[part 5 of 22: package /Cluster]
AUTOSAR XML (schema 4-3-0)
package /Cluster  (continued)
  can cluster E3V_K2CANFD: baudrate=500000, protocol-name=CAN, protocol-version=2.0, bus-off-recovery={bor-counter-l-1-to-l-2=1, bor-time-l-1=0.05, bor-time-l-2=0.2}, can-fd-baudrate=500000  (continued)
    can physical channel CHNL: comm-connectors=CN_E3V_K2CANFD  (continued)
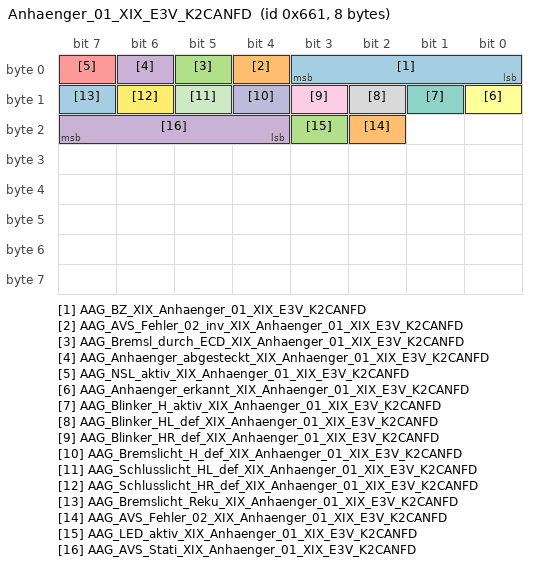
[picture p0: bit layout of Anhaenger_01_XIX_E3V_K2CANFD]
      frame Anhaenger_01_XIX_E3V_K2CANFD: id 0x661, to SAM, frame-length=8, can-addressing-mode=STANDARD, can-frame-rx-behavior=CAN-FD, can-frame-tx-behavior=CAN-FD
        pdu Anhaenger_01_XIX_E3V_K2CANFD: length=8, transmission-mode-true-timing=cyclic-timing={time-offset=0.0, time-period=0.1}, unused-bit-pattern=0  # ab MQB 7.2
          signal AAG_BZ_XIX_Anhaenger_01_XIX_E3V_K2CANFD: start 0, 4 bit, little-endian, data-type-policy=OVERRIDE, i-signal-type=PRIMITIVE, base-type=BT_AAG_BZ, compu {phys=raw for raw 0..15}, range phys 0..15, raw 0..15, transfer-property=PENDING  # 4bit-Botschaftszaehler, wird in jeder Sendebotschaft inkrementiert
          signal AAG_AVS_Fehler_02_inv_XIX_Anhaenger_01_XIX_E3V_K2CANFD: start 4, 1 bit, little-endian, data-type-policy=OVERRIDE, i-signal-type=PRIMITIVE, init-value=1, base-type=BT_AAG_AVS_Fehler_02_inv, invalid-value=Invalid_AAG_AVS_Fehler_02_inv_XIX_Anhaenger_01_XIX_E3V_K2CANFD:0, compu {0=Cx0_Fehler (CM_AAG_AVS_Fehler_02_inv_Cx0_Fehler), 1=Cx1_kein_Fehler (CM_AAG_AVS_Fehler_02_inv_Cx1_kein_Fehler)}, range raw 0..1, transfer-property=PENDING  # Fehler AVS (inverses Signal)
          signal AAG_Bremsl_durch_ECD_XIX_Anhaenger_01_XIX_E3V_K2CANFD: start 5, 1 bit, little-endian, data-type-policy=OVERRIDE, i-signal-type=PRIMITIVE, init-value=0, base-type=BT_AAG_Bremsl_durch_ECD, compu {0=Cx0_Bremslicht_ist_aus (CM_AAG_Bremsl_durch_ECD_Cx0_Bremslicht_ist_aus), 1=Cx1_Bremslicht_durch_ECD_aktiv (CM_AAG_Bremsl_durch_ECD_Cx1_Bremslicht_durch_ECD_aktiv)}, range raw 0..1, transfer-property=PENDING  # Bremslicht durch ECD aktiv
          signal AAG_Anhaenger_abgesteckt_XIX_Anhaenger_01_XIX_E3V_K2CANFD: start 6, 1 bit, little-endian, data-type-policy=OVERRIDE, i-signal-type=PRIMITIVE, init-value=0, base-type=BT_AAG_Anhaenger_abgesteckt, compu {0=Cx0_Init (CM_AAG_Anhaenger_abgesteckt_Cx0_Init), 1=Cx1_Anhaenger_wurde_bei_KL15_aus_abgesteckt (CM_AAG_Anhaenger_abgesteckt_Cx1_Anhaenger_wurde_bei_KL15_aus_abgesteckt)}, range raw 0..1, transfer-property=PENDING  # Anhaenger wurde bei Kl. 15 aus abgesteckt
          signal AAG_NSL_aktiv_XIX_Anhaenger_01_XIX_E3V_K2CANFD: start 7, 1 bit, little-endian, data-type-policy=OVERRIDE, i-signal-type=PRIMITIVE, init-value=0, base-type=BT_AAG_NSL_aktiv, compu {0=Cx0_Init (CM_AAG_NSL_aktiv_Cx0_Init), 1=Cx1_Anhaenger_Nebelschusslicht_aktiv (CM_AAG_NSL_aktiv_Cx1_Anhaenger_Nebelschusslicht_aktiv)}, range raw 0..1, transfer-property=PENDING  # Anhaenger Nebelschlusslicht aktiv
          signal AAG_Anhaenger_erkannt_XIX_Anhaenger_01_XIX_E3V_K2CANFD: start 8, 1 bit, little-endian, data-type-policy=OVERRIDE, i-signal-type=PRIMITIVE, init-value=0, base-type=BT_AAG_Anhaenger_erkannt, compu {0=Cx0_kein_Anhaenger_erkannt (CM_AAG_Anhaenger_erkannt_Cx0_kein_Anhaenger_erkannt), 1=Cx1_AAG_Anhaenger_erkannt (CM_AAG_Anhaenger_erkannt_Cx1_AAG_Anhaenger_erkannt)}, range raw 0..1, transfer-property=PENDING, to SAM(timeout 1 s)  # Erkennung Anhaenger
          signal AAG_Blinker_H_aktiv_XIX_Anhaenger_01_XIX_E3V_K2CANFD: start 9, 1 bit, little-endian, data-type-policy=OVERRIDE, i-signal-type=PRIMITIVE, init-value=0, base-type=BT_AAG_Blinker_H_aktiv, compu {0=Cx0_Init (CM_AAG_Blinker_H_aktiv_Cx0_Init), 1=Cx1_Anhaenger_Blinker_aktiv (CM_AAG_Blinker_H_aktiv_Cx1_Anhaenger_Blinker_aktiv)}, range raw 0..1, transfer-property=PENDING  # Status: Anhaenger Blinker aktiv
          signal AAG_Blinker_HL_def_XIX_Anhaenger_01_XIX_E3V_K2CANFD: start 10, 1 bit, little-endian, data-type-policy=OVERRIDE, i-signal-type=PRIMITIVE, init-value=0, base-type=BT_AAG_Blinker_HL_def, compu {0=Cx0_Init (CM_AAG_Blinker_HL_def_Cx0_Init), 1=Cx1_Anhaenger_Blinker_links_defekt (CM_AAG_Blinker_HL_def_Cx1_Anhaenger_Blinker_links_defekt)}, range raw 0..1, transfer-property=PENDING  # Anhaenger Blinker links defekt
          signal AAG_Blinker_HR_def_XIX_Anhaenger_01_XIX_E3V_K2CANFD: start 11, 1 bit, little-endian, data-type-policy=OVERRIDE, i-signal-type=PRIMITIVE, init-value=0, base-type=BT_AAG_Blinker_HR_def, compu {0=Cx0_Init (CM_AAG_Blinker_HR_def_Cx0_Init), 1=Cx1_Anhaenger_Blinker_rechts_defekt (CM_AAG_Blinker_HR_def_Cx1_Anhaenger_Blinker_rechts_defekt)}, range raw 0..1, transfer-property=PENDING  # Anhaenger Blinker rechts defekt
          signal AAG_Bremslicht_H_def_XIX_Anhaenger_01_XIX_E3V_K2CANFD: start 12, 1 bit, little-endian, data-type-policy=OVERRIDE, i-signal-type=PRIMITIVE, init-value=0, base-type=BT_AAG_Bremslicht_H_def, compu {0=Cx0_Init (CM_AAG_Bremslicht_H_def_Cx0_Init), 1=Cx1_Anhaenger_Bremslicht_defekt (CM_AAG_Bremslicht_H_def_Cx1_Anhaenger_Bremslicht_defekt)}, range raw 0..1, transfer-property=PENDING  # Anhaenger Bremslicht defekt
          signal AAG_Schlusslicht_HL_def_XIX_Anhaenger_01_XIX_E3V_K2CANFD: start 13, 1 bit, little-endian, data-type-policy=OVERRIDE, i-signal-type=PRIMITIVE, init-value=0, base-type=BT_AAG_Schlusslicht_HL_def, compu {0=Cx0_Init (CM_AAG_Schlusslicht_HL_def_Cx0_Init), 1=Cx1_Anhaenger_Schlusslicht_links_defekt (CM_AAG_Schlusslicht_HL_def_Cx1_Anhaenger_Schlusslicht_links_defekt)}, range raw 0..1, transfer-property=PENDING  # Anhaenger Schlußlicht links defekt
          signal AAG_Schlusslicht_HR_def_XIX_Anhaenger_01_XIX_E3V_K2CANFD: start 14, 1 bit, little-endian, data-type-policy=OVERRIDE, i-signal-type=PRIMITIVE, init-value=0, base-type=BT_AAG_Schlusslicht_HR_def, compu {0=Cx0_Init (CM_AAG_Schlusslicht_HR_def_Cx0_Init), 1=Cx1_Anhaenger_Schlusslicht_rechts_defekt (CM_AAG_Schlusslicht_HR_def_Cx1_Anhaenger_Schlusslicht_rechts_defekt)}, range raw 0..1, transfer-property=PENDING  # Anhaenger Schlußlicht rechts defekt
          signal AAG_Bremslicht_Reku_XIX_Anhaenger_01_XIX_E3V_K2CANFD: start 15, 1 bit, little-endian, data-type-policy=OVERRIDE, i-signal-type=PRIMITIVE, init-value=0, base-type=BT_AAG_Bremslicht_Reku, compu {0=Cx0_inaktiv (CM_AAG_Bremslicht_Reku_Cx0_inaktiv), 1=Cx1_aktiv (CM_AAG_Bremslicht_Reku_Cx1_aktiv)}, range raw 0..1, transfer-property=PENDING  # AAG_Bremslicht_Reku meldet zyklisch den empfangenen Zustand des CAN-Signals MO_Bremslicht_Reku zurück.
          signal AAG_AVS_Fehler_02_XIX_Anhaenger_01_XIX_E3V_K2CANFD: start 18, 1 bit, little-endian, data-type-policy=OVERRIDE, i-signal-type=PRIMITIVE, init-value=0, base-type=BT_AAG_AVS_Fehler_02, invalid-value=Invalid_AAG_AVS_Fehler_02_XIX_Anhaenger_01_XIX_E3V_K2CANFD:1, compu {0=Cx0_kein_Fehler (CM_AAG_AVS_Fehler_02_Cx0_kein_Fehler), 1=Cx1_Fehler (CM_AAG_AVS_Fehler_02_Cx1_Fehler)}, range raw 0..1, transfer-property=PENDING  # Fehler AVS
          signal AAG_LED_aktiv_XIX_Anhaenger_01_XIX_E3V_K2CANFD: start 19, 1 bit, little-endian, data-type-policy=OVERRIDE, i-signal-type=PRIMITIVE, init-value=0, base-type=BT_AAG_LED_aktiv, compu {0=Cx0_Lampen (CM_AAG_LED_aktiv_Cx0_Lampen), 1=Cx1_LED (CM_AAG_LED_aktiv_Cx1_LED)}, range raw 0..1, transfer-property=PENDING  # Dieses Signal sendet der Beleuchtungsart des Anhängers (LED oder Lampe) Bei LED aktiv erfolgt kein Kaltüberwachung
          signal AAG_AVS_Stati_XIX_Anhaenger_01_XIX_E3V_K2CANFD: start 20, 4 bit, little-endian, data-type-policy=OVERRIDE, i-signal-type=PRIMITIVE, init-value=0, base-type=BT_AAG_AVS_Stati, compu {0=Cx0_endlage_eingefahren_erreicht (CM_AAG_AVS_Stati_Cx0_endlage_eingefahren_erreicht), 1=Cx1_endlage_ausgefahren_erreicht (CM_AAG_AVS_Stati_Cx1_endlage_ausgefahren_erreicht), 2=Cx2_ausfahren_automatik (CM_AAG_AVS_Stati_Cx2_ausfahren_automatik), 3=Cx3_einfahren_automatik (CM_AAG_AVS_Stati_Cx3_einfahren_automatik), 4=Cx4_ausfahren_manuell (CM_AAG_AVS_Stati_Cx4_ausfahren_manuell), 5=Cx5_einfahren_manuell (CM_AAG_AVS_Stati_Cx5_einfahren_manuell), 6=Cx6_zwischenposition (CM_AAG_AVS_Stati_Cx6_zwischenposition), 7=Cx7_nicht_initialisiert (CM_AAG_AVS_Stati_Cx7_nicht_initialisiert)}, range raw 0..7, transfer-property=PENDING  # Status AVS (bei abnehmbarer oder mech.schwenkbarer Anhängerkupplung ist der Status immer 0)
      frame BAP_Aussenlicht2_ASG_01_XIX_E3V_K2CANFD: id 0x17336B00, to SAM, frame-length=8, can-addressing-mode=EXTENDED, can-frame-rx-behavior=CAN-FD, can-frame-tx-behavior=CAN-FD
        user defined pdu CDD_BAP_Aussenlicht2_ASG_01_XIX_E3V_K2CANFD: length=8, cdd-type=BAP
      frame BAP_Aussenlicht2_ASG_02_XIX_E3V_K2CANFD: id 0x17336B01, to SAM, frame-length=8, can-addressing-mode=EXTENDED, can-frame-rx-behavior=CAN-FD, can-frame-tx-behavior=CAN-FD
        user defined pdu CDD_BAP_Aussenlicht2_ASG_02_XIX_E3V_K2CANFD: length=8, cdd-type=BAP
      frame BAP_Aussenlicht2_FSG_01_XIX_E3V_K2CANFD: id 0x17336B10, from SAM, frame-length=8, can-addressing-mode=EXTENDED, can-frame-rx-behavior=CAN-FD, can-frame-tx-behavior=CAN-FD
        user defined pdu CDD_BAP_Aussenlicht2_FSG_01_XIX_E3V_K2CANFD: length=8, cdd-type=BAP
      frame BAP_Debug_Cmd_XIX_E3V_K2CANFD: id 0x1733FF20, to SAM, frame-length=8, can-addressing-mode=EXTENDED, can-frame-rx-behavior=CAN-FD, can-frame-tx-behavior=CAN-FD
        user defined pdu CDD_BAP_Debug_Cmd_XIX_E3V_K2CANFD: length=8, cdd-type=BAP
      frame BAP_Debug_Data_XIX_E3V_K2CANFD: id 0x1733FF30, from SAM, frame-length=8, can-addressing-mode=EXTENDED, can-frame-rx-behavior=CAN-FD, can-frame-tx-behavior=CAN-FD
        user defined pdu CDD_BAP_Debug_Data_XIX_E3V_K2CANFD: length=8, cdd-type=BAP
      frame BAP_Homelink_ASG_01_XIX_E3V_K2CANFD: id 0x17331400, to SAM, frame-length=8, can-addressing-mode=EXTENDED, can-frame-rx-behavior=CAN-FD, can-frame-tx-behavior=CAN-FD
        user defined pdu CDD_BAP_Homelink_ASG_01_XIX_E3V_K2CANFD: length=8, cdd-type=BAP
      frame BAP_Homelink_FSG_01_XIX_E3V_K2CANFD: id 0x17331410, from SAM, frame-length=8, can-addressing-mode=EXTENDED, can-frame-rx-behavior=CAN-FD, can-frame-tx-behavior=CAN-FD
        user defined pdu CDD_BAP_Homelink_FSG_01_XIX_E3V_K2CANFD: length=8, cdd-type=BAP
      frame BAP_Innenlicht_ASG_01_XIX_E3V_K2CANFD: id 0x17330800, to SAM, frame-length=8, can-addressing-mode=EXTENDED, can-frame-rx-behavior=CAN-FD, can-frame-tx-behavior=CAN-FD
        user defined pdu CDD_BAP_Innenlicht_ASG_01_XIX_E3V_K2CANFD: length=8, cdd-type=BAP
      frame BAP_Innenlicht_ASG_03_XIX_E3V_K2CANFD: id 0x17330802, to SAM, frame-length=8, can-addressing-mode=EXTENDED, can-frame-rx-behavior=CAN-FD, can-frame-tx-behavior=CAN-FD
        user defined pdu CDD_BAP_Innenlicht_ASG_03_XIX_E3V_K2CANFD: length=8, cdd-type=BAP
      frame BAP_Innenlicht_FSG_01_XIX_E3V_K2CANFD: id 0x17330810, from SAM, frame-length=8, can-addressing-mode=EXTENDED, can-frame-rx-behavior=CAN-FD, can-frame-tx-behavior=CAN-FD
        user defined pdu CDD_BAP_Innenlicht_FSG_01_XIX_E3V_K2CANFD: length=8, cdd-type=BAP
      frame BAP_SeatPneumatic_ASG_01_XIX_E3V_K2CANFD: id 0x17333B00, to SAM, frame-length=8, can-addressing-mode=EXTENDED, can-frame-rx-behavior=CAN-FD, can-frame-tx-behavior=CAN-FD
        user defined pdu CDD_BAP_SeatPneumatic_ASG_01_XIX_E3V_K2CANFD: length=8, cdd-type=BAP
      frame BAP_SeatPneumatic_ASG_02_XIX_E3V_K2CANFD: id 0x17333B01, to SAM, frame-length=8, can-addressing-mode=EXTENDED, can-frame-rx-behavior=CAN-FD, can-frame-tx-behavior=CAN-FD
        user defined pdu CDD_BAP_SeatPneumatic_ASG_02_XIX_E3V_K2CANFD: length=8, cdd-type=BAP
      frame BAP_SeatPneumatic_FSG_01_XIX_E3V_K2CANFD: id 0x17333B10, from SAM, frame-length=8, can-addressing-mode=EXTENDED, can-frame-rx-behavior=CAN-FD, can-frame-tx-behavior=CAN-FD
        user defined pdu CDD_BAP_SeatPneumatic_FSG_01_XIX_E3V_K2CANFD: length=8, cdd-type=BAP
      frame BAP_Wiper_ASG_01_XIX_E3V_K2CANFD: id 0x17330C00, to SAM, frame-length=8, can-addressing-mode=EXTENDED, can-frame-rx-behavior=CAN-FD, can-frame-tx-behavior=CAN-FD
        user defined pdu CDD_BAP_Wiper_ASG_01_XIX_E3V_K2CANFD: length=8, cdd-type=BAP
      frame BAP_Wiper_ASG_02_XIX_E3V_K2CANFD: id 0x17330C01, to SAM, frame-length=8, can-addressing-mode=EXTENDED, can-frame-rx-behavior=CAN-FD, can-frame-tx-behavior=CAN-FD
        user defined pdu CDD_BAP_Wiper_ASG_02_XIX_E3V_K2CANFD: length=8, cdd-type=BAP
      frame BAP_Wiper_FSG_01_XIX_E3V_K2CANFD: id 0x17330C10, from SAM, frame-length=8, can-addressing-mode=EXTENDED, can-frame-rx-behavior=CAN-FD, can-frame-tx-behavior=CAN-FD
        user defined pdu CDD_BAP_Wiper_FSG_01_XIX_E3V_K2CANFD: length=8, cdd-type=BAP
      frame BCM_01_XIX_E3V_K2CANFD: id 0x65A, from SAM, frame-length=8, can-addressing-mode=STANDARD, can-frame-rx-behavior=CAN-FD, can-frame-tx-behavior=CAN-FD
        pdu BCM_01_XIX_E3V_K2CANFD_E2E: length=8, minimum-delay=0.03, transmission-mode-true-timing=event-controlled-timing={number-of-repetitions=0, repetition-period=0.0}, unused-bit-pattern=0  # Fuer die Botschaft ist das Cyclic-Timing 1.0 zu verwenden.
          signal BCM_01_CRC_XIX_BCM_01_XIX_E3V_K2CANFD: start 0, 8 bit, little-endian, data-type-policy=OVERRIDE, i-signal-type=PRIMITIVE, base-type=BT_BCM_01_CRC, compu {phys=raw for raw 0..255}, range phys 0..255, raw 0..255  # Für MLB: "Berechnung siehe Lastenheft "Kommunikationsabsicherung für FlexRay und CAN"" Ab MQB und MLBevo: "Berechnung siehe Lastenheft "End-to-End Kommunikationsabsicherung"" Endwerte siehe Begleitdokument "S-PDU Kennungsfolgen"
          signal BCM_01_BZ_XIX_BCM_01_XIX_E3V_K2CANFD: start 8, 4 bit, little-endian, data-type-policy=OVERRIDE, i-signal-type=PRIMITIVE, base-type=BT_BCM_01_BZ, compu {phys=raw for raw 0..15}, range phys 0..15, raw 0..15  # 4bit Botschaftszaehler; wird in jeder Sendebotschaft inkrementiert
          signal BCM_Bremsbelag_Sensor_XIX_BCM_01_XIX_E3V_K2CANFD: start 12, 1 bit, little-endian, data-type-policy=OVERRIDE, i-signal-type=PRIMITIVE, init-value=0, base-type=BT_BCM_Bremsbelag_Sensor, compu {0=Cx0_OK (CM_BCM_Bremsbelag_Sensor_Cx0_OK), 1=Cx1_Bremsbelag_unter_min (CM_BCM_Bremsbelag_Sensor_Cx1_Bremsbelag_unter_min)}, range raw 0..1  # Sensorsignal der Stromschleife für Bremsbelagverschleiß aktuell, entstört, unbewertet
          signal BCM_Bremsfluessigkeit_Sensor_XIX_BCM_01_XIX_E3V_K2CANFD: start 13, 1 bit, little-endian, data-type-policy=OVERRIDE, i-signal-type=PRIMITIVE, init-value=0, base-type=BT_BCM_Bremsfluessigkeit_Sensor, compu {0=Cx0_OK (CM_BCM_Bremsfluessigkeit_Sensor_Cx0_OK), 1=Cx1_Bremsfluessigkeit_unter_min (CM_BCM_Bremsfluessigkeit_Sensor_Cx1_Bremsfluessigkeit_unter_min)}, range raw 0..1  # Kontaktsignal des Sensorschalters für die Bremsflüssigkeitsreserve aktuell, entstört, unbewertet
          signal ISignalVoid_BCM_01_XIX_E3V_K2CANFD_0: start 14, 1 bit, little-endian, system signal SignalVoid_BCM_01_0, data-type-policy=OVERRIDE, i-signal-type=PRIMITIVE, base-type=BT_SignalVoid
          signal BCM_Waschwasser_Sensor_XIX_BCM_01_XIX_E3V_K2CANFD: start 15, 1 bit, little-endian, data-type-policy=OVERRIDE, i-signal-type=PRIMITIVE, init-value=0, base-type=BT_BCM_Waschwasser_Sensor, compu {0=Cx0_OK (CM_BCM_Waschwasser_Sensor_Cx0_OK), 1=Cx1_Waschwasser_unter_min (CM_BCM_Waschwasser_Sensor_Cx1_Waschwasser_unter_min)}, range raw 0..1  # Signal der Sensorelektroden für die Waschwasserreserve aktuell, entstört, bewertet (OK/Mangel)
          signal BCM_Kuehlmittel_Sensor_XIX_BCM_01_XIX_E3V_K2CANFD: start 16, 1 bit, little-endian, data-type-policy=OVERRIDE, i-signal-type=PRIMITIVE, init-value=0, base-type=BT_BCM_Kuehlmittel_Sensor, compu {0=Cx0_OK (CM_BCM_Kuehlmittel_Sensor_Cx0_OK), 1=Cx1_Kuehlmittel_unter_min (CM_BCM_Kuehlmittel_Sensor_Cx1_Kuehlmittel_unter_min)}, range raw 0..1  # Signal der Sensorelektroden für die Kühlmittelreserve aktuell, entstört, bewertet (OK/Mangel)
          signal BCM1_Kl_15_HW_erkannt_XIX_BCM_01_XIX_E3V_K2CANFD: start 17, 1 bit, little-endian, data-type-policy=OVERRIDE, i-signal-type=PRIMITIVE, init-value=0, base-type=BT_BCM1_Kl_15_HW_erkannt, compu {1=Cx1_Klemme_15_erkannt (CM_BCM1_Kl_15_HW_erkannt_Cx1_Klemme_15_erkannt) (Klemme 15 erkannt)}, range raw 1  # Erkennung Klemme 15 (Hardware) vom BCM1
          signal BCM1_Kl_15_Sig_HW_erkannt_XIX_BCM_01_XIX_E3V_K2CANFD: start 18, 1 bit, little-endian, data-type-policy=OVERRIDE, i-signal-type=PRIMITIVE, init-value=0, base-type=BT_BCM1_Kl_15_Sig_HW_erkannt, compu {0=Cx0_KL15_HW_Signal_von_BCM1_nicht_erkannt (CM_BCM1_Kl_15_Sig_HW_erkannt_Cx0_KL15_HW_Signal_von_BCM1_nicht_erkannt), 1=Cx1_KL15_HW_Signal_von_BCM1_erkannt (CM_BCM1_Kl_15_Sig_HW_erkannt_Cx1_KL15_HW_Signal_von_BCM1_erkannt)}, range raw 0..1  # Erkennung Klemme 15 Signal (Hardware) vom BCM1
          signal BCM_Kuehlmittel_Sensor_02_XIX_BCM_01_XIX_E3V_K2CANFD: start 19, 1 bit, little-endian, data-type-policy=OVERRIDE, i-signal-type=PRIMITIVE, init-value=0, base-type=BT_BCM_Kuehlmittel_Sensor_02, compu {0=Cx0_OK (CM_BCM_Kuehlmittel_Sensor_02_Cx0_OK), 1=Cx1_Kuehlmittel_unter_min (CM_BCM_Kuehlmittel_Sensor_02_Cx1_Kuehlmittel_unter_min)}, range raw 0..1  # Signal der zweiten Sensorelektroden für die Kühlmittelreserve aktuell, entstört, bewertet (OK/Mangel)
          signal ISignalVoid_BCM_01_XIX_E3V_K2CANFD_1: start 20, 1 bit, little-endian, system signal SignalVoid_BCM_01_1, data-type-policy=OVERRIDE, i-signal-type=PRIMITIVE, base-type=BT_SignalVoid
          signal BCM_Offroad_Taste_XIX_BCM_01_XIX_E3V_K2CANFD: start 21, 1 bit, little-endian, data-type-policy=OVERRIDE, i-signal-type=PRIMITIVE, init-value=0, base-type=BT_BCM_Offroad_Taste, compu {0=Cx0_Taster_nicht_betaetigt (CM_BCM_Offroad_Taste_Cx0_Taster_nicht_betaetigt), 1=Cx1_Taster_betaetigt (CM_BCM_Offroad_Taste_Cx1_Taster_betaetigt)}, range raw 0..1  # Betätigung der Offroad-Taste
          signal BCM_Charisma_Taste2_XIX_BCM_01_XIX_E3V_K2CANFD: start 22, 1 bit, little-endian, data-type-policy=OVERRIDE, i-signal-type=PRIMITIVE, init-value=0, base-type=BT_BCM_Charisma_Taste2, compu {0=Cx0_nicht_betaetigt (CM_BCM_Charisma_Taste2_Cx0_nicht_betaetigt), 1=Cx1_betaetigt (CM_BCM_Charisma_Taste2_Cx1_betaetigt)}, range raw 0..1  # Betätigung der Charisma-Taste 2
          signal BCM_Hybrid_StSt_Taste_Fehler_XIX_BCM_01_XIX_E3V_K2CANFD: start 23, 1 bit, little-endian, data-type-policy=OVERRIDE, i-signal-type=PRIMITIVE, init-value=0, base-type=BT_BCM_Hybrid_StSt_Taste_Fehler, compu {0=Cx0_kein_Fehler_StSt_Taster (CM_BCM_Hybrid_StSt_Taste_Fehler_Cx0_kein_Fehler_StSt_Taster), 1=Cx1_Fehler_StSt_Taster (CM_BCM_Hybrid_StSt_Taste_Fehler_Cx1_Fehler_StSt_Taster)}, range raw 0..1  # Fehlerflag, wenn Tasterdiagnose im BCM für den StSt-Taster anschlägt.
          signal BCM_Hybrid_StartStopp_Taste_XIX_BCM_01_XIX_E3V_K2CANFD: start 24, 1 bit, little-endian, data-type-policy=OVERRIDE, i-signal-type=PRIMITIVE, init-value=0, base-type=BT_BCM_Hybrid_StartStopp_Taste, compu {0=Cx0_nicht_betaetigt (CM_BCM_Hybrid_StartStopp_Taste_Cx0_nicht_betaetigt), 1=Cx1_betaetigt (CM_BCM_Hybrid_StartStopp_Taste_Cx1_betaetigt)}, range raw 0..1  # Betaetigung Taster "Hybrid" oder alternativ Taster "Start/Stopp Deaktivierung", je nach Verbau
          signal BCM1_Warnblink_Taster_XIX_BCM_01_XIX_E3V_K2CANFD: start 25, 1 bit, little-endian, data-type-policy=OVERRIDE, i-signal-type=PRIMITIVE, init-value=0, base-type=BT_BCM1_Warnblink_Taster, compu {0=Cx0_nicht_betaetigt (CM_BCM1_Warnblink_Taster_Cx0_nicht_betaetigt), 1=Cx1_betaetigt (CM_BCM1_Warnblink_Taster_Cx1_betaetigt)}, range raw 0..1  # Warnblinktaster
          signal BCM1_Valet_Parking_Taster_XIX_BCM_01_XIX_E3V_K2CANFD: start 26, 1 bit, little-endian, data-type-policy=OVERRIDE, i-signal-type=PRIMITIVE, init-value=0, base-type=BT_BCM1_Valet_Parking_Taster, compu {0=Cx0_nicht_betaetigt (CM_BCM1_Valet_Parking_Taster_Cx0_nicht_betaetigt), 1=Cx1_betaetigt (CM_BCM1_Valet_Parking_Taster_Cx1_betaetigt)}, range raw 0..1  # Valet Parking Taster
          signal ISignalVoid_BCM_01_XIX_E3V_K2CANFD_2: start 27, 3 bit, little-endian, system signal SignalVoid_BCM_01_2, data-type-policy=OVERRIDE, i-signal-type=PRIMITIVE, base-type=BT_SignalVoid
          signal BCM1_Rueckfahrlicht_Schalter_XIX_BCM_01_XIX_E3V_K2CANFD: start 30, 1 bit, little-endian, data-type-policy=OVERRIDE, i-signal-type=PRIMITIVE, init-value=0, base-type=BT_BCM1_Rueckfahrlicht_Schalter, compu {0=Cx0_nicht_betaetigt (CM_BCM1_Rueckfahrlicht_Schalter_Cx0_nicht_betaetigt), 1=Cx1_betaetigt (CM_BCM1_Rueckfahrlicht_Schalter_Cx1_betaetigt)}, range raw 0..1  # Rückfahrlichtschalter ab MQB/ MLBevo: Die Ganginformation wird unentprellt übertragen, im AT-Getriebe wird evtl. kurzzeitig der R-Gang angezeigt. Eine Entprellung muß im Empfänger erfolgen (typisch 400ms).
          signal BCM1_MH_Schalter_XIX_BCM_01_XIX_E3V_K2CANFD: start 31, 1 bit, little-endian, data-type-policy=OVERRIDE, i-signal-type=PRIMITIVE, init-value=0, base-type=BT_BCM1_MH_Schalter, compu {0=Cx0_MH_geschlossen (CM_BCM1_MH_Schalter_Cx0_MH_geschlossen), 1=Cx1_MH_offen (CM_BCM1_MH_Schalter_Cx1_MH_offen)}, range raw 0..1  # Motorhaubenkontakt
          signal BCM1_MH_WIV_Schalter_XIX_BCM_01_XIX_E3V_K2CANFD: start 32, 1 bit, little-endian, data-type-policy=OVERRIDE, i-signal-type=PRIMITIVE, init-value=0, base-type=BT_BCM1_MH_WIV_Schalter, compu {0=Cx0_MH_geschlossen (CM_BCM1_MH_WIV_Schalter_Cx0_MH_geschlossen), 1=Cx1_MH_offen (CM_BCM1_MH_WIV_Schalter_Cx1_MH_offen)}, range raw 0..1  # Bewerteter Motorhaubenkontakt fuer WIV
          signal BCM_Eco_Charisma_Taste_XIX_BCM_01_XIX_E3V_K2CANFD: start 33, 1 bit, little-endian, data-type-policy=OVERRIDE, i-signal-type=PRIMITIVE, init-value=0, base-type=BT_BCM_Eco_Charisma_Taste, compu {0=Cx0_nicht_betaetigt (CM_BCM_Eco_Charisma_Taste_Cx0_nicht_betaetigt), 1=Cx1_betaetigt (CM_BCM_Eco_Charisma_Taste_Cx1_betaetigt)}, range raw 0..1  # Betätigung Taster ECO alias BlueKey oder Charisma
          signal BCM1_NV_Taster_XIX_BCM_01_XIX_E3V_K2CANFD: start 34, 1 bit, little-endian, data-type-policy=OVERRIDE, i-signal-type=PRIMITIVE, init-value=0, base-type=BT_BCM1_NV_Taster, compu {0=Cx0_Taster_nicht_betaetigt (CM_BCM1_NV_Taster_Cx0_Taster_nicht_betaetigt), 1=Cx1_Taster_betaetigt (CM_BCM1_NV_Taster_Cx1_Taster_betaetigt)}, range raw 0..1  # BCM1_NV_Taster gibt an, ob der NightVision-Taster im Lichtdrehschalter-Modul aktuell betaetigt wird.
          signal BCM1_AFS_Lampe_XIX_BCM_01_XIX_E3V_K2CANFD: start 35, 1 bit, little-endian, data-type-policy=OVERRIDE, i-signal-type=PRIMITIVE, init-value=0, base-type=BT_BCM1_AFS_Lampe, compu {0=Cx0_Aus (CM_BCM1_AFS_Lampe_Cx0_Aus), 1=Cx1_Ein (CM_BCM1_AFS_Lampe_Cx1_Ein)}, range raw 0..1  # Ansteuerung der AFS-Fehlermeldung im Kombi
          signal BCM1_Reisemodus_Texte_XIX_BCM_01_XIX_E3V_K2CANFD: start 36, 2 bit, little-endian, data-type-policy=OVERRIDE, i-signal-type=PRIMITIVE, init-value=0, base-type=BT_BCM1_Reisemodus_Texte, compu {0=Cx0_keine_Anzeige (CM_BCM1_Reisemodus_Texte_Cx0_keine_Anzeige), 1=Cx1_Umschaltung_auf_Linksverkehr_aktiv (CM_BCM1_Reisemodus_Texte_Cx1_Umschaltung_auf_Linksverkehr_aktiv), 2=Cx2_Umschaltung_auf_Rechtsverkehr_aktiv (CM_BCM1_Reisemodus_Texte_Cx2_Umschaltung_auf_Rechtsverkehr_aktiv)}, range raw 0..2  # Ansteuerung der Reisemodus-Texte im Kombi
          signal ISignalVoid_BCM_01_XIX_E3V_K2CANFD_3: start 38, 2 bit, little-endian, system signal SignalVoid_BCM_01_3, data-type-policy=OVERRIDE, i-signal-type=PRIMITIVE, base-type=BT_SignalVoid
          signal Gong_TFL_Umschaltung_XIX_BCM_01_XIX_E3V_K2CANFD: start 40, 1 bit, little-endian, data-type-policy=OVERRIDE, i-signal-type=PRIMITIVE, init-value=0, base-type=BT_Gong_TFL_Umschaltung, compu {0=Cx0_kein_Gong (CM_Gong_TFL_Umschaltung_Cx0_kein_Gong), 1=Cx1_Gong_einmalig (CM_Gong_TFL_Umschaltung_Cx1_Gong_einmalig)}, range raw 0..1  # Aktivierung / Deaktivierung des TFL per Affengriff wird mit einem Gong im Kombi quittiert.
          signal ISignalVoid_BCM_01_XIX_E3V_K2CANFD_4: start 41, 1 bit, little-endian, system signal SignalVoid_BCM_01_4, data-type-policy=OVERRIDE, i-signal-type=PRIMITIVE, base-type=BT_SignalVoid
          signal BCM_ValetTaster_Fkts_LED_XIX_BCM_01_XIX_E3V_K2CANFD: start 42, 1 bit, little-endian, data-type-policy=OVERRIDE, i-signal-type=PRIMITIVE, init-value=0, base-type=BT_BCM_ValetTaster_Fkts_LED, compu {0=Cx0_LED_aus (CM_BCM_ValetTaster_Fkts_LED_Cx0_LED_aus), 1=Cx1_LED_ein (CM_BCM_ValetTaster_Fkts_LED_Cx1_LED_ein)}, range raw 0..1  # Im MQB beschreibt das Signal nur den Zustand der Funktion Valet Parking (aktiv/ inaktiv) Im MLBevo wird über das Signal zusätzlich die ValetTaster_Fkts_LED (an/ aus) gesteuert
          signal LRH_Taster_XIX_BCM_01_XIX_E3V_K2CANFD: start 43, 1 bit, little-endian, data-type-policy=OVERRIDE, i-signal-type=PRIMITIVE, init-value=0, base-type=BT_LRH_Taster, compu {0=Cx0_nicht_betaetigt (CM_LRH_Taster_Cx0_nicht_betaetigt), 1=Cx1_betaetigt (CM_LRH_Taster_Cx1_betaetigt)}, range raw 0..1  # Tasterbetätigung Lenkradheizung
          signal APS_Tongeber_defekt_XIX_BCM_01_XIX_E3V_K2CANFD: start 44, 1 bit, little-endian, data-type-policy=OVERRIDE, i-signal-type=PRIMITIVE, init-value=0, base-type=BT_APS_Tongeber_defekt, compu {0=Cx0_iO (CM_APS_Tongeber_defekt_Cx0_iO), 1=Cx1_defekt (CM_APS_Tongeber_defekt_Cx1_defekt)}, range raw 0..1  # Status APS-Tongeber zur HMI-Ansteuerng der RCTA-Funktion
          signal BCM1_EasyEntry_Status_XIX_BCM_01_XIX_E3V_K2CANFD: start 45, 1 bit, little-endian, data-type-policy=OVERRIDE, i-signal-type=PRIMITIVE, init-value=0, base-type=BT_BCM1_EasyEntry_Status, compu {0=Cx0_Aus (CM_BCM1_EasyEntry_Status_Cx0_Aus), 1=Cx1_Ein (CM_BCM1_EasyEntry_Status_Cx1_Ein)}, range raw 0..1  # Status EasyEntry für Lenksäule (wird auch von IVB verwendet)
          signal BCM1_Lenksaeule_aktiv_XIX_BCM_01_XIX_E3V_K2CANFD: start 46, 1 bit, little-endian, data-type-policy=OVERRIDE, i-signal-type=PRIMITIVE, init-value=0, base-type=BT_BCM1_Lenksaeule_aktiv, compu {0=Cx0_Lenksaeulenverstellung_nicht_aktiv (CM_BCM1_Lenksaeule_aktiv_Cx0_Lenksaeulenverstellung_nicht_aktiv) (Lenksaeulenverstellung nicht aktiv), 1=Cx1_Lenksaeulenverstellung_aktiv (CM_BCM1_Lenksaeule_aktiv_Cx1_Lenksaeulenverstellung_aktiv) (Lenksaeulenverstellung aktiv)}, range raw 0..1  # Lenksaeulenverstellung aktiv
          signal BCM1_Spannungs_Anf_XIX_BCM_01_XIX_E3V_K2CANFD: start 47, 2 bit, little-endian, data-type-policy=OVERRIDE, i-signal-type=PRIMITIVE, init-value=0, base-type=BT_BCM1_Spannungs_Anf, compu {0=Cx0_keine_Anforderung (CM_BCM1_Spannungs_Anf_Cx0_keine_Anforderung), 1=Cx1_Anforderung_Stufe_1 (CM_BCM1_Spannungs_Anf_Cx1_Anforderung_Stufe_1), 2=Cx2_Anforderung_Stufe_2 (CM_BCM1_Spannungs_Anf_Cx2_Anforderung_Stufe_2), 3=Cx3_Anforderung_Stufe_3 (CM_BCM1_Spannungs_Anf_Cx3_Anforderung_Stufe_3)}, range raw 0..3  # Forderung des BCM1-SG's zur Spannungsanhebung.
          signal ISignalVoid_BCM_01_XIX_E3V_K2CANFD_5: start 49, 7 bit, little-endian, system signal SignalVoid_BCM_01_5, data-type-policy=OVERRIDE, i-signal-type=PRIMITIVE, base-type=BT_SignalVoid
          signal ISignalVoid_BCM_01_XIX_E3V_K2CANFD_6: start 56, 2 bit, little-endian, system signal SignalVoid_BCM_01_6, data-type-policy=OVERRIDE, i-signal-type=PRIMITIVE, base-type=BT_SignalVoid
          signal BCM_Anf_AAW_MoLaWa_XIX_BCM_01_XIX_E3V_K2CANFD: start 58, 2 bit, little-endian, data-type-policy=OVERRIDE, i-signal-type=PRIMITIVE, init-value=0, base-type=BT_BCM_Anf_AAW_MoLaWa, compu {0=Cx0_Init (CM_BCM_Anf_AAW_MoLaWa_Cx0_Init), 1=Cx1_AAW_angefordert (CM_BCM_Anf_AAW_MoLaWa_Cx1_AAW_angefordert), 2=Cx2_MoLaWa_angefordert (CM_BCM_Anf_AAW_MoLaWa_Cx2_MoLaWa_angefordert)}, range raw 0..2  # Signal zur Anforderung der Antrieb-Aktiv-Warnung und Motorlaufwarnung. Die Berechnung erfolgt im BCM. Die Ausgabe der Warnungen wird vom Kombiinstrument realisiert
          signal BCM_Handbremse_Hinweis_XIX_BCM_01_XIX_E3V_K2CANFD: start 60, 1 bit, little-endian, data-type-policy=OVERRIDE, i-signal-type=PRIMITIVE, init-value=0, base-type=BT_BCM_Handbremse_Hinweis, compu {0=Cx0_inaktiv (CM_BCM_Handbremse_Hinweis_Cx0_inaktiv), 1=Cx1_aktiv (CM_BCM_Handbremse_Hinweis_Cx1_aktiv)}, range raw 0..1  # Infotext fuer das Kombiinstrument zur Oeffnung der elektr. Heckklappe.
          signal ISignalVoid_BCM_01_XIX_E3V_K2CANFD_7: start 61, 2 bit, little-endian, system signal SignalVoid_BCM_01_7, data-type-policy=OVERRIDE, i-signal-type=PRIMITIVE, base-type=BT_SignalVoid
          signal BCM_HDF_betaetigt_XIX_BCM_01_XIX_E3V_K2CANFD: start 63, 1 bit, little-endian, data-type-policy=OVERRIDE, i-signal-type=PRIMITIVE, init-value=0, base-type=BT_BCM_HDF_betaetigt, compu {0=Cx0_nicht_betaetigt (CM_BCM_HDF_betaetigt_Cx0_nicht_betaetigt), 1=Cx1_betaetigt (CM_BCM_HDF_betaetigt_Cx1_betaetigt)}, range raw 0..1  # Betätigung Taster für Heckdeckelfernentriegelung in Mittelkonsole
          mapping SG_BCM_01_XIX_E3V_K2CANFD: i-signal-group=SG_BCM_01_XIX_E3V_K2CANFD, transfer-property=TRIGGERED-WITHOUT-REPETITION
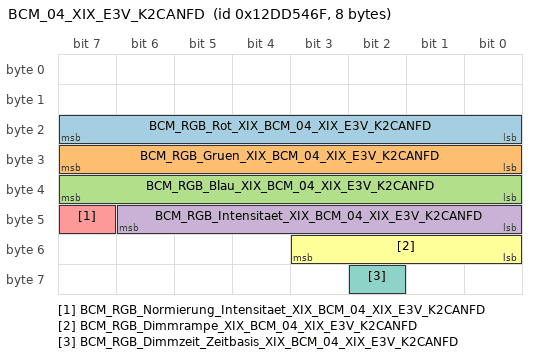
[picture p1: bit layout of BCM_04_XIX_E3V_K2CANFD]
      frame BCM_04_XIX_E3V_K2CANFD: id 0x12DD546F, from SAM, frame-length=8, can-addressing-mode=EXTENDED, can-frame-rx-behavior=CAN-FD, can-frame-tx-behavior=CAN-FD
        pdu BCM_04_XIX_E3V_K2CANFD: length=8, minimum-delay=0.02, transmission-mode-true-timing={cyclic-timing={time-offset=0.0, time-period=0.2}, event-controlled-timing={number-of-repetitions=0, repetition-period=0.0}}, unused-bit-pattern=0
          signal BCM_RGB_Rot_XIX_BCM_04_XIX_E3V_K2CANFD: start 16, 8 bit, little-endian, data-type-policy=OVERRIDE, i-signal-type=PRIMITIVE, base-type=BT_BCM_RGB_Rot, compu {phys=raw for raw 0..255}, range phys 0..255, raw 0..255, transfer-property=TRIGGERED-ON-CHANGE-WITHOUT-REPETITION  # Farbanteil "Rot"
          signal BCM_RGB_Gruen_XIX_BCM_04_XIX_E3V_K2CANFD: start 24, 8 bit, little-endian, data-type-policy=OVERRIDE, i-signal-type=PRIMITIVE, base-type=BT_BCM_RGB_Gruen, compu {phys=raw for raw 0..255}, range phys 0..255, raw 0..255, transfer-property=TRIGGERED-ON-CHANGE-WITHOUT-REPETITION  # Farbanteil "Grün"
          signal BCM_RGB_Blau_XIX_BCM_04_XIX_E3V_K2CANFD: start 32, 8 bit, little-endian, data-type-policy=OVERRIDE, i-signal-type=PRIMITIVE, base-type=BT_BCM_RGB_Blau, compu {phys=raw for raw 0..255}, range phys 0..255, raw 0..255, transfer-property=TRIGGERED-ON-CHANGE-WITHOUT-REPETITION  # Farbanteil "Blau"
          signal BCM_RGB_Intensitaet_XIX_BCM_04_XIX_E3V_K2CANFD: start 40, 7 bit, little-endian, data-type-policy=OVERRIDE, i-signal-type=PRIMITIVE, init-value=126, base-type=BT_BCM_RGB_Intensitaet, invalid-value=Invalid_BCM_RGB_Intensitaet_XIX_BCM_04_XIX_E3V_K2CANFD:127, compu {phys=raw for raw 0..100, 126=Cx7e_Init (CM_BCM_RGB_Intensitaet_Cx7e_Init), 127=Cx7f_Fehler (CM_BCM_RGB_Intensitaet_Cx7f_Fehler); unit Unit_PerCent}, range phys 0..100 Unit_PerCent, raw 0..127, unit=Unit_PerCent, transfer-property=PENDING  # Intensität für RGB-Slave
          signal BCM_RGB_Normierung_Intensitaet_XIX_BCM_04_XIX_E3V_K2CANFD: start 47, 1 bit, little-endian, data-type-policy=OVERRIDE, i-signal-type=PRIMITIVE, base-type=BT_BCM_RGB_Normierung_Intensitaet, compu {0=Cx0_ohne_Normierung (CM_BCM_RGB_Normierung_Intensitaet_Cx0_ohne_Normierung) (ohne Normierung), 1=Cx1_Normierung_der_Intensitaet (CM_BCM_RGB_Normierung_Intensitaet_Cx1_Normierung_der_Intensitaet) (Normierung der Intensität)}, range raw 0..1, transfer-property=PENDING  # Normierung der Intensität für die RGB-Slaves: 0 = keine Normierung 1 = Normierung
          signal BCM_RGB_Dimmrampe_XIX_BCM_04_XIX_E3V_K2CANFD: start 48, 4 bit, little-endian, data-type-policy=OVERRIDE, i-signal-type=PRIMITIVE, base-type=BT_BCM_RGB_Dimmrampe, compu {phys=raw*0.25 for raw 0..15; unit Unit_Secon}, range phys 0..3.75 Unit_Secon, raw 0..15, unit=Unit_Secon, transfer-property=PENDING  # Vorgabe "Dimmzeit" für RGB-Slave
          signal BCM_RGB_Dimmzeit_Zeitbasis_XIX_BCM_04_XIX_E3V_K2CANFD: start 58, 1 bit, little-endian, data-type-policy=OVERRIDE, i-signal-type=PRIMITIVE, init-value=0, base-type=BT_BCM_RGB_Dimmzeit_Zeitbasis, compu {0=Cx0_Zeitbasis_50ms (CM_BCM_RGB_Dimmzeit_Zeitbasis_Cx0_Zeitbasis_50ms), 1=Cx1_Zeitbasis_250ms (CM_BCM_RGB_Dimmzeit_Zeitbasis_Cx1_Zeitbasis_250ms)}, range raw 0..1, transfer-property=PENDING  # Umschaltung der Zeitbasis für die Berechnung der Dimmzeit zwischen 250ms (Altwert, log. Signalwert: 1) und 50ms (log. Signalwert: 0)
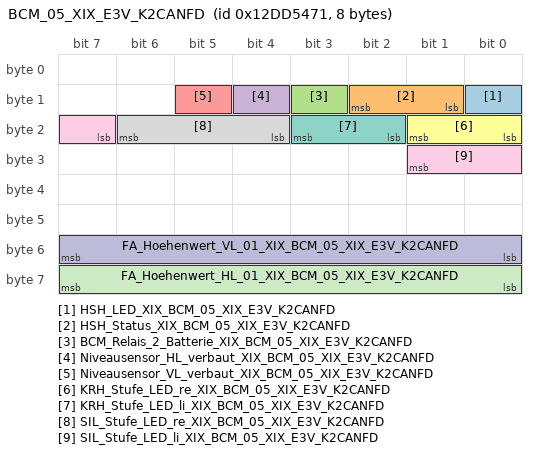
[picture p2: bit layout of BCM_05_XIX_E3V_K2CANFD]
      frame BCM_05_XIX_E3V_K2CANFD: id 0x12DD5471, from SAM, frame-length=8, can-addressing-mode=EXTENDED, can-frame-rx-behavior=CAN-FD, can-frame-tx-behavior=CAN-FD
        pdu BCM_05_XIX_E3V_K2CANFD: length=8, minimum-delay=0.02, transmission-mode-true-timing={cyclic-timing={time-offset=0.0, time-period=0.2}, event-controlled-timing={number-of-repetitions=0, repetition-period=0.0}}, unused-bit-pattern=0
          signal HSH_LED_XIX_BCM_05_XIX_E3V_K2CANFD: start 8, 1 bit, little-endian, data-type-policy=OVERRIDE, i-signal-type=PRIMITIVE, init-value=0, base-type=BT_HSH_LED, compu {0=Cx0_Aus (CM_HSH_LED_Cx0_Aus), 1=Cx1_Ein (CM_HSH_LED_Cx1_Ein)}, range raw 0..1, transfer-property=TRIGGERED-ON-CHANGE-WITHOUT-REPETITION  # LED Ansteuerung Heckscheibenheizung
          signal HSH_Status_XIX_BCM_05_XIX_E3V_K2CANFD: start 9, 2 bit, little-endian, data-type-policy=OVERRIDE, i-signal-type=PRIMITIVE, init-value=0, base-type=BT_HSH_Status, compu {0=Cx0_aus (CM_HSH_Status_Cx0_aus), 1=Cx1_ein (CM_HSH_Status_Cx1_ein), 2=Cx2_tbd (CM_HSH_Status_Cx2_tbd), 3=Cx3_Fehler (CM_HSH_Status_Cx3_Fehler)}, range raw 0..3, transfer-property=PENDING  # Status Heckscheibenheizung
          signal BCM_Relais_2_Batterie_XIX_BCM_05_XIX_E3V_K2CANFD: start 11, 1 bit, little-endian, data-type-policy=OVERRIDE, i-signal-type=PRIMITIVE, init-value=0, base-type=BT_BCM_Relais_2_Batterie, compu {0=Cx0_nicht_betaetigt (CM_BCM_Relais_2_Batterie_Cx0_nicht_betaetigt), 1=Cx1_betaetigt (CM_BCM_Relais_2_Batterie_Cx1_betaetigt)}, range raw 0..1, transfer-property=TRIGGERED-ON-CHANGE-WITHOUT-REPETITION  # Zeigt den Zustand des vom BCM bzw KFG angesteuerten Laderelais einer verbauten 2. Batterie an
          signal Niveausensor_HL_verbaut_XIX_BCM_05_XIX_E3V_K2CANFD: start 12, 1 bit, little-endian, data-type-policy=OVERRIDE, i-signal-type=PRIMITIVE, init-value=0, base-type=BT_Niveausensor_HL_verbaut, compu {0=Cx0_nicht_verbaut (CM_Niveausensor_HL_verbaut_Cx0_nicht_verbaut), 1=Cx1_verbaut (CM_Niveausensor_HL_verbaut_Cx1_verbaut)}, range raw 0..1, transfer-property=TRIGGERED-ON-CHANGE-WITHOUT-REPETITION  # Signal wird gesetzt, wenn Niveausensor_hinten codiert wird.
          signal Niveausensor_VL_verbaut_XIX_BCM_05_XIX_E3V_K2CANFD: start 13, 1 bit, little-endian, data-type-policy=OVERRIDE, i-signal-type=PRIMITIVE, init-value=0, base-type=BT_Niveausensor_VL_verbaut, compu {0=Cx0_nicht_verbaut (CM_Niveausensor_VL_verbaut_Cx0_nicht_verbaut), 1=Cx1_verbaut (CM_Niveausensor_VL_verbaut_Cx1_verbaut)}, range raw 0..1, transfer-property=TRIGGERED-ON-CHANGE-WITHOUT-REPETITION  # Signal wird gesetzt, wenn Niveausensor_vorne codiert wird.
          signal KRH_Stufe_LED_re_XIX_BCM_05_XIX_E3V_K2CANFD: start 16, 2 bit, little-endian, data-type-policy=OVERRIDE, i-signal-type=PRIMITIVE, init-value=0, base-type=BT_KRH_Stufe_LED_re, compu {0=Cx0_Aus (CM_KRH_Stufe_LED_re_Cx0_Aus), 1=Cx1_Stufe_1 (CM_KRH_Stufe_LED_re_Cx1_Stufe_1), 2=Cx2_Stufe_2 (CM_KRH_Stufe_LED_re_Cx2_Stufe_2), 3=Cx3_Stufe_3 (CM_KRH_Stufe_LED_re_Cx3_Stufe_3)}, range raw 0..3, transfer-property=TRIGGERED-ON-CHANGE-WITHOUT-REPETITION  # Statusmeldung Kopfraumheizung rechts
          signal KRH_Stufe_LED_li_XIX_BCM_05_XIX_E3V_K2CANFD: start 18, 2 bit, little-endian, data-type-policy=OVERRIDE, i-signal-type=PRIMITIVE, init-value=0, base-type=BT_KRH_Stufe_LED_li, compu {0=Cx0_Aus (CM_KRH_Stufe_LED_li_Cx0_Aus), 1=Cx1_Stufe_1 (CM_KRH_Stufe_LED_li_Cx1_Stufe_1), 2=Cx2_Stufe_2 (CM_KRH_Stufe_LED_li_Cx2_Stufe_2), 3=Cx3_Stufe_3 (CM_KRH_Stufe_LED_li_Cx3_Stufe_3)}, range raw 0..3, transfer-property=TRIGGERED-ON-CHANGE-WITHOUT-REPETITION  # Statusmeldung Kopfraumheizung links
          signal SIL_Stufe_LED_re_XIX_BCM_05_XIX_E3V_K2CANFD: start 20, 3 bit, little-endian, data-type-policy=OVERRIDE, i-signal-type=PRIMITIVE, init-value=0, base-type=BT_SIL_Stufe_LED_re, compu {0=Cx0_Aus (CM_SIL_Stufe_LED_re_Cx0_Aus), 1=Cx1_Stufe_1 (CM_SIL_Stufe_LED_re_Cx1_Stufe_1), 2=Cx2_Stufe_2 (CM_SIL_Stufe_LED_re_Cx2_Stufe_2), 3=Cx3_Stufe_3 (CM_SIL_Stufe_LED_re_Cx3_Stufe_3), 4=Cx4_Stufe_4 (CM_SIL_Stufe_LED_re_Cx4_Stufe_4), 5=Cx5_Stufe_5 (CM_SIL_Stufe_LED_re_Cx5_Stufe_5), 6=Cx6_Stufe_6 (CM_SIL_Stufe_LED_re_Cx6_Stufe_6)}, range raw 0..6, transfer-property=TRIGGERED-ON-CHANGE-WITHOUT-REPETITION  # Statusmeldung Sitzlüftung rechts
          signal SIL_Stufe_LED_li_XIX_BCM_05_XIX_E3V_K2CANFD: start 23, 3 bit, little-endian, data-type-policy=OVERRIDE, i-signal-type=PRIMITIVE, init-value=0, base-type=BT_SIL_Stufe_LED_li, compu {0=Cx0_Aus (CM_SIL_Stufe_LED_li_Cx0_Aus), 1=Cx1_Stufe_1 (CM_SIL_Stufe_LED_li_Cx1_Stufe_1), 2=Cx2_Stufe_2 (CM_SIL_Stufe_LED_li_Cx2_Stufe_2), 3=Cx3_Stufe_3 (CM_SIL_Stufe_LED_li_Cx3_Stufe_3), 4=Cx4_Stufe_4 (CM_SIL_Stufe_LED_li_Cx4_Stufe_4), 5=Cx5_Stufe_5 (CM_SIL_Stufe_LED_li_Cx5_Stufe_5), 6=Cx6_Stufe_6 (CM_SIL_Stufe_LED_li_Cx6_Stufe_6)}, range raw 0..6, transfer-property=TRIGGERED-ON-CHANGE-WITHOUT-REPETITION  # Statusmeldung Sitzlüftung links
          signal FA_Hoehenwert_VL_01_XIX_BCM_05_XIX_E3V_K2CANFD: start 48, 8 bit, little-endian, data-type-policy=OVERRIDE, i-signal-type=PRIMITIVE, init-value=254, base-type=BT_FA_Hoehenwert_VL_01, invalid-value=Invalid_FA_Hoehenwert_VL_01_XIX_BCM_05_XIX_E3V_K2CANFD:255, compu {phys=raw*0.4 for raw 0..250, 254=Cxfe_nicht_initialisiert (CM_FA_Hoehenwert_VL_01_Cxfe_nicht_initialisiert) (nicht initialisiert), 255=Cxff_Fehler (CM_FA_Hoehenwert_VL_01_Cxff_Fehler); unit Unit_PerCent}, range phys 0..100 Unit_PerCent, raw 0..255, unit=Unit_PerCent, transfer-property=TRIGGERED-ON-CHANGE-WITHOUT-REPETITION  # Aktueller Höhenwert (Rohwerte) Vorne Links; ungefiltertes Signal Einheit, Offset und Faktor sind abhänig von "FA_Hoehenwert_kalibriert"
          signal FA_Hoehenwert_HL_01_XIX_BCM_05_XIX_E3V_K2CANFD: start 56, 8 bit, little-endian, data-type-policy=OVERRIDE, i-signal-type=PRIMITIVE, init-value=254, base-type=BT_FA_Hoehenwert_HL_01, invalid-value=Invalid_FA_Hoehenwert_HL_01_XIX_BCM_05_XIX_E3V_K2CANFD:255, compu {phys=raw*0.4 for raw 0..250, 254=Cxfe_nicht_initialisiert (CM_FA_Hoehenwert_HL_01_Cxfe_nicht_initialisiert) (nicht initialisiert), 255=Cxff_Fehler (CM_FA_Hoehenwert_HL_01_Cxff_Fehler); unit Unit_PerCent}, range phys 0..100 Unit_PerCent, raw 0..255, unit=Unit_PerCent, transfer-property=TRIGGERED-ON-CHANGE-WITHOUT-REPETITION  # Aktueller Höhenwert (Rohwerte) Hinten Links; ungefiltertes Signal Einheit, Offset und Faktor sind abhänig von "FA_Hoehenwert_kalibriert"
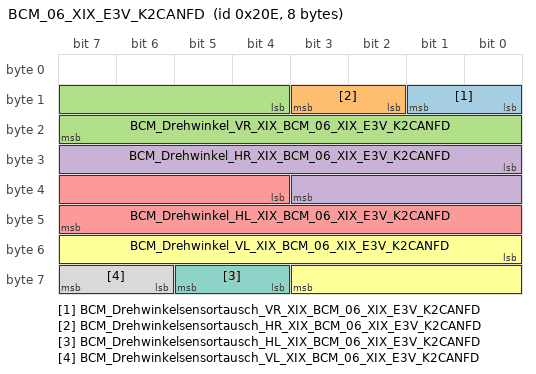
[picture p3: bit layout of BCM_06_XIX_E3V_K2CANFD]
      frame BCM_06_XIX_E3V_K2CANFD: id 0x20E, from SAM, frame-length=8, can-addressing-mode=STANDARD, can-frame-rx-behavior=CAN-FD, can-frame-tx-behavior=CAN-FD
        pdu BCM_06_XIX_E3V_K2CANFD: length=8, minimum-delay=0.02, transmission-mode-true-timing={cyclic-timing={time-offset=0.0, time-period=0.2}, event-controlled-timing={number-of-repetitions=0, repetition-period=0.0}}, unused-bit-pattern=0
          signal BCM_Drehwinkelsensortausch_VR_XIX_BCM_06_XIX_E3V_K2CANFD: start 8, 2 bit, little-endian, data-type-policy=OVERRIDE, i-signal-type=PRIMITIVE, init-value=0, base-type=BT_BCM_Drehwinkelsensortausch_VR, compu {0=Cx0_Init (CM_BCM_Drehwinkelsensortausch_VR_Cx0_Init), phys=raw for raw 1..3}, range phys 1..3, raw 0..3, transfer-property=PENDING  # Zähler der bei jedem erkannten Drehwinkelsensortausch inkrementiert wird. Systeme die den Drehwinkelwert empfangen können notwendigen Inbetriebnahmefunktionen starten
          signal BCM_Drehwinkelsensortausch_HR_XIX_BCM_06_XIX_E3V_K2CANFD: start 10, 2 bit, little-endian, data-type-policy=OVERRIDE, i-signal-type=PRIMITIVE, init-value=0, base-type=BT_BCM_Drehwinkelsensortausch_HR, compu {0=Cx0_Init (CM_BCM_Drehwinkelsensortausch_HR_Cx0_Init), phys=raw for raw 1..3}, range phys 1..3, raw 0..3, transfer-property=PENDING  # Zähler der bei jedem erkannten Drehwinkelsensortausch inkrementiert wird. Systeme die den Drehwinkelwert empfangen können notwendigen Inbetriebnahmefunktionen starten
          signal BCM_Drehwinkel_VR_XIX_BCM_06_XIX_E3V_K2CANFD: start 12, 12 bit, little-endian, data-type-policy=OVERRIDE, i-signal-type=PRIMITIVE, init-value=0, base-type=BT_BCM_Drehwinkel_VR, invalid-value=Invalid_BCM_Drehwinkel_VR_XIX_BCM_06_XIX_E3V_K2CANFD:4095, compu {phys=raw*0.088 for raw 0..4090, 4091=Cxffb_nicht_verwendet (CM_BCM_Drehwinkel_VR_Cxffb_nicht_verwendet), 4092=Cxffc_nicht_verwendet (CM_BCM_Drehwinkel_VR_Cxffc_nicht_verwendet), 4093=Cxffd_Sensor_nicht_verbaut (CM_BCM_Drehwinkel_VR_Cxffd_Sensor_nicht_verbaut), 4094=Cxffe_Init (CM_BCM_Drehwinkel_VR_Cxffe_Init), 4095=Cxfff_Fehler (CM_BCM_Drehwinkel_VR_Cxfff_Fehler)}, range phys 0..359.92, raw 0..4095, transfer-property=TRIGGERED-ON-CHANGE-WITHOUT-REPETITION  # Drehwinkelsensor zur Berechnung von Dämpferweg und für LWR
          signal BCM_Drehwinkel_HR_XIX_BCM_06_XIX_E3V_K2CANFD: start 24, 12 bit, little-endian, data-type-policy=OVERRIDE, i-signal-type=PRIMITIVE, init-value=0, base-type=BT_BCM_Drehwinkel_HR, invalid-value=Invalid_BCM_Drehwinkel_HR_XIX_BCM_06_XIX_E3V_K2CANFD:4095, compu {phys=raw*0.088 for raw 0..4090, 4091=Cxffb_nicht_verwendet (CM_BCM_Drehwinkel_HR_Cxffb_nicht_verwendet), 4092=Cxffc_nicht_verwendet (CM_BCM_Drehwinkel_HR_Cxffc_nicht_verwendet), 4093=Cxffd_Sensor_nicht_verbaut (CM_BCM_Drehwinkel_HR_Cxffd_Sensor_nicht_verbaut), 4094=Cxffe_Init (CM_BCM_Drehwinkel_HR_Cxffe_Init), 4095=Cxfff_Fehler (CM_BCM_Drehwinkel_HR_Cxfff_Fehler)}, range phys 0..359.92, raw 0..4095, transfer-property=TRIGGERED-ON-CHANGE-WITHOUT-REPETITION  # Drehwinkelsensor zur Berechnung von Dämpferweg und für LWR
          signal BCM_Drehwinkel_HL_XIX_BCM_06_XIX_E3V_K2CANFD: start 36, 12 bit, little-endian, data-type-policy=OVERRIDE, i-signal-type=PRIMITIVE, init-value=4094, base-type=BT_BCM_Drehwinkel_HL, invalid-value=Invalid_BCM_Drehwinkel_HL_XIX_BCM_06_XIX_E3V_K2CANFD:4095, compu {phys=raw*0.088 for raw 0..4090, 4091=Cxffb_nicht_verwendet (CM_BCM_Drehwinkel_HL_Cxffb_nicht_verwendet), 4092=Cxffc_nicht_verwendet (CM_BCM_Drehwinkel_HL_Cxffc_nicht_verwendet), 4093=Cxffd_Sensor_nicht_verbaut (CM_BCM_Drehwinkel_HL_Cxffd_Sensor_nicht_verbaut), 4094=Cxffe_Init (CM_BCM_Drehwinkel_HL_Cxffe_Init), 4095=Cxfff_Fehler (CM_BCM_Drehwinkel_HL_Cxfff_Fehler); unit Unit_DegreOfArc}, range phys 0..359.92 Unit_DegreOfArc, raw 0..4095, unit=Unit_DegreOfArc, transfer-property=TRIGGERED-ON-CHANGE-WITHOUT-REPETITION  # Drehwinkelsensor zur Berechnung von Dämpferweg und für LWR
          signal BCM_Drehwinkel_VL_XIX_BCM_06_XIX_E3V_K2CANFD: start 48, 12 bit, little-endian, data-type-policy=OVERRIDE, i-signal-type=PRIMITIVE, init-value=4094, base-type=BT_BCM_Drehwinkel_VL, invalid-value=Invalid_BCM_Drehwinkel_VL_XIX_BCM_06_XIX_E3V_K2CANFD:4095, compu {phys=raw*0.088 for raw 0..4090, 4091=Cxffb_nicht_verwendet (CM_BCM_Drehwinkel_VL_Cxffb_nicht_verwendet), 4092=Cxffc_nicht_verwendet (CM_BCM_Drehwinkel_VL_Cxffc_nicht_verwendet), 4093=Cxffd_Sensor_nicht_verbaut (CM_BCM_Drehwinkel_VL_Cxffd_Sensor_nicht_verbaut), 4094=Cxffe_Init (CM_BCM_Drehwinkel_VL_Cxffe_Init), 4095=Cxfff_Fehler (CM_BCM_Drehwinkel_VL_Cxfff_Fehler); unit Unit_DegreOfArc}, range phys 0..359.92 Unit_DegreOfArc, raw 0..4095, unit=Unit_DegreOfArc, transfer-property=TRIGGERED-ON-CHANGE-WITHOUT-REPETITION  # Drehwinkelsensor zur Berechnung von Dämpferweg und für LWR
          signal BCM_Drehwinkelsensortausch_HL_XIX_BCM_06_XIX_E3V_K2CANFD: start 60, 2 bit, little-endian, data-type-policy=OVERRIDE, i-signal-type=PRIMITIVE, init-value=0, base-type=BT_BCM_Drehwinkelsensortausch_HL, compu {0=Cx0_Init (CM_BCM_Drehwinkelsensortausch_HL_Cx0_Init), phys=raw for raw 1..3}, range phys 1..3, raw 0..3, transfer-property=PENDING  # Zähler der bei jedem erkannten Drehwinkelsensortausch inkrementiert wird. Systeme die den Drehwinkelwert empfangen können notwendigen Inbetriebnahmefunktionen starten
          signal BCM_Drehwinkelsensortausch_VL_XIX_BCM_06_XIX_E3V_K2CANFD: start 62, 2 bit, little-endian, data-type-policy=OVERRIDE, i-signal-type=PRIMITIVE, init-value=0, base-type=BT_BCM_Drehwinkelsensortausch_VL, compu {0=Cx0_Init (CM_BCM_Drehwinkelsensortausch_VL_Cx0_Init), phys=raw for raw 1..3}, range phys 1..3, raw 0..3, transfer-property=PENDING  # Zähler der bei jedem erkannten Drehwinkelsensortausch inkrementiert wird. Systeme die den Drehwinkelwert empfangen können notwendigen Inbetriebnahmefunktionen starten
      frame BCM_Taster_01_XIX_E3V_K2CANFD: id 0x3C1, from SAM, frame-length=8, can-addressing-mode=STANDARD, can-frame-rx-behavior=CAN-FD, can-frame-tx-behavior=CAN-FD
        pdu BCM_Taster_01_XIX_E3V_K2CANFD: length=8, minimum-delay=0.02, transmission-mode-true-timing={cyclic-timing={time-offset=0.0, time-period=0.2}, event-controlled-timing={number-of-repetitions=5, repetition-period=0.02}}, unused-bit-pattern=0
          signal APS_Taster_XIX_BCM_Taster_01_XIX_E3V_K2CANFD: start 12, 2 bit, little-endian, data-type-policy=OVERRIDE, i-signal-type=PRIMITIVE, init-value=2, base-type=BT_APS_Taster, invalid-value=Invalid_APS_Taster_XIX_BCM_Taster_01_XIX_E3V_K2CANFD:3, compu {0=Cx0_Taste_nicht_betaetigt (CM_APS_Taster_Cx0_Taste_nicht_betaetigt), 1=Cx1_Taste_entprellt_betaetigt (CM_APS_Taster_Cx1_Taste_entprellt_betaetigt), 2=Cx2_Init_oder_nicht_verbaut (CM_APS_Taster_Cx2_Init_oder_nicht_verbaut), 3=Cx3_Fehler (CM_APS_Taster_Cx3_Fehler)}, range raw 0..3, transfer-property=TRIGGERED-ON-CHANGE  # Das Signal beschreibt den Zustand der Taste, die im MLBevo vom BCM1 eingelesen wird.
      frame BCM_Taster_02_XIX_E3V_K2CANFD: id 0x598, from SAM, frame-length=8, can-addressing-mode=STANDARD, can-frame-rx-behavior=CAN-FD, can-frame-tx-behavior=CAN-FD
        pdu BCM_Taster_02_XIX_E3V_K2CANFD: length=8, minimum-delay=0.02, transmission-mode-true-timing={cyclic-timing={time-offset=0.0, time-period=1.0}, event-controlled-timing={number-of-repetitions=5, repetition-period=0.1}}, unused-bit-pattern=0
          signal LIM_bCall_Taster_XIX_BCM_Taster_02_XIX_E3V_K2CANFD: start 12, 1 bit, little-endian, data-type-policy=OVERRIDE, i-signal-type=PRIMITIVE, init-value=0, base-type=BT_LIM_bCall_Taster, compu {0=Cx0_nicht_betaetigt (CM_LIM_bCall_Taster_Cx0_nicht_betaetigt), 1=Cx1_betaetigt (CM_LIM_bCall_Taster_Cx1_betaetigt)}, range raw 0..1, transfer-property=TRIGGERED-ON-CHANGE  # Statusinformation des Service Call Tasters im Dachmodul
          signal LIM_iCall_Taster_XIX_BCM_Taster_02_XIX_E3V_K2CANFD: start 13, 1 bit, little-endian, data-type-policy=OVERRIDE, i-signal-type=PRIMITIVE, init-value=0, base-type=BT_LIM_iCall_Taster, compu {0=Cx0_nicht_betaetigt (CM_LIM_iCall_Taster_Cx0_nicht_betaetigt), 1=Cx1_betaetigt (CM_LIM_iCall_Taster_Cx1_betaetigt)}, range raw 0..1, transfer-property=TRIGGERED-ON-CHANGE  # Betätigungsstatus des Info Call Tasters im Dachmodul
          signal Tuerkontakt_Innenlicht_Taste_XIX_BCM_Taster_02_XIX_E3V_K2CANFD: start 14, 1 bit, little-endian, data-type-policy=OVERRIDE, i-signal-type=PRIMITIVE, init-value=0, base-type=BT_Tuerkontakt_Innenlicht_Taste, compu {0=Cx0_Taste_unbetaetigt (CM_Tuerkontakt_Innenlicht_Taste_Cx0_Taste_unbetaetigt), 1=Cx1_Taste_betaetigt (CM_Tuerkontakt_Innenlicht_Taste_Cx1_Taste_betaetigt)}, range raw 0..1, transfer-property=TRIGGERED-ON-CHANGE  # Taste zum Ändern des Türkontakt-Lichtfunktionszustandes.
          signal LINDa_Touch_Event_XIX_BCM_Taster_02_XIX_E3V_K2CANFD: start 16, 4 bit, little-endian, data-type-policy=OVERRIDE, i-signal-type=PRIMITIVE, init-value=0, base-type=BT_LINDa_Touch_Event, invalid-value=Invalid_LINDa_Touch_Event_XIX_BCM_Taster_02_XIX_E3V_K2CANFD:15, compu {0=Cx0_nicht_betaetigt (CM_LINDa_Touch_Event_Cx0_nicht_betaetigt), 1=Cx1_Tippen (CM_LINDa_Touch_Event_Cx1_Tippen), 2=Cx2_Wischen_Slide (CM_LINDa_Touch_Event_Cx2_Wischen_Slide), 3=Cx3_Geste (CM_LINDa_Touch_Event_Cx3_Geste), 4=Cx4_Doppeltippen (CM_LINDa_Touch_Event_Cx4_Doppeltippen), 5=Cx5_Longpress_1 (CM_LINDa_Touch_Event_Cx5_Longpress_1), 6=Cx6_Longpress_2 (CM_LINDa_Touch_Event_Cx6_Longpress_2), 7=Cx7_Longpress_3 (CM_LINDa_Touch_Event_Cx7_Longpress_3), 8=Cx8_Press (CM_LINDa_Touch_Event_Cx8_Press), 9=Cx9_Strongpress (CM_LINDa_Touch_Event_Cx9_Strongpress), 10=Cxa_reserviert (CM_LINDa_Touch_Event_Cxa_reserviert), 11=Cxb_reserviert (CM_LINDa_Touch_Event_Cxb_reserviert), 12=Cxc_reserviert (CM_LINDa_Touch_Event_Cxc_reserviert), 13=Cxd_reserviert (CM_LINDa_Touch_Event_Cxd_reserviert), 14=Cxe_Taktgeber_Inkrement (CM_LINDa_Touch_Event_Cxe_Taktgeber_Inkrement), 15=Cxf_Fehler (CM_LINDa_Touch_Event_Cxf_Fehler)}, range raw 0..15, transfer-property=TRIGGERED-ON-CHANGE-WITHOUT-REPETITION  # Touch_Events für Informationen einer Funktionsauslösung auf dem LINDa, welches dann für bspw. ein akustisches Signal zentral umgesetzt werden können.
          signal FAS_Profile_Taster_XIX_BCM_Taster_02_XIX_E3V_K2CANFD: start 20, 2 bit, little-endian, data-type-policy=OVERRIDE, i-signal-type=PRIMITIVE, init-value=2, base-type=BT_FAS_Profile_Taster, invalid-value=Invalid_FAS_Profile_Taster_XIX_BCM_Taster_02_XIX_E3V_K2CANFD:3, compu {0=Cx0_Taste_nicht_betaetigt (CM_FAS_Profile_Taster_Cx0_Taste_nicht_betaetigt), 1=Cx1_Taste_entprellt_betaetigt (CM_FAS_Profile_Taster_Cx1_Taste_entprellt_betaetigt), 2=Cx2_Init_oder_nicht_verbaut (CM_FAS_Profile_Taster_Cx2_Init_oder_nicht_verbaut), 3=Cx3_Fehler (CM_FAS_Profile_Taster_Cx3_Fehler)}, range raw 0..3, transfer-property=TRIGGERED-ON-CHANGE  # Das Signal beschreibt den Zustand der FAS-Profile-Tasters
          signal BCM_FS_Programmwippe_XIX_BCM_Taster_02_XIX_E3V_K2CANFD: start 37, 1 bit, little-endian, data-type-policy=OVERRIDE, i-signal-type=PRIMITIVE, init-value=0, base-type=BT_BCM_FS_Programmwippe, compu {0=Cx0_Taster_unbetaetigt (CM_BCM_FS_Programmwippe_Cx0_Taster_unbetaetigt), 1=Cx1_Taster_betaetigt (CM_BCM_FS_Programmwippe_Cx1_Taster_betaetigt)}, range raw 0..1, transfer-property=TRIGGERED-ON-CHANGE-WITHOUT-REPETITION  # Ansteuerungs-Signalisierung der Pneumatik-Funktionen
          signal BCM_BFS_Programmwippe_XIX_BCM_Taster_02_XIX_E3V_K2CANFD: start 38, 1 bit, little-endian, data-type-policy=OVERRIDE, i-signal-type=PRIMITIVE, init-value=0, base-type=BT_BCM_BFS_Programmwippe, compu {0=Cx0_Taster_unbetaetigt (CM_BCM_BFS_Programmwippe_Cx0_Taster_unbetaetigt), 1=Cx1_Taster_betaetigt (CM_BCM_BFS_Programmwippe_Cx1_Taster_betaetigt)}, range raw 0..1, transfer-property=TRIGGERED-ON-CHANGE-WITHOUT-REPETITION  # Ansteuerungs-Signalisierung der Pneumatik-Funktionen
          signal BCM_FS_Multif_Taster_XIX_BCM_Taster_02_XIX_E3V_K2CANFD: start 39, 1 bit, little-endian, data-type-policy=OVERRIDE, i-signal-type=PRIMITIVE, init-value=0, base-type=BT_BCM_FS_Multif_Taster, compu {0=Cx0_Taster_unbetaetigt (CM_BCM_FS_Multif_Taster_Cx0_Taster_unbetaetigt), 1=Cx1_Taster_betaetigt (CM_BCM_FS_Multif_Taster_Cx1_Taster_betaetigt)}, range raw 0..1, transfer-property=TRIGGERED-ON-CHANGE-WITHOUT-REPETITION  # Ansteuerungs-Signalisierung der Pneumatik-Funktionen
          signal BCM_BFS_Multif_Taster_XIX_BCM_Taster_02_XIX_E3V_K2CANFD: start 40, 1 bit, little-endian, data-type-policy=OVERRIDE, i-signal-type=PRIMITIVE, init-value=0, base-type=BT_BCM_BFS_Multif_Taster, compu {0=Cx0_Taster_unbetaetigt (CM_BCM_BFS_Multif_Taster_Cx0_Taster_unbetaetigt), 1=Cx1_Taster_betaetigt (CM_BCM_BFS_Multif_Taster_Cx1_Taster_betaetigt)}, range raw 0..1, transfer-property=TRIGGERED-ON-CHANGE-WITHOUT-REPETITION  # Ansteuerungs-Signalisierung der Pneumatik-Funktionen
          signal BCM_FS_Massage_Taster_XIX_BCM_Taster_02_XIX_E3V_K2CANFD: start 41, 1 bit, little-endian, data-type-policy=OVERRIDE, i-signal-type=PRIMITIVE, init-value=0, base-type=BT_BCM_FS_Massage_Taster, compu {0=Cx0_Taster_unbetaetigt (CM_BCM_FS_Massage_Taster_Cx0_Taster_unbetaetigt), 1=Cx1_Taster_betaetigt (CM_BCM_FS_Massage_Taster_Cx1_Taster_betaetigt)}, range raw 0..1, transfer-property=TRIGGERED-ON-CHANGE-WITHOUT-REPETITION  # Ansteuerungs-Signalisierung der Pneumatik-Funktionen
          signal BCM_BFS_Massage_Taster_XIX_BCM_Taster_02_XIX_E3V_K2CANFD: start 42, 1 bit, little-endian, data-type-policy=OVERRIDE, i-signal-type=PRIMITIVE, init-value=0, base-type=BT_BCM_BFS_Massage_Taster, compu {0=Cx0_Taster_unbetaetigt (CM_BCM_BFS_Massage_Taster_Cx0_Taster_unbetaetigt), 1=Cx1_Taster_betaetigt (CM_BCM_BFS_Massage_Taster_Cx1_Taster_betaetigt)}, range raw 0..1, transfer-property=TRIGGERED-ON-CHANGE-WITHOUT-REPETITION  # Ansteuerungs-Signalisierung der Pneumatik-Funktionen
          signal BCM_FS_Pneumatik_Verstellung_XIX_BCM_Taster_02_XIX_E3V_K2CANFD: start 43, 1 bit, little-endian, data-type-policy=OVERRIDE, i-signal-type=PRIMITIVE, init-value=0, base-type=BT_BCM_FS_Pneumatik_Verstellung, compu {0=Cx0_keine_Verstellung (CM_BCM_FS_Pneumatik_Verstellung_Cx0_keine_Verstellung), 1=Cx1_Pneumatikverstellung_aktiv (CM_BCM_FS_Pneumatik_Verstellung_Cx1_Pneumatikverstellung_aktiv)}, range raw 0..1, transfer-property=TRIGGERED-ON-CHANGE-WITHOUT-REPETITION  # Ansteuerungs-Signalisierung der Pneumatik-Funktionen
          signal BCM_BFS_Pneumatik_Verstellung_XIX_BCM_Taster_02_XIX_E3V_K2CANFD: start 44, 1 bit, little-endian, data-type-policy=OVERRIDE, i-signal-type=PRIMITIVE, init-value=0, base-type=BT_BCM_BFS_Pneumatik_Verstellung, compu {0=Cx0_keine_Verstellung (CM_BCM_BFS_Pneumatik_Verstellung_Cx0_keine_Verstellung), 1=Cx1_Pneumatikverstellung_aktiv (CM_BCM_BFS_Pneumatik_Verstellung_Cx1_Pneumatikverstellung_aktiv)}, range raw 0..1, transfer-property=TRIGGERED-ON-CHANGE-WITHOUT-REPETITION  # Ansteuerungs-Signalisierung der Pneumatik-Funktionen
          signal LIM_S_Rollo_vo_XIX_BCM_Taster_02_XIX_E3V_K2CANFD: start 50, 3 bit, little-endian, data-type-policy=OVERRIDE, i-signal-type=PRIMITIVE, init-value=0, base-type=BT_LIM_S_Rollo_vo, compu {0=Cx0_nicht_betaetigt (CM_LIM_S_Rollo_vo_Cx0_nicht_betaetigt), 1=Cx1_man_zu (CM_LIM_S_Rollo_vo_Cx1_man_zu), 2=Cx2_auto_zu (CM_LIM_S_Rollo_vo_Cx2_auto_zu), 3=Cx3_man_auf (CM_LIM_S_Rollo_vo_Cx3_man_auf), 4=Cx4_auto_auf (CM_LIM_S_Rollo_vo_Cx4_auto_auf), 5=Cx5_stop (CM_LIM_S_Rollo_vo_Cx5_stop), 6=Cx6_fehler_schalter_haengt (CM_LIM_S_Rollo_vo_Cx6_fehler_schalter_haengt), 7=Cx7_fehler_schalter_unplausibel (CM_LIM_S_Rollo_vo_Cx7_fehler_schalter_unplausibel)}, range raw 0..7, transfer-property=TRIGGERED-ON-CHANGE  # Schalterfeld LIM fuer Sonnenrollo Schiebedach vorne bzw. schaltbares Glasdach
          signal LIM_S_Rollo_hi_XIX_BCM_Taster_02_XIX_E3V_K2CANFD: start 53, 3 bit, little-endian, data-type-policy=OVERRIDE, i-signal-type=PRIMITIVE, init-value=0, base-type=BT_LIM_S_Rollo_hi, compu {0=Cx0_nicht_betaetigt (CM_LIM_S_Rollo_hi_Cx0_nicht_betaetigt), 1=Cx1_man_zu (CM_LIM_S_Rollo_hi_Cx1_man_zu), 2=Cx2_auto_zu (CM_LIM_S_Rollo_hi_Cx2_auto_zu), 3=Cx3_man_auf (CM_LIM_S_Rollo_hi_Cx3_man_auf), 4=Cx4_auto_auf (CM_LIM_S_Rollo_hi_Cx4_auto_auf), 5=Cx5_stop (CM_LIM_S_Rollo_hi_Cx5_stop), 6=Cx6_fehler_schalter_haengt (CM_LIM_S_Rollo_hi_Cx6_fehler_schalter_haengt), 7=Cx7_fehler_schalter_unplausibel (CM_LIM_S_Rollo_hi_Cx7_fehler_schalter_unplausibel)}, range raw 0..7, transfer-property=TRIGGERED-ON-CHANGE  # Schalterfeld LIM für Sonnenrolle Schiebedach hinten
          signal LIM_S_SAD_Vo_XIX_BCM_Taster_02_XIX_E3V_K2CANFD: start 56, 4 bit, little-endian, data-type-policy=OVERRIDE, i-signal-type=PRIMITIVE, init-value=0, base-type=BT_LIM_S_SAD_Vo, compu {0=Cx0_nicht_betaetigt (CM_LIM_S_SAD_Vo_Cx0_nicht_betaetigt), 1=Cx1_man_sl_zu (CM_LIM_S_SAD_Vo_Cx1_man_sl_zu), 2=Cx2_auto_sl_zu (CM_LIM_S_SAD_Vo_Cx2_auto_sl_zu), 3=Cx3_man_sl_auf (CM_LIM_S_SAD_Vo_Cx3_man_sl_auf), 4=Cx4_auto_sl_auf (CM_LIM_S_SAD_Vo_Cx4_auto_sl_auf), 5=Cx5_man_al_auf (CM_LIM_S_SAD_Vo_Cx5_man_al_auf), 6=Cx6_auto_al_auf (CM_LIM_S_SAD_Vo_Cx6_auto_al_auf), 7=Cx7_man_al_zu (CM_LIM_S_SAD_Vo_Cx7_man_al_zu), 8=Cx8_auto_al_zu (CM_LIM_S_SAD_Vo_Cx8_auto_al_zu), 9=Cx9_stop (CM_LIM_S_SAD_Vo_Cx9_stop), 10=Cxa_Toggle_Taster_AL_betaetigt (CM_LIM_S_SAD_Vo_Cxa_Toggle_Taster_AL_betaetigt), 14=Cxe_fehler_schalter_haengt (CM_LIM_S_SAD_Vo_Cxe_fehler_schalter_haengt), 15=Cxf_fehler_schalter_unplausibel (CM_LIM_S_SAD_Vo_Cxf_fehler_schalter_unplausibel)}, range raw 0..15, transfer-property=TRIGGERED-ON-CHANGE  # Schalterfeld LIM für SAD vorne
          signal LIM_S_SAD_hi_XIX_BCM_Taster_02_XIX_E3V_K2CANFD: start 60, 4 bit, little-endian, data-type-policy=OVERRIDE, i-signal-type=PRIMITIVE, init-value=0, base-type=BT_LIM_S_SAD_hi, compu {0=Cx0_nicht_betaetigt (CM_LIM_S_SAD_hi_Cx0_nicht_betaetigt), 1=Cx1_man_sl_zu (CM_LIM_S_SAD_hi_Cx1_man_sl_zu), 2=Cx2_auto_sl_zu (CM_LIM_S_SAD_hi_Cx2_auto_sl_zu), 3=Cx3_man_sl_auf (CM_LIM_S_SAD_hi_Cx3_man_sl_auf), 4=Cx4_auto_sl_auf (CM_LIM_S_SAD_hi_Cx4_auto_sl_auf), 5=Cx5_man_al_auf (CM_LIM_S_SAD_hi_Cx5_man_al_auf), 6=Cx6_auto_al_auf (CM_LIM_S_SAD_hi_Cx6_auto_al_auf), 7=Cx7_man_al_zu (CM_LIM_S_SAD_hi_Cx7_man_al_zu), 8=Cx8_auto_al_zu (CM_LIM_S_SAD_hi_Cx8_auto_al_zu), 14=Cxe_fehler_schalter_haengt (CM_LIM_S_SAD_hi_Cxe_fehler_schalter_haengt), 15=Cxf_fehler_schalter_unplausibel (CM_LIM_S_SAD_hi_Cxf_fehler_schalter_unplausibel)}, range raw 0..15, transfer-property=TRIGGERED-ON-CHANGE  # Schalterfeld LIM für SAD hinten
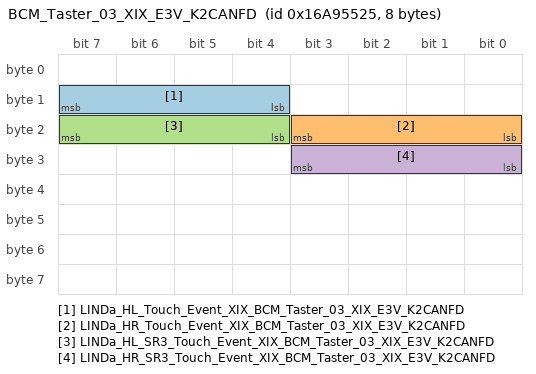
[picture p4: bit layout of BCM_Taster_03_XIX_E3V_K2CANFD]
      frame BCM_Taster_03_XIX_E3V_K2CANFD: id 0x16A95525, from SAM, frame-length=8, can-addressing-mode=EXTENDED, can-frame-rx-behavior=CAN-FD, can-frame-tx-behavior=CAN-FD
        pdu BCM_Taster_03_XIX_E3V_K2CANFD: length=8, minimum-delay=0.02, transmission-mode-true-timing={cyclic-timing={time-offset=0.0, time-period=1.0}, event-controlled-timing={number-of-repetitions=0, repetition-period=0.0}}, unused-bit-pattern=0
          signal LINDa_HL_Touch_Event_XIX_BCM_Taster_03_XIX_E3V_K2CANFD: start 12, 4 bit, little-endian, data-type-policy=OVERRIDE, i-signal-type=PRIMITIVE, init-value=0, base-type=BT_LINDa_HL_Touch_Event, invalid-value=Invalid_LINDa_HL_Touch_Event_XIX_BCM_Taster_03_XIX_E3V_K2CANFD:15, compu {0=Cx0_nicht_betaetigt (CM_LINDa_HL_Touch_Event_Cx0_nicht_betaetigt), 1=Cx1_Tippen (CM_LINDa_HL_Touch_Event_Cx1_Tippen), 2=Cx2_Wischen_Slide (CM_LINDa_HL_Touch_Event_Cx2_Wischen_Slide), 3=Cx3_Geste (CM_LINDa_HL_Touch_Event_Cx3_Geste), 4=Cx4_Doppeltippen (CM_LINDa_HL_Touch_Event_Cx4_Doppeltippen), 5=Cx5_Longpress_1 (CM_LINDa_HL_Touch_Event_Cx5_Longpress_1), 6=Cx6_Longpress_2 (CM_LINDa_HL_Touch_Event_Cx6_Longpress_2), 7=Cx7_Longpress_3 (CM_LINDa_HL_Touch_Event_Cx7_Longpress_3), 8=Cx8_Press (CM_LINDa_HL_Touch_Event_Cx8_Press), 9=Cx9_Strongpress (CM_LINDa_HL_Touch_Event_Cx9_Strongpress), 10=Cxa_reserviert (CM_LINDa_HL_Touch_Event_Cxa_reserviert), 11=Cxb_reserviert (CM_LINDa_HL_Touch_Event_Cxb_reserviert), 12=Cxc_reserviert (CM_LINDa_HL_Touch_Event_Cxc_reserviert), 13=Cxd_reserviert (CM_LINDa_HL_Touch_Event_Cxd_reserviert), 14=Cxe_Taktgeber_Inkrement (CM_LINDa_HL_Touch_Event_Cxe_Taktgeber_Inkrement), 15=Cxf_Fehler (CM_LINDa_HL_Touch_Event_Cxf_Fehler)}, range raw 0..15, transfer-property=TRIGGERED-ON-CHANGE-WITHOUT-REPETITION  # Touch_Events für Informationen einer Funktionsauslösung auf dem LINDa, welches dann für bspw. ein akustisches Signal zentral umgesetzt werden können.
          signal LINDa_HR_Touch_Event_XIX_BCM_Taster_03_XIX_E3V_K2CANFD: start 16, 4 bit, little-endian, data-type-policy=OVERRIDE, i-signal-type=PRIMITIVE, init-value=0, base-type=BT_LINDa_HR_Touch_Event, invalid-value=Invalid_LINDa_HR_Touch_Event_XIX_BCM_Taster_03_XIX_E3V_K2CANFD:15, compu {0=Cx0_nicht_betaetigt (CM_LINDa_HR_Touch_Event_Cx0_nicht_betaetigt), 1=Cx1_Tippen (CM_LINDa_HR_Touch_Event_Cx1_Tippen), 2=Cx2_Wischen_Slide (CM_LINDa_HR_Touch_Event_Cx2_Wischen_Slide), 3=Cx3_Geste (CM_LINDa_HR_Touch_Event_Cx3_Geste), 4=Cx4_Doppeltippen (CM_LINDa_HR_Touch_Event_Cx4_Doppeltippen), 5=Cx5_Longpress_1 (CM_LINDa_HR_Touch_Event_Cx5_Longpress_1), 6=Cx6_Longpress_2 (CM_LINDa_HR_Touch_Event_Cx6_Longpress_2), 7=Cx7_Longpress_3 (CM_LINDa_HR_Touch_Event_Cx7_Longpress_3), 8=Cx8_Press (CM_LINDa_HR_Touch_Event_Cx8_Press), 9=Cx9_Strongpress (CM_LINDa_HR_Touch_Event_Cx9_Strongpress), 10=Cxa_reserviert (CM_LINDa_HR_Touch_Event_Cxa_reserviert), 11=Cxb_reserviert (CM_LINDa_HR_Touch_Event_Cxb_reserviert), 12=Cxc_reserviert (CM_LINDa_HR_Touch_Event_Cxc_reserviert), 13=Cxd_reserviert (CM_LINDa_HR_Touch_Event_Cxd_reserviert), 14=Cxe_Taktgeber_Inkrement (CM_LINDa_HR_Touch_Event_Cxe_Taktgeber_Inkrement), 15=Cxf_Fehler (CM_LINDa_HR_Touch_Event_Cxf_Fehler)}, range raw 0..15, transfer-property=TRIGGERED-ON-CHANGE-WITHOUT-REPETITION  # Touch_Events für Informationen einer Funktionsauslösung auf dem LINDa, welches dann für bspw. ein akustisches Signal zentral umgesetzt werden können.
          signal LINDa_HL_SR3_Touch_Event_XIX_BCM_Taster_03_XIX_E3V_K2CANFD: start 20, 4 bit, little-endian, data-type-policy=OVERRIDE, i-signal-type=PRIMITIVE, init-value=0, base-type=BT_LINDa_HL_SR3_Touch_Event, invalid-value=Invalid_LINDa_HL_SR3_Touch_Event_XIX_BCM_Taster_03_XIX_E3V_K2CANFD:15, compu {0=Cx0_nicht_betaetigt (CM_LINDa_HL_SR3_Touch_Event_Cx0_nicht_betaetigt), 1=Cx1_Tippen (CM_LINDa_HL_SR3_Touch_Event_Cx1_Tippen), 2=Cx2_Wischen_Slide (CM_LINDa_HL_SR3_Touch_Event_Cx2_Wischen_Slide), 3=Cx3_Geste (CM_LINDa_HL_SR3_Touch_Event_Cx3_Geste), 4=Cx4_Doppeltippen (CM_LINDa_HL_SR3_Touch_Event_Cx4_Doppeltippen), 5=Cx5_Longpress_1 (CM_LINDa_HL_SR3_Touch_Event_Cx5_Longpress_1), 6=Cx6_Longpress_2 (CM_LINDa_HL_SR3_Touch_Event_Cx6_Longpress_2), 7=Cx7_Longpress_3 (CM_LINDa_HL_SR3_Touch_Event_Cx7_Longpress_3), 8=Cx8_Press (CM_LINDa_HL_SR3_Touch_Event_Cx8_Press), 9=Cx9_Strongpress (CM_LINDa_HL_SR3_Touch_Event_Cx9_Strongpress), 10=Cxa_reserviert (CM_LINDa_HL_SR3_Touch_Event_Cxa_reserviert), 11=Cxb_reserviert (CM_LINDa_HL_SR3_Touch_Event_Cxb_reserviert), 12=Cxc_reserviert (CM_LINDa_HL_SR3_Touch_Event_Cxc_reserviert), 13=Cxd_reserviert (CM_LINDa_HL_SR3_Touch_Event_Cxd_reserviert), 14=Cxe_Taktgeber_Inkrement (CM_LINDa_HL_SR3_Touch_Event_Cxe_Taktgeber_Inkrement), 15=Cxf_Fehler (CM_LINDa_HL_SR3_Touch_Event_Cxf_Fehler)}, range raw 0..15, transfer-property=TRIGGERED-ON-CHANGE-WITHOUT-REPETITION  # Touch_Events für Informationen einer Funktionsauslösung auf dem LINDa (hinten links SR3) , welches dann für bspw. ein akustisches Signal zentral umgesetzt werden können.
          signal LINDa_HR_SR3_Touch_Event_XIX_BCM_Taster_03_XIX_E3V_K2CANFD: start 24, 4 bit, little-endian, data-type-policy=OVERRIDE, i-signal-type=PRIMITIVE, init-value=0, base-type=BT_LINDa_HR_SR3_Touch_Event, invalid-value=Invalid_LINDa_HR_SR3_Touch_Event_XIX_BCM_Taster_03_XIX_E3V_K2CANFD:15, compu {0=Cx0_nicht_betaetigt (CM_LINDa_HR_SR3_Touch_Event_Cx0_nicht_betaetigt), 1=Cx1_Tippen (CM_LINDa_HR_SR3_Touch_Event_Cx1_Tippen), 2=Cx2_Wischen_Slide (CM_LINDa_HR_SR3_Touch_Event_Cx2_Wischen_Slide), 3=Cx3_Geste (CM_LINDa_HR_SR3_Touch_Event_Cx3_Geste), 4=Cx4_Doppeltippen (CM_LINDa_HR_SR3_Touch_Event_Cx4_Doppeltippen), 5=Cx5_Longpress_1 (CM_LINDa_HR_SR3_Touch_Event_Cx5_Longpress_1), 6=Cx6_Longpress_2 (CM_LINDa_HR_SR3_Touch_Event_Cx6_Longpress_2), 7=Cx7_Longpress_3 (CM_LINDa_HR_SR3_Touch_Event_Cx7_Longpress_3), 8=Cx8_Press (CM_LINDa_HR_SR3_Touch_Event_Cx8_Press), 9=Cx9_Strongpress (CM_LINDa_HR_SR3_Touch_Event_Cx9_Strongpress), 10=Cxa_reserviert (CM_LINDa_HR_SR3_Touch_Event_Cxa_reserviert), 11=Cxb_reserviert (CM_LINDa_HR_SR3_Touch_Event_Cxb_reserviert), 12=Cxc_reserviert (CM_LINDa_HR_SR3_Touch_Event_Cxc_reserviert), 13=Cxd_reserviert (CM_LINDa_HR_SR3_Touch_Event_Cxd_reserviert), 14=Cxe_Taktgeber_Inkrement (CM_LINDa_HR_SR3_Touch_Event_Cxe_Taktgeber_Inkrement), 15=Cxf_Fehler (CM_LINDa_HR_SR3_Touch_Event_Cxf_Fehler)}, range raw 0..15, transfer-property=TRIGGERED-ON-CHANGE-WITHOUT-REPETITION  # Touch_Events für Informationen einer Funktionsauslösung auf dem LINDa (hinten rechts SR3), welches dann für bspw. ein akustisches Signal zentral umgesetzt werden können.
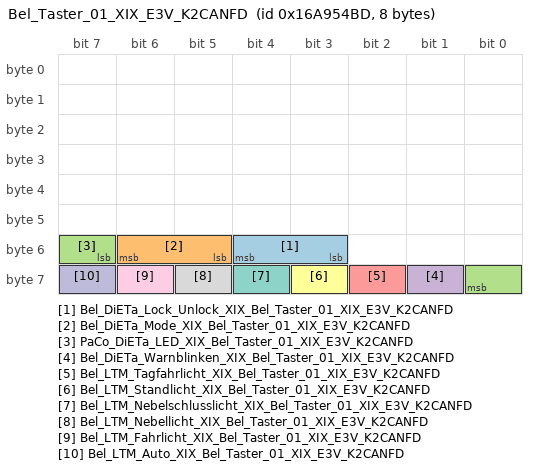
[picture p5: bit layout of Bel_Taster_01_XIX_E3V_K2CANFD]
      frame Bel_Taster_01_XIX_E3V_K2CANFD: id 0x16A954BD, to SAM, frame-length=8, can-addressing-mode=EXTENDED, can-frame-rx-behavior=CAN-FD, can-frame-tx-behavior=CAN-FD
        pdu Bel_Taster_01_XIX_E3V_K2CANFD: length=8, minimum-delay=0.05, transmission-mode-true-timing={cyclic-timing={time-offset=0.0, time-period=1.0}, event-controlled-timing={number-of-repetitions=0, repetition-period=0.0}}, unused-bit-pattern=0
          signal Bel_DiETa_Lock_Unlock_XIX_Bel_Taster_01_XIX_E3V_K2CANFD: start 51, 2 bit, little-endian, data-type-policy=OVERRIDE, i-signal-type=PRIMITIVE, init-value=0, base-type=BT_Bel_DiETa_Lock_Unlock, invalid-value=Invalid_Bel_DiETa_Lock_Unlock_XIX_Bel_Taster_01_XIX_E3V_K2CANFD:3, compu {0=Cx0_LED_Aus (CM_Bel_DiETa_Lock_Unlock_Cx0_LED_Aus), 1=Cx1_LED_Ein (CM_Bel_DiETa_Lock_Unlock_Cx1_LED_Ein), 2=Cx2_LED_blinken (CM_Bel_DiETa_Lock_Unlock_Cx2_LED_blinken), 3=Cx3_Fehler (CM_Bel_DiETa_Lock_Unlock_Cx3_Fehler)}, range raw 0..3, transfer-property=TRIGGERED-ON-CHANGE-WITHOUT-REPETITION, to SAM  # Statusanzeige Lock Unlock Taste in den Direkteinstiegstasten
          signal Bel_DiETa_Mode_XIX_Bel_Taster_01_XIX_E3V_K2CANFD: start 53, 2 bit, little-endian, data-type-policy=OVERRIDE, i-signal-type=PRIMITIVE, init-value=0, base-type=BT_Bel_DiETa_Mode, invalid-value=Invalid_Bel_DiETa_Mode_XIX_Bel_Taster_01_XIX_E3V_K2CANFD:3, compu {0=Cx0_LED_Aus (CM_Bel_DiETa_Mode_Cx0_LED_Aus), 1=Cx1_LED_Ein (CM_Bel_DiETa_Mode_Cx1_LED_Ein), 2=Cx2_LED_blinken (CM_Bel_DiETa_Mode_Cx2_LED_blinken), 3=Cx3_Fehler (CM_Bel_DiETa_Mode_Cx3_Fehler)}, range raw 0..3, transfer-property=TRIGGERED-ON-CHANGE-WITHOUT-REPETITION, to SAM(timeout 5 s)  # Statusanzeige FPA-Mode in den Direkteinstiegstasten
          signal PaCo_DiETa_LED_XIX_Bel_Taster_01_XIX_E3V_K2CANFD: start 55, 2 bit, little-endian, data-type-policy=OVERRIDE, i-signal-type=PRIMITIVE, init-value=0, base-type=BT_PaCo_DiETa_LED, compu {0=Cx0_LED_Inactive (CM_PaCo_DiETa_LED_Cx0_LED_Inactive), 1=Cx1_LED_Active (CM_PaCo_DiETa_LED_Cx1_LED_Active), 2=Cx2_LED_Flashing (CM_PaCo_DiETa_LED_Cx2_LED_Flashing), 3=Cx3_Error (CM_PaCo_DiETa_LED_Cx3_Error)}, range raw 0..3, transfer-property=TRIGGERED-ON-CHANGE-WITHOUT-REPETITION, to SAM  # Ansteuerung der Funktionsbeleuchtung im Direkteinstiegstaster ("DiETa") durch den Parking Coordinator ("PaCo"). 0 LED_Inactive: Die Funktionsbeleuchtung im DiETa_Parken muss leuchten 1 LED_Active: Die Funktionsbeleuchtung im DiETa_Parken darf nicht leuchten 2 LED_Flashing: Die Funktionsbeleuchtung im DiETa_Parken muss blinken 3 Error
          signal Bel_DiETa_Warnblinken_XIX_Bel_Taster_01_XIX_E3V_K2CANFD: start 57, 1 bit, little-endian, data-type-policy=OVERRIDE, i-signal-type=PRIMITIVE, init-value=0, base-type=BT_Bel_DiETa_Warnblinken, compu {0=Cx0_Aus (CM_Bel_DiETa_Warnblinken_Cx0_Aus), 1=Cx1_Ein (CM_Bel_DiETa_Warnblinken_Cx1_Ein)}, range raw 0..1, transfer-property=TRIGGERED-ON-CHANGE-WITHOUT-REPETITION, to SAM(timeout 5 s)  # Realisierung Warnblinken in den Direkteinstiegstasten
          signal Bel_LTM_Tagfahrlicht_XIX_Bel_Taster_01_XIX_E3V_K2CANFD: start 58, 1 bit, little-endian, data-type-policy=OVERRIDE, i-signal-type=PRIMITIVE, init-value=0, base-type=BT_Bel_LTM_Tagfahrlicht, compu {0=Cx0_Aus (CM_Bel_LTM_Tagfahrlicht_Cx0_Aus), 1=Cx1_Ein (CM_Bel_LTM_Tagfahrlicht_Cx1_Ein)}, range raw 0..1, transfer-property=TRIGGERED-ON-CHANGE-WITHOUT-REPETITION, to SAM  # 0=LED aus; 1=LED ein
          signal Bel_LTM_Standlicht_XIX_Bel_Taster_01_XIX_E3V_K2CANFD: start 59, 1 bit, little-endian, data-type-policy=OVERRIDE, i-signal-type=PRIMITIVE, init-value=0, base-type=BT_Bel_LTM_Standlicht, compu {0=Cx0_Aus (CM_Bel_LTM_Standlicht_Cx0_Aus), 1=Cx1_Ein (CM_Bel_LTM_Standlicht_Cx1_Ein)}, range raw 0..1, transfer-property=TRIGGERED-ON-CHANGE-WITHOUT-REPETITION, to SAM  # 0=LED aus; 1=LED ein
          signal Bel_LTM_Nebelschlusslicht_XIX_Bel_Taster_01_XIX_E3V_K2CANFD: start 60, 1 bit, little-endian, data-type-policy=OVERRIDE, i-signal-type=PRIMITIVE, init-value=0, base-type=BT_Bel_LTM_Nebelschlusslicht, compu {0=Cx0_Aus (CM_Bel_LTM_Nebelschlusslicht_Cx0_Aus), 1=Cx1_Ein (CM_Bel_LTM_Nebelschlusslicht_Cx1_Ein)}, range raw 0..1, transfer-property=TRIGGERED-ON-CHANGE-WITHOUT-REPETITION, to SAM  # 0=LED aus; 1=LED ein
          signal Bel_LTM_Nebellicht_XIX_Bel_Taster_01_XIX_E3V_K2CANFD: start 61, 1 bit, little-endian, data-type-policy=OVERRIDE, i-signal-type=PRIMITIVE, init-value=0, base-type=BT_Bel_LTM_Nebellicht, compu {0=Cx0_Aus (CM_Bel_LTM_Nebellicht_Cx0_Aus), 1=Cx1_Ein (CM_Bel_LTM_Nebellicht_Cx1_Ein)}, range raw 0..1, transfer-property=TRIGGERED-ON-CHANGE-WITHOUT-REPETITION, to SAM  # 0=LED aus; 1=LED ein
          signal Bel_LTM_Fahrlicht_XIX_Bel_Taster_01_XIX_E3V_K2CANFD: start 62, 1 bit, little-endian, data-type-policy=OVERRIDE, i-signal-type=PRIMITIVE, init-value=0, base-type=BT_Bel_LTM_Fahrlicht, compu {0=Cx0_Aus (CM_Bel_LTM_Fahrlicht_Cx0_Aus), 1=Cx1_Ein (CM_Bel_LTM_Fahrlicht_Cx1_Ein)}, range raw 0..1, transfer-property=TRIGGERED-ON-CHANGE-WITHOUT-REPETITION, to SAM  # 0=LED aus; 1=LED ein
          signal Bel_LTM_Auto_XIX_Bel_Taster_01_XIX_E3V_K2CANFD: start 63, 1 bit, little-endian, data-type-policy=OVERRIDE, i-signal-type=PRIMITIVE, init-value=0, base-type=BT_Bel_LTM_Auto, compu {0=Cx0_Aus (CM_Bel_LTM_Auto_Cx0_Aus), 1=Cx1_Ein (CM_Bel_LTM_Auto_Cx1_Ein)}, range raw 0..1, transfer-property=TRIGGERED-ON-CHANGE-WITHOUT-REPETITION, to SAM  # 0=LED aus; 1=LED ein
      frame BEM_02_XIX_E3V_K2CANFD: id 0x663, to SAM, frame-length=8, can-addressing-mode=STANDARD, can-frame-rx-behavior=CAN-FD, can-frame-tx-behavior=CAN-FD
        pdu BEM_02_XIX_E3V_K2CANFD: length=8, transmission-mode-true-timing=cyclic-timing={time-offset=0.0, time-period=0.1}, unused-bit-pattern=0  # DLC=8 ab D4 gültig
          signal NVEM_Abschaltstufe_XIX_BEM_02_XIX_E3V_K2CANFD: start 0, 2 bit, little-endian, data-type-policy=OVERRIDE, i-signal-type=PRIMITIVE, base-type=BT_NVEM_Abschaltstufe, compu {0=Cx0_Stufe_0_keine_Einschraenkung (CM_NVEM_Abschaltstufe_Cx0_Stufe_0_keine_Einschraenkung), 1=Cx1_Stufe_1 (CM_NVEM_Abschaltstufe_Cx1_Stufe_1), 2=Cx2_Stufe_2 (CM_NVEM_Abschaltstufe_Cx2_Stufe_2), 3=Cx3_Stufe_3 (CM_NVEM_Abschaltstufe_Cx3_Stufe_3)}, range raw 0..3, transfer-property=PENDING, to SAM(timeout 1 s)  # Abschaltstufe aus dem Ruheenergiemanagement Maßnahmen des Empfängers werden im QLAH Ruhestrommanagement definiert
          signal BEM_STH_Zielzeit_XIX_BEM_02_XIX_E3V_K2CANFD: start 3, 4 bit, little-endian, data-type-policy=OVERRIDE, i-signal-type=PRIMITIVE, init-value=14, base-type=BT_BEM_STH_Zielzeit, invalid-value=Invalid_BEM_STH_Zielzeit_XIX_BEM_02_XIX_E3V_K2CANFD:15, compu {phys=raw*5 for raw 0..12, 14=Cxe_Init (CM_BEM_STH_Zielzeit_Cxe_Init), 15=Cxf_Fehler (CM_BEM_STH_Zielzeit_Cxf_Fehler); unit Unit_Minut}, range phys 0..60 Unit_Minut, raw 0..15, unit=Unit_Minut, transfer-property=PENDING  # Maximal mögliche Zeit für den Standheizungsbetrieb, um die Startfähigkeit nicht zu gefährden
          signal BEM_MMI_Vorwarnung_XIX_BEM_02_XIX_E3V_K2CANFD: start 7, 1 bit, little-endian, data-type-policy=OVERRIDE, i-signal-type=PRIMITIVE, init-value=0, base-type=BT_BEM_MMI_Vorwarnung, compu {0=Cx0_keine_Anzeige (CM_BEM_MMI_Vorwarnung_Cx0_keine_Anzeige) (keine Anzeige), 1=Cx1_Anzeige_MMI_Vorwarnung (CM_BEM_MMI_Vorwarnung_Cx1_Anzeige_MMI_Vorwarnung) (Anzeige MMI-Vorwarnung)}, range raw 0..1, transfer-property=PENDING  # Anzeige Vorwarnung MMI-Abschaltung (Initialisierungswert aus EEprom)
          signal BEM_HL_Kontingentierung_XIX_BEM_02_XIX_E3V_K2CANFD: start 8, 6 bit, little-endian, data-type-policy=OVERRIDE, i-signal-type=PRIMITIVE, init-value=0, base-type=BT_BEM_HL_Kontingentierung, compu {phys=raw*50-1000 for raw 0..40; unit Unit_Watt}, range phys -1000..1000 Unit_Watt, raw 0..40, unit=Unit_Watt, transfer-property=PENDING  # Leistungskontingente für Heizsysteme
          signal NVEM_Freigabe_ZusBatt_Laden_XIX_BEM_02_XIX_E3V_K2CANFD: start 14, 1 bit, little-endian, data-type-policy=OVERRIDE, i-signal-type=PRIMITIVE, init-value=0, base-type=BT_NVEM_Freigabe_ZusBatt_Laden, compu {0=Cx0_keine_Freigabe_Laderelais (CM_NVEM_Freigabe_ZusBatt_Laden_Cx0_keine_Freigabe_Laderelais), 1=Cx1_Freigabe_Laderelais_schliessen (CM_NVEM_Freigabe_ZusBatt_Laden_Cx1_Freigabe_Laderelais_schliessen)}, range raw 0..1, transfer-property=PENDING  # NVEM gibt die Freigabe zum Schließen des Laderelais im Ruhebetrieb (z.B. bei Verwendung eines Ladegerätes)
          signal NVEM_Anf_SD_schalten_XIX_BEM_02_XIX_E3V_K2CANFD: start 15, 1 bit, little-endian, data-type-policy=OVERRIDE, i-signal-type=PRIMITIVE, init-value=0, base-type=BT_NVEM_Anf_SD_schalten, compu {0=Cx0_Anf_SD_Nachlauf_nicht_aktiv (CM_NVEM_Anf_SD_schalten_Cx0_Anf_SD_Nachlauf_nicht_aktiv), 1=Cx1_Anf_SD_Nachlauf_aktiv (CM_NVEM_Anf_SD_schalten_Cx1_Anf_SD_Nachlauf_aktiv)}, range raw 0..1, transfer-property=PENDING  # Anforderung Nachlauf für den Steckdosenbetrieb Initialisierungswert aus EEprom
          signal BEM_Generatordiagnose_XIX_BEM_02_XIX_E3V_K2CANFD: start 16, 2 bit, little-endian, data-type-policy=OVERRIDE, i-signal-type=PRIMITIVE, init-value=0, base-type=BT_BEM_Generatordiagnose, compu {0=Cx0_keine_Anzeige (CM_BEM_Generatordiagnose_Cx0_keine_Anzeige) (keine Anzeige), 1=Cx1_Ladekontrollanzeige_ein_Vorhalt (CM_BEM_Generatordiagnose_Cx1_Ladekontrollanzeige_ein_Vorhalt) (Ladekontrollanzeige ein (Vorhalt)), 2=Cx2_rotes_Batteriesymbol_und_Text_Generator_defekt (CM_BEM_Generatordiagnose_Cx2_rotes_Batteriesymbol_und_Text_Generator_defekt) (rotes Batteriesymbol und Text (Generator defekt)), 3=Cx3_Hybrid_DCDC_Wandler_defekt (CM_BEM_Generatordiagnose_Cx3_Hybrid_DCDC_Wandler_defekt)}, range raw 0..3, transfer-property=PENDING  # Ansteuerung Generatorwarnleuchte im Kombi
          signal BEM_Red_Innengeblaese_XIX_BEM_02_XIX_E3V_K2CANFD: start 18, 2 bit, little-endian, data-type-policy=OVERRIDE, i-signal-type=PRIMITIVE, init-value=0, base-type=BT_BEM_Red_Innengeblaese, compu {0=Cx0_keine_Reduzierung (CM_BEM_Red_Innengeblaese_Cx0_keine_Reduzierung) (keine Reduzierung), 1=Cx1_Reduzierung_Stufe_1 (CM_BEM_Red_Innengeblaese_Cx1_Reduzierung_Stufe_1) (Reduzierung Stufe 1), 2=Cx2_Reduzierung_Stufe_2 (CM_BEM_Red_Innengeblaese_Cx2_Reduzierung_Stufe_2) (Reduzierung Stufe 2), 3=Cx3_Reduzierung_Stufe_2_und_Abschaltung_Kompressor (CM_BEM_Red_Innengeblaese_Cx3_Reduzierung_Stufe_2_und_Abschaltung_Kompressor) (Reduzierung Stufe 2 und Abschaltung Kompressor)}, range raw 0..3, transfer-property=PENDING  # Reduzierung Innengebläse
          signal BEM_STH_Einschaltverbot_XIX_BEM_02_XIX_E3V_K2CANFD: start 20, 1 bit, little-endian, data-type-policy=OVERRIDE, i-signal-type=PRIMITIVE, init-value=0, base-type=BT_BEM_STH_Einschaltverbot, compu {0=Cx0_volle_Verfuegbarkeit_Standheizung_lueftung (CM_BEM_STH_Einschaltverbot_Cx0_volle_Verfuegbarkeit_Standheizung_lueftung) (volle Verfuegbarkeit Standheizung/-lueftung), 1=Cx1_Standheizung_lueftung_nicht_aktivierbar (CM_BEM_STH_Einschaltverbot_Cx1_Standheizung_lueftung_nicht_aktivierbar) (Standheizung/-lueftung nicht aktivierbar)}, range raw 0..1, transfer-property=PENDING  # Einschränkung Standheizung/-lüftung durch BEM: Setzt der BEM das Bit, dann darf die Standheizung nicht mehr einschalten (Die Standheizung muss aber nicht abschalten, sondern darf weiterbrennen) (Initialisierungswert aus EEprom)
          signal BEM_HL_Regelung_Status_XIX_BEM_02_XIX_E3V_K2CANFD: start 21, 3 bit, little-endian, data-type-policy=OVERRIDE, i-signal-type=PRIMITIVE, init-value=0, base-type=BT_BEM_HL_Regelung_Status, compu {0=Cx0_HL_Regelung_inaktiv_vor_und_waehrend_Motorstart (CM_BEM_HL_Regelung_Status_Cx0_HL_Regelung_inaktiv_vor_und_waehrend_Motorstart) (HL_Regelung_inaktiv_(vor_und_waehrend_Motorstart)), 1=Cx1_HL_Regelung_Stufe_1 (CM_BEM_HL_Regelung_Status_Cx1_HL_Regelung_Stufe_1), 2=Cx2_HL_Regelung_Stufe_2 (CM_BEM_HL_Regelung_Status_Cx2_HL_Regelung_Stufe_2), 3=Cx3_HL_Regelung_Stufe_3 (CM_BEM_HL_Regelung_Status_Cx3_HL_Regelung_Stufe_3), 4=Cx4_Verbrauchernotabschaltung_VNA (CM_BEM_HL_Regelung_Status_Cx4_Verbrauchernotabschaltung_VNA) (Verbrauchernotabschaltung_(VNA)), 5=Cx5_HL_Regelung_Stufe_5 (CM_BEM_HL_Regelung_Status_Cx5_HL_Regelung_Stufe_5), 7=Cx7_Default (CM_BEM_HL_Regelung_Status_Cx7_Default)}, range raw 0..7, transfer-property=PENDING  # Status Regelung Heizleistung
          signal BEM_Ladezustand_XIX_BEM_02_XIX_E3V_K2CANFD: start 24, 4 bit, little-endian, data-type-policy=OVERRIDE, i-signal-type=PRIMITIVE, init-value=14, base-type=BT_BEM_Ladezustand, invalid-value=Invalid_BEM_Ladezustand_XIX_BEM_02_XIX_E3V_K2CANFD:15, compu {phys=raw*10 for raw 0..10, 14=Cxe_Init (CM_BEM_Ladezustand_Cxe_Init), 15=Cxf_Fehler (CM_BEM_Ladezustand_Cxf_Fehler); unit Unit_PerCent}, range phys 0..100 Unit_PerCent, raw 0..15, unit=Unit_PerCent, transfer-property=PENDING  # Ladezustand der Niedervoltbatterie
          signal BEM_Batteriediagnose_XIX_BEM_02_XIX_E3V_K2CANFD: start 28, 3 bit, little-endian, data-type-policy=OVERRIDE, i-signal-type=PRIMITIVE, init-value=0, base-type=BT_BEM_Batteriediagnose, invalid-value=Invalid_BEM_Batteriediagnose_XIX_BEM_02_XIX_E3V_K2CANFD:7, compu {0=Cx0_keine_Anzeige (CM_BEM_Batteriediagnose_Cx0_keine_Anzeige), 1=Cx1_nicht_belegt (CM_BEM_Batteriediagnose_Cx1_nicht_belegt), 2=Cx2_Anzeige_aberkannte_Batterie (CM_BEM_Batteriediagnose_Cx2_Anzeige_aberkannte_Batterie), 3=Cx3_Anzeige_schwache_Batterie (CM_BEM_Batteriediagnose_Cx3_Anzeige_schwache_Batterie), 4=Cx4_Anzeige_Batterie_OK (CM_BEM_Batteriediagnose_Cx4_Anzeige_Batterie_OK), 5=Cx5_Anzeige_Batterie_Laden (CM_BEM_Batteriediagnose_Cx5_Anzeige_Batterie_Laden), 6=Cx6_Anzeige_Batterie_Pruefen (CM_BEM_Batteriediagnose_Cx6_Anzeige_Batterie_Pruefen), 7=Cx7_Fehler (CM_BEM_Batteriediagnose_Cx7_Fehler)}, range raw 0..7, transfer-property=PENDING  # Anzeige von Textwarnungen
          signal MIB_Stromsparmodus_XIX_BEM_02_XIX_E3V_K2CANFD: start 31, 1 bit, little-endian, data-type-policy=OVERRIDE, i-signal-type=PRIMITIVE, init-value=0, base-type=BT_MIB_Stromsparmodus, compu {0=Cx0_inaktiv (CM_MIB_Stromsparmodus_Cx0_inaktiv), 1=Cx1_aktiv (CM_MIB_Stromsparmodus_Cx1_aktiv)}, range raw 0..1, transfer-property=PENDING  # Signal beschreibt die Aktivierung für den Stromsparmodus beim MIB. Bei AUS (= 0) gibt es keine weitere Anforderung an die MIB-Komponenten. Bei EIN (= 1) werden alle MIB Komponenten in einen Stromsparmodus versetzt.
          signal BEM_DFM_XIX_BEM_02_XIX_E3V_K2CANFD: start 32, 5 bit, little-endian, data-type-policy=OVERRIDE, i-signal-type=PRIMITIVE, init-value=0, base-type=BT_BEM_DFM, compu {phys=raw*3.225+0.025 for raw 0..31}, range phys 0.025..100, raw 0..31, transfer-property=PENDING  # Generatorauslastungsgrad, vom Generator über LIN an das Gateway gesandt. Das Motorsteuergerät regelt auf dieses Signal die PTC, das Energiemanagement im BSG/BCM kalkuliert die Bordnetzauslastung
          signal BEM_REK_aktiv_XIX_BEM_02_XIX_E3V_K2CANFD: start 37, 1 bit, little-endian, data-type-policy=OVERRIDE, i-signal-type=PRIMITIVE, init-value=0, base-type=BT_BEM_REK_aktiv, compu {0=Cx0_keine_Rekuperationsfreigabe (CM_BEM_REK_aktiv_Cx0_keine_Rekuperationsfreigabe), 1=Cx1_Rekuperationsfreigabe (CM_BEM_REK_aktiv_Cx1_Rekuperationsfreigabe)}, range raw 0..1, transfer-property=PENDING  # Rekuperationsfreigabe vom Energiemanagement 0x0 = keine Rekuperationsfreigabe 0x1 = Rekuperationsfreigabe
          signal BEM_EMLIN_ungueltig_XIX_BEM_02_XIX_E3V_K2CANFD: start 38, 1 bit, little-endian, data-type-policy=OVERRIDE, i-signal-type=PRIMITIVE, init-value=0, base-type=BT_BEM_EMLIN_ungueltig, compu {0=Cx0_Signale_gueltig (CM_BEM_EMLIN_ungueltig_Cx0_Signale_gueltig), 1=Cx1_Signale_ungueltig (CM_BEM_EMLIN_ungueltig_Cx1_Signale_ungueltig)}, range raw 0..1, transfer-property=PENDING  # Energie-Lin - Signale sind ungültig vom Slave Batteriedatenmodul oder Generator 0 = Signale gültig 1 = Signale ungültig
          signal BEM_Batt_Ab_XIX_BEM_02_XIX_E3V_K2CANFD: start 39, 1 bit, little-endian, data-type-policy=OVERRIDE, i-signal-type=PRIMITIVE, init-value=0, base-type=BT_BEM_Batt_Ab, compu {0=Cx0_verbunden (CM_BEM_Batt_Ab_Cx0_verbunden), 1=Cx1_nicht_verbunden (CM_BEM_Batt_Ab_Cx1_nicht_verbunden)}, range raw 0..1, transfer-property=PENDING  # Batterieverbindungskontrolle: 0x0: Batterie am Bordnetz 0x1: Batterie ab erkannt
          signal BEM_UBDM_XIX_BEM_02_XIX_E3V_K2CANFD: start 40, 8 bit, little-endian, data-type-policy=OVERRIDE, i-signal-type=PRIMITIVE, init-value=0, base-type=BT_BEM_UBDM, invalid-value=Invalid_BEM_UBDM_XIX_BEM_02_XIX_E3V_K2CANFD:255, compu {0=Cx0_Init (CM_BEM_UBDM_Cx0_Init), phys=raw*0.05+5 for raw 1..254, 255=Cxff_Fehler (CM_BEM_UBDM_Cxff_Fehler); unit Unit_Volt}, range phys 5.05..17.7 Unit_Volt, raw 0..255, unit=Unit_Volt, transfer-property=PENDING  # Batteriespannung, gemessen vom Batteriedatenmodul
          signal BEM_UGenSoll_XIX_BEM_02_XIX_E3V_K2CANFD: start 48, 6 bit, little-endian, data-type-policy=OVERRIDE, i-signal-type=PRIMITIVE, init-value=0, base-type=BT_BEM_UGenSoll, compu {phys=raw*0.1+10.6 for raw 0..54; unit Unit_Volt}, range phys 10.6..16 Unit_Volt, raw 0..54, unit=Unit_Volt, transfer-property=PENDING  # Sollspannungsvorgabe an den Generator, beinhaltet temperaturoptimierte Batterieladung und Rekuperation
          signal BEM_Anf_KL15_schalten_XIX_BEM_02_XIX_E3V_K2CANFD: start 54, 2 bit, little-endian, data-type-policy=OVERRIDE, i-signal-type=PRIMITIVE, init-value=0, base-type=BT_BEM_Anf_KL15_schalten, compu {0=Cx0_Keine_Einschraenkung_Kl15 (CM_BEM_Anf_KL15_schalten_Cx0_Keine_Einschraenkung_Kl15), 1=Cx1_Empfehlung_auto_Abschaltung_Kl15 (CM_BEM_Anf_KL15_schalten_Cx1_Empfehlung_auto_Abschaltung_Kl15), 2=Cx2_Veto_auto_Abschaltung_Kl15 (CM_BEM_Anf_KL15_schalten_Cx2_Veto_auto_Abschaltung_Kl15), 3=Cx3_Veto_auto_Abschaltung_Fahrtbetrieb (CM_BEM_Anf_KL15_schalten_Cx3_Veto_auto_Abschaltung_Fahrtbetrieb)}, range raw 0..3, transfer-property=PENDING  # Abschaltempfehlung bzw. Verhinderung der automatischen Abschaltung Kl15 durch das BCM
          signal NVEM_Batterie_Service_XIX_BEM_02_XIX_E3V_K2CANFD: start 56, 2 bit, little-endian, data-type-policy=OVERRIDE, i-signal-type=PRIMITIVE, init-value=0, base-type=BT_NVEM_Batterie_Service, compu {0=Cx0_kein_Service (CM_NVEM_Batterie_Service_Cx0_kein_Service), 1=Cx1_Service_Information1 (CM_NVEM_Batterie_Service_Cx1_Service_Information1), 2=Cx2_Service_Information2 (CM_NVEM_Batterie_Service_Cx2_Service_Information2), 3=Cx3_Service_Information3 (CM_NVEM_Batterie_Service_Cx3_Service_Information3)}, range raw 0..3, transfer-property=PENDING  # Anforderung einer Batterie-Service - Anzeige / Anforderung an die Werkstatt über MOD
          signal NVEM_Freigabe_OnlineUpdate_XIX_BEM_02_XIX_E3V_K2CANFD: start 58, 1 bit, little-endian, data-type-policy=OVERRIDE, i-signal-type=PRIMITIVE, init-value=0, base-type=BT_NVEM_Freigabe_OnlineUpdate, compu {0=Cx0_keine_Freigabe (CM_NVEM_Freigabe_OnlineUpdate_Cx0_keine_Freigabe), 1=Cx1_Freigabe (CM_NVEM_Freigabe_OnlineUpdate_Cx1_Freigabe)}, range raw 0..1, transfer-property=PENDING  # Freigabe für Online-Update durch Energiemanagement
          signal NVEM_Freigabe_ORU4_XIX_BEM_02_XIX_E3V_K2CANFD: start 59, 2 bit, little-endian, data-type-policy=OVERRIDE, i-signal-type=PRIMITIVE, init-value=0, base-type=BT_NVEM_Freigabe_ORU4, compu {0=Cx0_Init (CM_NVEM_Freigabe_ORU4_Cx0_Init), 1=Cx1_keine_Freigabe (CM_NVEM_Freigabe_ORU4_Cx1_keine_Freigabe), 2=Cx2_Freigabe_erteilt (CM_NVEM_Freigabe_ORU4_Cx2_Freigabe_erteilt), 3=Cx3_Veto_Freigabe (CM_NVEM_Freigabe_ORU4_Cx3_Veto_Freigabe)}, range raw 0..3, transfer-property=PENDING  # Bestätigung oder Ablehnung eines konkreten, angefragten Online Updates durch das Energiemanagements
          signal NVEM_Verbraucherabsch_Anz_XIX_BEM_02_XIX_E3V_K2CANFD: start 61, 1 bit, little-endian, data-type-policy=OVERRIDE, i-signal-type=PRIMITIVE, init-value=0, base-type=BT_NVEM_Verbraucherabsch_Anz, compu {0=Cx0_keine_Anzeige (CM_NVEM_Verbraucherabsch_Anz_Cx0_keine_Anzeige), 1=Cx1_Anzeige_aktiv (CM_NVEM_Verbraucherabsch_Anz_Cx1_Anzeige_aktiv)}, range raw 0..1, transfer-property=PENDING  # Information über eine Verbraucherbschaltung durch das Energiemanagement
          signal NVEM_HV_Stuetzung_aktiv_XIX_BEM_02_XIX_E3V_K2CANFD: start 62, 2 bit, little-endian, data-type-policy=OVERRIDE, i-signal-type=PRIMITIVE, init-value=2, base-type=BT_NVEM_HV_Stuetzung_aktiv, invalid-value=Invalid_NVEM_HV_Stuetzung_aktiv_XIX_BEM_02_XIX_E3V_K2CANFD:3, compu {0=Cx0_HV_OFF (CM_NVEM_HV_Stuetzung_aktiv_Cx0_HV_OFF), 1=Cx1_HV_ON (CM_NVEM_HV_Stuetzung_aktiv_Cx1_HV_ON), 2=Cx2_INIT (CM_NVEM_HV_Stuetzung_aktiv_Cx2_INIT), 3=Cx3_Fehler (CM_NVEM_HV_Stuetzung_aktiv_Cx3_Fehler)}, range raw 0..3, transfer-property=PENDING  # signal from ICAS1 to ICAS3 to inform about status of support of HV for NV system
      frame Blinkmodi_02_XIX_E3V_K2CANFD: id 0x366, to SAM, frame-length=8, can-addressing-mode=STANDARD, can-frame-rx-behavior=CAN-FD, can-frame-tx-behavior=CAN-FD
        pdu Blinkmodi_02_XIX_E3V_K2CANFD: length=8, minimum-delay=0.01, transmission-mode-false-timing={cyclic-timing={time-offset=0.0, time-period=1.0}, event-controlled-timing={number-of-repetitions=5, repetition-period=0.05}}, transmission-mode-true-timing={cyclic-timing={time-offset=0.0, time-period=0.05}, event-controlled-timing={number-of-repetitions=5, repetition-period=0.05}}, unused-bit-pattern=0  # Nur die Kombination des statischen und toggelnden Signals ergibt den Blinktakt für die Hell & Dunkelphase
          transmission-mode-conditions:
            {data-filter={data-filter-type=MASKED-NEW-DIFFERS-X, mask=1, x=0}, i-signal-in-i-pdu=BM_Rollenmodus_Blinken}
            {data-filter={data-filter-type=MASKED-NEW-DIFFERS-X, mask=1, x=0}, i-signal-in-i-pdu=BM_Recas}
          signal Blinkmodi_02_CRC_XIX_Blinkmodi_02_XIX_E3V_K2CANFD: start 0, 8 bit, little-endian, data-type-policy=OVERRIDE, i-signal-type=PRIMITIVE, base-type=BT_Blinkmodi_02_CRC, compu {phys=raw for raw 0..255}, range phys 0..255, raw 0..255, transfer-property=PENDING  # Für MLB: Berechnung siehe Lastenheft "Kommunikationsabsicherung für FlexRay und CAN" Ab MQB und MLBevo: Berechnung siehe Lastenheft "End-to-End Kommunikationsabsicherung" Endwerte siehe Begleitdokument "S-PDU Kennungsfolgen"
          signal Blinkmodi_02_BZ_XIX_Blinkmodi_02_XIX_E3V_K2CANFD: start 8, 4 bit, little-endian, data-type-policy=OVERRIDE, i-signal-type=PRIMITIVE, base-type=BT_Blinkmodi_02_BZ, compu {phys=raw for raw 0..15}, range phys 0..15, raw 0..15, transfer-property=PENDING  # 4bit Botschaftszähler, wird mit jeder Sendebotschaft inkrementiert
          signal BM_ZV_auf_XIX_Blinkmodi_02_XIX_E3V_K2CANFD: start 12, 1 bit, little-endian, data-type-policy=OVERRIDE, i-signal-type=PRIMITIVE, init-value=0, base-type=BT_BM_ZV_auf, compu {0=Cx0_inaktiv (CM_BM_ZV_auf_Cx0_inaktiv), 1=Cx1_aktiv (CM_BM_ZV_auf_Cx1_aktiv)}, range raw 0..1, transfer-property=TRIGGERED-ON-CHANGE, to SAM(timeout 5 s)  # Blinken bei ZV auf
          signal BM_ZV_zu_XIX_Blinkmodi_02_XIX_E3V_K2CANFD: start 13, 1 bit, little-endian, data-type-policy=OVERRIDE, i-signal-type=PRIMITIVE, init-value=0, base-type=BT_BM_ZV_zu, compu {0=Cx0_inaktiv (CM_BM_ZV_zu_Cx0_inaktiv), 1=Cx1_aktiv (CM_BM_ZV_zu_Cx1_aktiv)}, range raw 0..1, transfer-property=TRIGGERED-ON-CHANGE, to SAM(timeout 5 s)  # Blinken bei ZV zu
          signal BM_DWA_ein_XIX_Blinkmodi_02_XIX_E3V_K2CANFD: start 14, 1 bit, little-endian, data-type-policy=OVERRIDE, i-signal-type=PRIMITIVE, init-value=0, base-type=BT_BM_DWA_ein, compu {0=Cx0_inaktiv (CM_BM_DWA_ein_Cx0_inaktiv), 1=Cx1_aktiv (CM_BM_DWA_ein_Cx1_aktiv)}, range raw 0..1, transfer-property=TRIGGERED-ON-CHANGE  # Status Quittierungsblinken DWA
          signal BM_DWA_Alarm_XIX_Blinkmodi_02_XIX_E3V_K2CANFD: start 15, 1 bit, little-endian, data-type-policy=OVERRIDE, i-signal-type=PRIMITIVE, init-value=0, base-type=BT_BM_DWA_Alarm, compu {0=Cx0_inaktiv (CM_BM_DWA_Alarm_Cx0_inaktiv), 1=Cx1_aktiv (CM_BM_DWA_Alarm_Cx1_aktiv)}, range raw 0..1, transfer-property=TRIGGERED-ON-CHANGE  # Status DWA-Alarmblinken
          signal BM_Crash_XIX_Blinkmodi_02_XIX_E3V_K2CANFD: start 16, 1 bit, little-endian, data-type-policy=OVERRIDE, i-signal-type=PRIMITIVE, init-value=0, base-type=BT_BM_Crash, compu {0=Cx0_inaktiv (CM_BM_Crash_Cx0_inaktiv), 1=Cx1_aktiv (CM_BM_Crash_Cx1_aktiv)}, range raw 0..1, transfer-property=TRIGGERED-ON-CHANGE  # Status Crashblinken
          signal BM_Panik_XIX_Blinkmodi_02_XIX_E3V_K2CANFD: start 17, 1 bit, little-endian, data-type-policy=OVERRIDE, i-signal-type=PRIMITIVE, init-value=0, base-type=BT_BM_Panik, compu {0=Cx0_inaktiv (CM_BM_Panik_Cx0_inaktiv), 1=Cx1_aktiv (CM_BM_Panik_Cx1_aktiv)}, range raw 0..1, transfer-property=TRIGGERED-ON-CHANGE  # Panikblinken
          signal BM_Not_Bremsung_XIX_Blinkmodi_02_XIX_E3V_K2CANFD: start 18, 1 bit, little-endian, data-type-policy=OVERRIDE, i-signal-type=PRIMITIVE, init-value=0, base-type=BT_BM_Not_Bremsung, compu {0=Cx0_kein_blinken (CM_BM_Not_Bremsung_Cx0_kein_blinken), 1=Cx1_Notbremswarnblinken_aktiv (CM_BM_Not_Bremsung_Cx1_Notbremswarnblinken_aktiv)}, range raw 0..1, transfer-property=TRIGGERED-ON-CHANGE  # Das Signal BM_Not_Bremsung zeigt an, ob ein Warnblinken aufgrund einer vom Bremssystem signalisierten Notbremsung aktiv ist.
          signal BM_GDO_XIX_Blinkmodi_02_XIX_E3V_K2CANFD: start 19, 1 bit, little-endian, data-type-policy=OVERRIDE, i-signal-type=PRIMITIVE, init-value=0, base-type=BT_BM_GDO, compu {0=Cx0_inaktiv (CM_BM_GDO_Cx0_inaktiv), 1=Cx1_aktiv (CM_BM_GDO_Cx1_aktiv)}, range raw 0..1, transfer-property=TRIGGERED-ON-CHANGE  # Blinken bei UGDO anlernen
          signal BM_Warnblinken_XIX_Blinkmodi_02_XIX_E3V_K2CANFD: start 20, 1 bit, little-endian, data-type-policy=OVERRIDE, i-signal-type=PRIMITIVE, init-value=0, base-type=BT_BM_Warnblinken, compu {0=Cx0_inaktiv (CM_BM_Warnblinken_Cx0_inaktiv), 1=Cx1_aktiv (CM_BM_Warnblinken_Cx1_aktiv)}, range raw 0..1, transfer-property=TRIGGERED-ON-CHANGE, to SAM(timeout 5 s)  # Warnblinken
          signal BM_Taxi_Notalarm_XIX_Blinkmodi_02_XIX_E3V_K2CANFD: start 21, 1 bit, little-endian, data-type-policy=OVERRIDE, i-signal-type=PRIMITIVE, init-value=0, base-type=BT_BM_Taxi_Notalarm, compu {0=Cx0_inaktiv (CM_BM_Taxi_Notalarm_Cx0_inaktiv), 1=Cx1_aktiv (CM_BM_Taxi_Notalarm_Cx1_aktiv)}, range raw 0..1, transfer-property=TRIGGERED-ON-CHANGE  # Blinken bei Taxi-Not-Alarm
          signal BM_Telematik_XIX_Blinkmodi_02_XIX_E3V_K2CANFD: start 22, 1 bit, little-endian, data-type-policy=OVERRIDE, i-signal-type=PRIMITIVE, init-value=0, base-type=BT_BM_Telematik, compu {0=Cx0_inaktiv (CM_BM_Telematik_Cx0_inaktiv), 1=Cx1_aktiv (CM_BM_Telematik_Cx1_aktiv)}, range raw 0..1, transfer-property=TRIGGERED-ON-CHANGE  # Telematikblinken
          signal BM_links_XIX_Blinkmodi_02_XIX_E3V_K2CANFD: start 23, 1 bit, little-endian, data-type-policy=OVERRIDE, i-signal-type=PRIMITIVE, init-value=0, base-type=BT_BM_links, compu {0=Cx0_inaktiv (CM_BM_links_Cx0_inaktiv), 1=Cx1_aktiv (CM_BM_links_Cx1_aktiv)}, range raw 0..1, transfer-property=TRIGGERED-ON-CHANGE  # Richtungsblinken links
          signal BM_rechts_XIX_Blinkmodi_02_XIX_E3V_K2CANFD: start 24, 1 bit, little-endian, data-type-policy=OVERRIDE, i-signal-type=PRIMITIVE, init-value=0, base-type=BT_BM_rechts, compu {0=Cx0_inaktiv (CM_BM_rechts_Cx0_inaktiv), 1=Cx1_aktiv (CM_BM_rechts_Cx1_aktiv)}, range raw 0..1, transfer-property=TRIGGERED-ON-CHANGE  # Richtungsblinken rechts
          signal Blinken_li_Fzg_Takt_XIX_Blinkmodi_02_XIX_E3V_K2CANFD: start 25, 1 bit, little-endian, data-type-policy=OVERRIDE, i-signal-type=PRIMITIVE, init-value=0, base-type=BT_Blinken_li_Fzg_Takt, compu {0=Cx0_Blinker_links_ausgeschaltet (CM_Blinken_li_Fzg_Takt_Cx0_Blinker_links_ausgeschaltet), 1=Cx1_Blinker_links_eingeschaltet (CM_Blinken_li_Fzg_Takt_Cx1_Blinker_links_eingeschaltet)}, range raw 0..1, transfer-property=TRIGGERED-ON-CHANGE  # Fzg-Takt Blinker links
          signal Blinken_re_Fzg_Takt_XIX_Blinkmodi_02_XIX_E3V_K2CANFD: start 26, 1 bit, little-endian, data-type-policy=OVERRIDE, i-signal-type=PRIMITIVE, init-value=0, base-type=BT_Blinken_re_Fzg_Takt, compu {0=Cx0_Blinker_rechts_ausgeschaltet (CM_Blinken_re_Fzg_Takt_Cx0_Blinker_rechts_ausgeschaltet), 1=Cx1_Blinker_rechts_eingeschaltet (CM_Blinken_re_Fzg_Takt_Cx1_Blinker_rechts_eingeschaltet)}, range raw 0..1, transfer-property=TRIGGERED-ON-CHANGE  # Fzg-Takt Blinker rechts
          signal Blinken_li_Kombi_Takt_XIX_Blinkmodi_02_XIX_E3V_K2CANFD: start 27, 1 bit, little-endian, data-type-policy=OVERRIDE, i-signal-type=PRIMITIVE, init-value=0, base-type=BT_Blinken_li_Kombi_Takt, compu {0=Cx0_Blinkerkontrolllampe_links_ausgeschaltet (CM_Blinken_li_Kombi_Takt_Cx0_Blinkerkontrolllampe_links_ausgeschaltet), 1=Cx1_Blinkerkontrolllampe_links_eingeschaltet (CM_Blinken_li_Kombi_Takt_Cx1_Blinkerkontrolllampe_links_eingeschaltet)}, range raw 0..1, transfer-property=TRIGGERED-ON-CHANGE  # Kombi-Takt Blinker links
          signal Blinken_re_Kombi_Takt_XIX_Blinkmodi_02_XIX_E3V_K2CANFD: start 28, 1 bit, little-endian, data-type-policy=OVERRIDE, i-signal-type=PRIMITIVE, init-value=0, base-type=BT_Blinken_re_Kombi_Takt, compu {0=Cx0_Blinkerkontrolllampe_rechts_ausgeschaltet (CM_Blinken_re_Kombi_Takt_Cx0_Blinkerkontrolllampe_rechts_ausgeschaltet), 1=Cx1_Blinkerkontrolllampe_rechts_eingeschaltet (CM_Blinken_re_Kombi_Takt_Cx1_Blinkerkontrolllampe_rechts_eingeschaltet)}, range raw 0..1, transfer-property=TRIGGERED-ON-CHANGE  # Kombi-Takt Blinker rechts
          signal BM_NBA_n_codiert_n_aktiv_XIX_Blinkmodi_02_XIX_E3V_K2CANFD: start 29, 1 bit, little-endian, data-type-policy=OVERRIDE, i-signal-type=PRIMITIVE, init-value=1, base-type=BT_BM_NBA_n_codiert_n_aktiv, compu {0=Cx0_codiert_AND_kein_Fehler (CM_BM_NBA_n_codiert_n_aktiv_Cx0_codiert_AND_kein_Fehler), 1=Cx1_nicht_codiert_OR_Fehler_erkannt (CM_BM_NBA_n_codiert_n_aktiv_Cx1_nicht_codiert_OR_Fehler_erkannt)}, range raw 0..1, transfer-property=TRIGGERED-ON-CHANGE-WITHOUT-REPETITION  # Notbremsanzeige nicht codiert/nicht aktiv (Fehler)
          signal BM_NBA_Status_XIX_Blinkmodi_02_XIX_E3V_K2CANFD: start 30, 2 bit, little-endian, data-type-policy=OVERRIDE, i-signal-type=PRIMITIVE, init-value=0, base-type=BT_BM_NBA_Status, compu {0=Cx0_NBA_nicht_aktiv (CM_BM_NBA_Status_Cx0_NBA_nicht_aktiv), 1=Cx1_BRL_Dunkelphase (CM_BM_NBA_Status_Cx1_BRL_Dunkelphase), 3=Cx3_BRL_Hellphase (CM_BM_NBA_Status_Cx3_BRL_Hellphase)}, range raw 0..3, transfer-property=TRIGGERED-ON-CHANGE  # Notbremsanzeige Status nicht aktiv / BRL Dunkelphase / BRL Hellphase
          signal BM_WBT_Beleuchtung_XIX_Blinkmodi_02_XIX_E3V_K2CANFD: start 32, 1 bit, little-endian, data-type-policy=OVERRIDE, i-signal-type=PRIMITIVE, init-value=0, base-type=BT_BM_WBT_Beleuchtung, compu {0=Cx0_inaktiv (CM_BM_WBT_Beleuchtung_Cx0_inaktiv), 1=Cx1_aktiv (CM_BM_WBT_Beleuchtung_Cx1_aktiv)}, range raw 0..1, transfer-property=TRIGGERED-ON-CHANGE-WITHOUT-REPETITION, to SAM(timeout 5 s)  # Aktivierung Warnblinktasterfunktionsbeleuchtung Warnblinktasterfunktionsbeleuchtung soll aktiviert werden (statisch auf 1)
          signal BM_HD_Oeffnung_angelernt_XIX_Blinkmodi_02_XIX_E3V_K2CANFD: start 33, 1 bit, little-endian, data-type-policy=OVERRIDE, i-signal-type=PRIMITIVE, init-value=0, base-type=BT_BM_HD_Oeffnung_angelernt, compu {0=Cx0_keine_Quittierung (CM_BM_HD_Oeffnung_angelernt_Cx0_keine_Quittierung), 1=Cx1_Quittierung (CM_BM_HD_Oeffnung_angelernt_Cx1_Quittierung)}, range raw 0..1, transfer-property=TRIGGERED-ON-CHANGE-WITHOUT-REPETITION  # HD_Rueckmeld_prog eine Blinkerquittierung wird beim BCM2 angefordert. Wenn die Geschwindigkeit kleiner einer vorgegebenen Schwelle (default 2km/h) ist wird das Signal BM_HD_Öffnung_angelernt versendet und die Blinkerquittierung ausgelöst
          signal BM_Autobahn_XIX_Blinkmodi_02_XIX_E3V_K2CANFD: start 34, 1 bit, little-endian, data-type-policy=OVERRIDE, i-signal-type=PRIMITIVE, init-value=0, base-type=BT_BM_Autobahn, compu {0=Cx0_inaktiv (CM_BM_Autobahn_Cx0_inaktiv), 1=Cx1_aktiv (CM_BM_Autobahn_Cx1_aktiv)}, range raw 0..1, transfer-property=TRIGGERED-ON-CHANGE  # Status Autobahnblinken
          signal BM_Rollenmodus_Blinken_XIX_Blinkmodi_02_XIX_E3V_K2CANFD: start 35, 1 bit, little-endian, data-type-policy=OVERRIDE, i-signal-type=PRIMITIVE, init-value=0, base-type=BT_BM_Rollenmodus_Blinken, compu {0=Cx0_inaktiv (CM_BM_Rollenmodus_Blinken_Cx0_inaktiv), 1=Cx1_aktiv (CM_BM_Rollenmodus_Blinken_Cx1_aktiv)}, range raw 0..1, transfer-property=PENDING  # Das Signal wird statisch gesetzt, wenn die Blinkerart Rollenmodus_Blinken aktiv ist.
          signal BM_Recas_XIX_Blinkmodi_02_XIX_E3V_K2CANFD: start 36, 1 bit, little-endian, data-type-policy=OVERRIDE, i-signal-type=PRIMITIVE, init-value=0, base-type=BT_BM_Recas, compu {0=Cx0_kein_blinken (CM_BM_Recas_Cx0_kein_blinken), 1=Cx1_Recasblinken_aktiv (CM_BM_Recas_Cx1_Recasblinken_aktiv)}, range raw 0..1, transfer-property=PENDING  # Blinkermodus RECAS (RearEndCollisionAlertSignal)
          signal BM_Wischblinken_XIX_Blinkmodi_02_XIX_E3V_K2CANFD: start 37, 1 bit, little-endian, data-type-policy=OVERRIDE, i-signal-type=PRIMITIVE, init-value=0, base-type=BT_BM_Wischblinken, compu {0=Cx0_inaktiv (CM_BM_Wischblinken_Cx0_inaktiv), 1=Cx1_aktiv (CM_BM_Wischblinken_Cx1_aktiv)}, range raw 0..1, transfer-property=TRIGGERED-ON-CHANGE  # Blinkermodus Wisch_Blinken
          signal BM_Telematik_Abbruchgrund_XIX_Blinkmodi_02_XIX_E3V_K2CANFD: start 38, 6 bit, little-endian, data-type-policy=OVERRIDE, i-signal-type=PRIMITIVE, init-value=0, base-type=BT_BM_Telematik_Abbruchgrund, compu {0=Cx0_Init (CM_BM_Telematik_Abbruchgrund_Cx0_Init), 1=Cx1_speed_out_of_range (CM_BM_Telematik_Abbruchgrund_Cx1_speed_out_of_range), 2=Cx2_defect (CM_BM_Telematik_Abbruchgrund_Cx2_defect), 3=Cx3_clamp_s_on (CM_BM_Telematik_Abbruchgrund_Cx3_clamp_s_on), 4=Cx4_clamp_15_on (CM_BM_Telematik_Abbruchgrund_Cx4_clamp_15_on), 5=Cx5_door_open (CM_BM_Telematik_Abbruchgrund_Cx5_door_open), 6=Cx6_engine_hood_open (CM_BM_Telematik_Abbruchgrund_Cx6_engine_hood_open), 7=Cx7_trunk_open (CM_BM_Telematik_Abbruchgrund_Cx7_trunk_open), 8=Cx8_convertible_top_not_locked (CM_BM_Telematik_Abbruchgrund_Cx8_convertible_top_not_locked), 9=Cx9_horn_activated_by_user (CM_BM_Telematik_Abbruchgrund_Cx9_horn_activated_by_user), 10=Cxa_Higher_Prioritiy_Function_active (CM_BM_Telematik_Abbruchgrund_Cxa_Higher_Prioritiy_Function_active), 11=Cxb_Central_Lock_status_changed (CM_BM_Telematik_Abbruchgrund_Cxb_Central_Lock_status_changed), 12=Cxc_Request_Dropped_by_Requester (CM_BM_Telematik_Abbruchgrund_Cxc_Request_Dropped_by_Requester), 13=Cxd_Service_Duration_Expired (CM_BM_Telematik_Abbruchgrund_Cxd_Service_Duration_Expired), 14=Cxe_not_possible_due_to_coding (CM_BM_Telematik_Abbruchgrund_Cxe_not_possible_due_to_coding), 15=Cxf_no_reason_or_unknown_timeout (CM_BM_Telematik_Abbruchgrund_Cxf_no_reason_or_unknown_timeout)}, range raw 0..15, transfer-property=TRIGGERED-ON-CHANGE  # Gibt bei erwaretem aber ausbleibendem Flankenanstieg der BM_Telematik an wieso die Ausführung verhindert wurde. Bei Flankenabfall der BM_Telematik wird angegeben wieso die Ausführung beendet wurde. Bei nicht bereitem Sender soll "init" gesendet werden, bei bereitem Sender soll "no reason given / unknown timeout" gesendet werden. Bei einem Signalwechsel soll immer mindestens 5 mal der neue Wert in schnellem Zyklus gesendet werden.
          signal BM_PiloPa_XIX_Blinkmodi_02_XIX_E3V_K2CANFD: start 44, 1 bit, little-endian, data-type-policy=OVERRIDE, i-signal-type=PRIMITIVE, base-type=BT_BM_PiloPa, compu {0=Cx0_PiloPa_Blinkerquittierung_inaktiv (CM_BM_PiloPa_Cx0_PiloPa_Blinkerquittierung_inaktiv), 1=Cx1_PiloPa_Blinkerquittierung_aktiv (CM_BM_PiloPa_Cx1_PiloPa_Blinkerquittierung_aktiv)}, range raw 0..1, transfer-property=TRIGGERED-ON-CHANGE  # Quittierungsblinken bei pilotierten Parkvorgängen
          signal SAL_TA_Blinken_Status_XIX_Blinkmodi_02_XIX_E3V_K2CANFD: start 45, 3 bit, little-endian, data-type-policy=OVERRIDE, i-signal-type=PRIMITIVE, init-value=0, base-type=BT_SAL_TA_Blinken_Status, compu {0=Cx0_init (CM_SAL_TA_Blinken_Status_Cx0_init), 1=Cx1_nicht_bereit (CM_SAL_TA_Blinken_Status_Cx1_nicht_bereit), 2=Cx2_bereit (CM_SAL_TA_Blinken_Status_Cx2_bereit), 3=Cx3_aktiv_links (CM_SAL_TA_Blinken_Status_Cx3_aktiv_links), 4=Cx4_aktiv_rechts (CM_SAL_TA_Blinken_Status_Cx4_aktiv_rechts)}, range raw 0..4, transfer-property=TRIGGERED-ON-CHANGE  # SAL RückmeldungTravelAssist Blinker-Status an Funktion TA (MFK)
          signal SAL_RHP_Blinken_Status_XIX_Blinkmodi_02_XIX_E3V_K2CANFD: start 49, 3 bit, little-endian, data-type-policy=OVERRIDE, i-signal-type=PRIMITIVE, init-value=0, base-type=BT_SAL_RHP_Blinken_Status, compu {0=Cx0_init (CM_SAL_RHP_Blinken_Status_Cx0_init), 1=Cx1_nicht_bereit (CM_SAL_RHP_Blinken_Status_Cx1_nicht_bereit), 2=Cx2_bereit (CM_SAL_RHP_Blinken_Status_Cx2_bereit), 3=Cx3_aktiv_links (CM_SAL_RHP_Blinken_Status_Cx3_aktiv_links), 4=Cx4_aktiv_rechts (CM_SAL_RHP_Blinken_Status_Cx4_aktiv_rechts)}, range raw 0..4, transfer-property=TRIGGERED-ON-CHANGE-WITHOUT-REPETITION  # SAL Rückmeldung Rush Hour Pilot Blinker-Status an Funktion RHP
          signal SAL_RHP_Warnblinken_XIX_Blinkmodi_02_XIX_E3V_K2CANFD: start 52, 1 bit, little-endian, data-type-policy=OVERRIDE, i-signal-type=PRIMITIVE, init-value=0, base-type=BT_SAL_RHP_Warnblinken, compu {0=Cx0_inaktiv (CM_SAL_RHP_Warnblinken_Cx0_inaktiv), 1=Cx1_aktiv (CM_SAL_RHP_Warnblinken_Cx1_aktiv)}, range raw 0..1, transfer-property=TRIGGERED-ON-CHANGE-WITHOUT-REPETITION  # Rückkanal des durch RHP angeforderten Warnblinken
          signal DWA_Alarmquelle_XIX_Blinkmodi_02_XIX_E3V_K2CANFD: start 59, 5 bit, little-endian, data-type-policy=OVERRIDE, i-signal-type=PRIMITIVE, init-value=30, base-type=BT_DWA_Alarmquelle, invalid-value=Invalid_DWA_Alarmquelle_XIX_Blinkmodi_02_XIX_E3V_K2CANFD:31, compu {0=Cx0_kein_Ausloesegrund (CM_DWA_Alarmquelle_Cx0_kein_Ausloesegrund), 1=Cx1_Tuerkontakt_Fahrertuer (CM_DWA_Alarmquelle_Cx1_Tuerkontakt_Fahrertuer), 2=Cx2_Tuerkontakt_Beifahrertuer (CM_DWA_Alarmquelle_Cx2_Tuerkontakt_Beifahrertuer), 3=Cx3_Tuerkontakt_hinten_links (CM_DWA_Alarmquelle_Cx3_Tuerkontakt_hinten_links), 4=Cx4_Tuerkontakt_hinten_rechts (CM_DWA_Alarmquelle_Cx4_Tuerkontakt_hinten_rechts), 5=Cx5_Motorhaubenkontakt_vorne (CM_DWA_Alarmquelle_Cx5_Motorhaubenkontakt_vorne), 6=Cx6_Kofferraum_hinten (CM_DWA_Alarmquelle_Cx6_Kofferraum_hinten), 7=Cx7_Masseschleife_der_Heckscheibe (CM_DWA_Alarmquelle_Cx7_Masseschleife_der_Heckscheibe), 8=Cx8_Innenraumueberwachung (CM_DWA_Alarmquelle_Cx8_Innenraumueberwachung), 9=Cx9_Alarm_durch_Noteinstieg (CM_DWA_Alarmquelle_Cx9_Alarm_durch_Noteinstieg), 10=Cxa_Sounder (CM_DWA_Alarmquelle_Cxa_Sounder), 11=Cxb_Neigungssensor (CM_DWA_Alarmquelle_Cxb_Neigungssensor), 12=Cxc_TSG_FT_am_CAN_Bus (CM_DWA_Alarmquelle_Cxc_TSG_FT_am_CAN_Bus), 13=Cxd_TSG_BT_am_CAN_Bus (CM_DWA_Alarmquelle_Cxd_TSG_BT_am_CAN_Bus), 14=Cxe_TSG_HFS_am_CAN_Bus (CM_DWA_Alarmquelle_Cxe_TSG_HFS_am_CAN_Bus), 15=Cxf_TSG_HBFS_am_CAN_Bus (CM_DWA_Alarmquelle_Cxf_TSG_HBFS_am_CAN_Bus), 16=Cx10_Klemme_15 (CM_DWA_Alarmquelle_Cx10_Klemme_15), 17=Cx11_Klemme_15sig (CM_DWA_Alarmquelle_Cx11_Klemme_15sig), 18=Cx12_frei (CM_DWA_Alarmquelle_Cx12_frei), 19=Cx13_Anhaengerueberwachung (CM_DWA_Alarmquelle_Cx13_Anhaengerueberwachung), 20=Cx14_Scheinwerferueberwachung_links (CM_DWA_Alarmquelle_Cx14_Scheinwerferueberwachung_links), 21=Cx15_Scheinwerferueberwachung_rechts (CM_DWA_Alarmquelle_Cx15_Scheinwerferueberwachung_rechts), 22=Cx16_Handschuhkasten (CM_DWA_Alarmquelle_Cx16_Handschuhkasten), 23=Cx17_Verdeckueberwachung (CM_DWA_Alarmquelle_Cx17_Verdeckueberwachung), 24=Cx18_OBD_Alarm (CM_DWA_Alarmquelle_Cx18_OBD_Alarm), 25=Cx19_Power_on_Reset (CM_DWA_Alarmquelle_Cx19_Power_on_Reset), 30=Cx1e_Init (CM_DWA_Alarmquelle_Cx1e_Init), 31=Cx1f_Fehler (CM_DWA_Alarmquelle_Cx1f_Fehler)}, range raw 0..31, transfer-property=PENDING  # Signalisiert den Auslösegrund der DWA
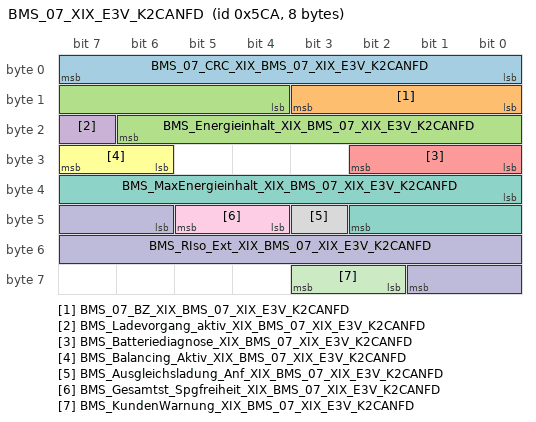
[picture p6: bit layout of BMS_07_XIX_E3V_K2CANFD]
      frame BMS_07_XIX_E3V_K2CANFD: id 0x5CA, to SAM, frame-length=8, can-addressing-mode=STANDARD, can-frame-rx-behavior=CAN-FD, can-frame-tx-behavior=CAN-FD
        pdu BMS_07_XIX_E3V_K2CANFD: length=8, minimum-delay=0.05, transmission-mode-true-timing={cyclic-timing={time-offset=0.0, time-period=0.5}, event-controlled-timing={number-of-repetitions=0, repetition-period=0.0}}, unused-bit-pattern=0
          signal BMS_07_CRC_XIX_BMS_07_XIX_E3V_K2CANFD: start 0, 8 bit, little-endian, data-type-policy=OVERRIDE, i-signal-type=PRIMITIVE, base-type=BT_BMS_07_CRC, compu {phys=raw for raw 0..255}, range phys 0..255, raw 0..255, transfer-property=PENDING  # Für MLB: "Berechnung siehe Lastenheft "Kommunikationsabsicherung für FlexRay und CAN"" Ab MQB und MLBevo: "Berechnung siehe Lastenheft "End-to-End Kommunikationsabsicherung"" Endwerte siehe Begleitdokument "S-PDU Kennungsfolgen"
          signal BMS_07_BZ_XIX_BMS_07_XIX_E3V_K2CANFD: start 8, 4 bit, little-endian, data-type-policy=OVERRIDE, i-signal-type=PRIMITIVE, base-type=BT_BMS_07_BZ, compu {phys=raw for raw 0..15}, range phys 0..15, raw 0..15, transfer-property=PENDING
          signal BMS_Energieinhalt_XIX_BMS_07_XIX_E3V_K2CANFD: start 12, 11 bit, little-endian, data-type-policy=OVERRIDE, i-signal-type=PRIMITIVE, init-value=2046, base-type=BT_BMS_Energieinhalt, invalid-value=Invalid_BMS_Energieinhalt_XIX_BMS_07_XIX_E3V_K2CANFD:2047, compu {phys=raw*50 for raw 0..2045, 2046=Cx7fe_Init (CM_BMS_Energieinhalt_Cx7fe_Init), 2047=Cx7ff_Fehler (CM_BMS_Energieinhalt_Cx7ff_Fehler); unit Unit_WattHour}, range phys 0..102250 Unit_WattHour, raw 0..2047, unit=Unit_WattHour, transfer-property=PENDING  # aktuell nutzbarer Energieinhalt der HV-Batterie (bezogen auf ein definiertes mittleres Belastungsprofil)
          signal BMS_Ladevorgang_aktiv_XIX_BMS_07_XIX_E3V_K2CANFD: start 23, 1 bit, little-endian, data-type-policy=OVERRIDE, i-signal-type=PRIMITIVE, init-value=0, base-type=BT_BMS_Ladevorgang_aktiv, compu {0=Cx0_inaktiv (CM_BMS_Ladevorgang_aktiv_Cx0_inaktiv), 1=Cx1_aktiv (CM_BMS_Ladevorgang_aktiv_Cx1_aktiv)}, range raw 0..1, transfer-property=PENDING  # Signalisiert aktiven Ladevorgang, Ladegerät und DC/DC aktiv. Signal bleibt nach Kl.15 ein aktiv, bis ESP_Stillstandsflag gelöscht. Abhängigkeit zu BMS_Energieinhalt
          signal BMS_Batteriediagnose_XIX_BMS_07_XIX_E3V_K2CANFD: start 24, 3 bit, little-endian, data-type-policy=OVERRIDE, i-signal-type=PRIMITIVE, init-value=1, base-type=BT_BMS_Batteriediagnose, invalid-value=Invalid_BMS_Batteriediagnose_XIX_BMS_07_XIX_E3V_K2CANFD:7, compu {1=Cx1_Anzeige_Batterie (CM_BMS_Batteriediagnose_Cx1_Anzeige_Batterie), 4=Cx4_Anzeige_Batterie_OK (CM_BMS_Batteriediagnose_Cx4_Anzeige_Batterie_OK), 5=Cx5_Anzeige_Batterie_Laden (CM_BMS_Batteriediagnose_Cx5_Anzeige_Batterie_Laden), 6=Cx6_Anzeige_Batterie_Pruefen (CM_BMS_Batteriediagnose_Cx6_Anzeige_Batterie_Pruefen), 7=Cx7_Fehler (CM_BMS_Batteriediagnose_Cx7_Fehler)}, range raw 1..7, transfer-property=TRIGGERED-ON-CHANGE-WITHOUT-REPETITION  # Anzeige von Textwarnungen
          signal BMS_Balancing_Aktiv_XIX_BMS_07_XIX_E3V_K2CANFD: start 30, 2 bit, little-endian, data-type-policy=OVERRIDE, i-signal-type=PRIMITIVE, init-value=0, base-type=BT_BMS_Balancing_Aktiv, compu {0=Cx0_Init (CM_BMS_Balancing_Aktiv_Cx0_Init), 1=Cx1_aktiv (CM_BMS_Balancing_Aktiv_Cx1_aktiv), 2=Cx2_nicht_aktiv (CM_BMS_Balancing_Aktiv_Cx2_nicht_aktiv)}, range raw 0..2, transfer-property=PENDING  # Signal zeigt an, ob mindestens eine Zelle der HV Batterie balanciert wird
          signal BMS_MaxEnergieinhalt_XIX_BMS_07_XIX_E3V_K2CANFD: start 32, 11 bit, little-endian, data-type-policy=OVERRIDE, i-signal-type=PRIMITIVE, init-value=2046, base-type=BT_BMS_MaxEnergieinhalt, invalid-value=Invalid_BMS_MaxEnergieinhalt_XIX_BMS_07_XIX_E3V_K2CANFD:2047, compu {phys=raw*50 for raw 0..2045, 2046=Cx7fe_Init (CM_BMS_MaxEnergieinhalt_Cx7fe_Init), 2047=Cx7ff_Fehler (CM_BMS_MaxEnergieinhalt_Cx7ff_Fehler); unit Unit_WattHour}, range phys 0..102250 Unit_WattHour, raw 0..2047, unit=Unit_WattHour, transfer-property=PENDING  # maximaler nutzbarer Energieinhalt der HV-Batterie (bezogen auf Last KBI_RWDS_Lastprofil bei SOC=100%) Abhängig von KBI_RWDS_Lastprofil
          signal BMS_Ausgleichsladung_Anf_XIX_BMS_07_XIX_E3V_K2CANFD: start 43, 1 bit, little-endian, data-type-policy=OVERRIDE, i-signal-type=PRIMITIVE, init-value=0, base-type=BT_BMS_Ausgleichsladung_Anf, compu {1=Cx1_Balancing_Request (CM_BMS_Ausgleichsladung_Anf_Cx1_Balancing_Request)}, range raw 1, transfer-property=PENDING  # BMS wünscht eine Ausgleichsladung Flag derzeit ungenutzt, da BalancingModus im Detail noch nicht geklärt.
          signal BMS_Gesamtst_Spgfreiheit_XIX_BMS_07_XIX_E3V_K2CANFD: start 44, 2 bit, little-endian, data-type-policy=OVERRIDE, i-signal-type=PRIMITIVE, init-value=0, base-type=BT_BMS_Gesamtst_Spgfreiheit, compu {0=Cx0_Funktion_nicht_aktiviert (CM_BMS_Gesamtst_Spgfreiheit_Cx0_Funktion_nicht_aktiviert), 1=Cx1_HV_System_spannungsfrei (CM_BMS_Gesamtst_Spgfreiheit_Cx1_HV_System_spannungsfrei), 2=Cx2_HV_System_nicht_spannungsfrei (CM_BMS_Gesamtst_Spgfreiheit_Cx2_HV_System_nicht_spannungsfrei), 3=Cx3_Fehler_nicht_spannungsfrei (CM_BMS_Gesamtst_Spgfreiheit_Cx3_Fehler_nicht_spannungsfrei)}, range raw 0..3, transfer-property=TRIGGERED-ON-CHANGE-WITHOUT-REPETITION  # 0 = Funktion nicht aktiviert 1 = HV-System spannungsfrei (U_Zwkr von BMS, LE und Ladegerät < 20V, DCLadestecker nicht gesteckt und Service Disconnect entriegelt) 2 = HV-System nicht spannungsfrei (U_Zwkr von BMS, LE und Ladegerät >= 20V, Ladestecker gesteckt oder Service Disconnect verriegelt) 3 = Fehler (z. B. Fehler in der eigenen Sensorik, ein Signal fehlt oder Fehler in Leistungselektronik oder Ladegerät)
          signal BMS_RIso_Ext_XIX_BMS_07_XIX_E3V_K2CANFD: start 46, 12 bit, little-endian, data-type-policy=OVERRIDE, i-signal-type=PRIMITIVE, init-value=4094, base-type=BT_BMS_RIso_Ext, invalid-value=Invalid_BMS_RIso_Ext_XIX_BMS_07_XIX_E3V_K2CANFD:4095, compu {phys=raw*5 for raw 0..4093, 4094=Cxffe_Init (CM_BMS_RIso_Ext_Cxffe_Init), 4095=Cxfff_Fehler (CM_BMS_RIso_Ext_Cxfff_Fehler); unit Unit_KiloOhm}, range phys 0..20465 Unit_KiloOhm, raw 0..4095, unit=Unit_KiloOhm, transfer-property=PENDING  # Minimum des Isolationswiderstands zwischen Batteriegehäuse und HV+ bzw. Batteriegehäuse und HV- bei geschlossenen Schützen (externe Iso Messung)
          signal BMS_KundenWarnung_XIX_BMS_07_XIX_E3V_K2CANFD: start 58, 2 bit, little-endian, data-type-policy=OVERRIDE, i-signal-type=PRIMITIVE, init-value=0, base-type=BT_BMS_KundenWarnung, compu {0=Cx0_keine_Warnung (CM_BMS_KundenWarnung_Cx0_keine_Warnung), 1=Cx1_Warnung_Temperatur_Level1 (CM_BMS_KundenWarnung_Cx1_Warnung_Temperatur_Level1), 2=Cx2_Warnung_Temperatur_Level2 (CM_BMS_KundenWarnung_Cx2_Warnung_Temperatur_Level2)}, range raw 0..2, transfer-property=TRIGGERED-ON-CHANGE-WITHOUT-REPETITION, to SAM(timeout 5 s)  # Kundenwarnung und Ersatzreaktionen aufgrund von Batteriebrandgefahr
      frame CCP_BCM_CRO_01_XIX_E3V_K2CANFD: id 0x1BFC7600, to SAM, frame-length=8, can-addressing-mode=EXTENDED, can-frame-rx-behavior=CAN-FD, can-frame-tx-behavior=CAN-FD
        user defined pdu CDD_CCP_BCM_CRO_01_XIX_E3V_K2CANFD: length=8, cdd-type=EID
      frame CCP_BCM_DTO_01_XIX_E3V_K2CANFD: id 0x1BFC7601, from SAM, frame-length=8, can-addressing-mode=EXTENDED, can-frame-rx-behavior=CAN-FD, can-frame-tx-behavior=CAN-FD
        user defined pdu CDD_CCP_BCM_DTO_01_XIX_E3V_K2CANFD: length=8, cdd-type=EID
      frame CentralLocking_01_XIX_E3V_K2CANFD: id 0x12DD5528, to SAM, frame-length=24, can-addressing-mode=EXTENDED, can-frame-rx-behavior=CAN-FD, can-frame-tx-behavior=CAN-FD
        pdu CentralLocking_01_XIX_E3V_K2CANFD: length=24, transmission-mode-true-timing=cyclic-timing={time-offset=0.0, time-period=0.2}, unused-bit-pattern=0
          signal CentralLocking_01_CRC_XIX_CentralLocking_01_XIX_E3V_K2CANFD: start 0, 8 bit, little-endian, data-type-policy=OVERRIDE, i-signal-type=PRIMITIVE, init-value=0, base-type=BT_CentralLocking_01_CRC, compu {phys=raw for raw 0..255}, range phys 0..255, raw 0..255, transfer-property=PENDING
          signal CentralLocking_01_BZ_XIX_CentralLocking_01_XIX_E3V_K2CANFD: start 8, 4 bit, little-endian, data-type-policy=OVERRIDE, i-signal-type=PRIMITIVE, init-value=0, base-type=BT_CentralLocking_01_BZ, compu {phys=raw for raw 0..15}, range phys 0..15, raw 0..15, transfer-property=PENDING  # 4bit Botschaftszähler, wird mit jeder Sendebotschaft inkrementiert
          signal ZV_FD_Taste_auf_XIX_CentralLocking_01_XIX_E3V_K2CANFD: start 12, 1 bit, little-endian, data-type-policy=OVERRIDE, i-signal-type=PRIMITIVE, init-value=0, base-type=BT_ZV_FD_Taste_auf, compu {0=Cx0_Taste_FD_auf_nicht_gedrueckt (CM_ZV_FD_Taste_auf_Cx0_Taste_FD_auf_nicht_gedrueckt), 1=Cx1_Taste_FD_auf_gedrueckt (CM_ZV_FD_Taste_auf_Cx1_Taste_FD_auf_gedrueckt)}, range raw 0..1, transfer-property=PENDING  # Taster zum Öffnen der Frontklappe über BAP
          signal ZV_Anf_Fanghaken_Frontschloss_XIX_CentralLocking_01_XIX_E3V_K2CANFD: start 14, 3 bit, little-endian, data-type-policy=OVERRIDE, i-signal-type=PRIMITIVE, init-value=0, base-type=BT_ZV_Anf_Fanghaken_Frontschloss, invalid-value=Invalid_ZV_Anf_Fanghaken_Frontschloss_XIX_CentralLocking_01_XIX_E3V_K2CANFD:4, compu {0=Cx0_Init_oder_nicht_verbaut (CM_ZV_Anf_Fanghaken_Frontschloss_Cx0_Init_oder_nicht_verbaut), 1=Cx1_keine_Freigabe (CM_ZV_Anf_Fanghaken_Frontschloss_Cx1_keine_Freigabe), 2=Cx2_Ansteuerung_in_Richtung_auf (CM_ZV_Anf_Fanghaken_Frontschloss_Cx2_Ansteuerung_in_Richtung_auf), 3=Cx3_Ansteuerung_in_Richtung_zu_Sperrklinke_koppeln (CM_ZV_Anf_Fanghaken_Frontschloss_Cx3_Ansteuerung_in_Richtung_zu_Sperrklinke_koppeln) (Ansteuerung_in_Richtung_zu _(Sperrklinke_koppeln)), 4=Cx4_Fehler (CM_ZV_Anf_Fanghaken_Frontschloss_Cx4_Fehler)}, range raw 0..4, transfer-property=PENDING  # Freigabe und Anforderung der Ansteuerung Frontschloss (TrunkEntrapment und ZV) Das SAR prüft als 2. Instanz die Geschwindigkeit und kann die Ansteuerung der Sekundärverriegelung freigeben (FUSI-Anforderungen). Muss über eine E2E-Absicherung verfügen.
          signal ZV_Anf_Frontschloss_ansteuern_XIX_CentralLocking_01_XIX_E3V_K2CANFD: start 17, 3 bit, little-endian, data-type-policy=OVERRIDE, i-signal-type=PRIMITIVE, init-value=0, base-type=BT_ZV_Anf_Frontschloss_ansteuern, invalid-value=Invalid_ZV_Anf_Frontschloss_ansteuern_XIX_CentralLocking_01_XIX_E3V_K2CANFD:4, compu {0=Cx0_Init_oder_nicht_verbaut (CM_ZV_Anf_Frontschloss_ansteuern_Cx0_Init_oder_nicht_verbaut), 1=Cx1_keine_Freigabe (CM_ZV_Anf_Frontschloss_ansteuern_Cx1_keine_Freigabe), 2=Cx2_Ansteuerung_in_Richtung_auf (CM_ZV_Anf_Frontschloss_ansteuern_Cx2_Ansteuerung_in_Richtung_auf), 3=Cx3_Ansteuerung_in_Richtung_zu_Sperrklinke_koppeln (CM_ZV_Anf_Frontschloss_ansteuern_Cx3_Ansteuerung_in_Richtung_zu_Sperrklinke_koppeln) (Ansteuerung_in_Richtung_zu _(Sperrklinke_koppeln)), 4=Cx4_Fehler (CM_ZV_Anf_Frontschloss_ansteuern_Cx4_Fehler)}, range raw 0..4, transfer-property=PENDING  # Freigabe und Anforderung der Ansteuerung Frontschloss Das Signal muss über eine E2E-Absicherung verfügen.
          signal ZV_Anf_Heckschloss_ansteuern_XIX_CentralLocking_01_XIX_E3V_K2CANFD: start 20, 3 bit, little-endian, data-type-policy=OVERRIDE, i-signal-type=PRIMITIVE, init-value=0, base-type=BT_ZV_Anf_Heckschloss_ansteuern, compu {0=Cx0_Init_oder_nicht_verbaut (CM_ZV_Anf_Heckschloss_ansteuern_Cx0_Init_oder_nicht_verbaut), 1=Cx1_keine_Freigabe (CM_ZV_Anf_Heckschloss_ansteuern_Cx1_keine_Freigabe), 2=Cx2_Ansteuerung_in_Richtung_auf (CM_ZV_Anf_Heckschloss_ansteuern_Cx2_Ansteuerung_in_Richtung_auf), 3=Cx3_Ansteuerung_in_Richtung_zu (CM_ZV_Anf_Heckschloss_ansteuern_Cx3_Ansteuerung_in_Richtung_zu)}, range raw 0..3, transfer-property=PENDING  # Freigabe und Anforderung der Ansteuerung des Heckschlosses Das Signal muss über eine E2E-Absicherung verfügen.
          signal ZV_auto_Ansteuerung_XIX_CentralLocking_01_XIX_E3V_K2CANFD: start 23, 1 bit, little-endian, data-type-policy=OVERRIDE, i-signal-type=PRIMITIVE, init-value=0, base-type=BT_ZV_auto_Ansteuerung, compu {0=Cx0_Kein_Autolock_Unlock (CM_ZV_auto_Ansteuerung_Cx0_Kein_Autolock_Unlock), 1=Cx1_Autolock_Unlock (CM_ZV_auto_Ansteuerung_Cx1_Autolock_Unlock)}, range raw 0..1, transfer-property=PENDING  # Kennung für die automatische Ansteuerung der Zentralverriegelung (Autolock/Autounlock)
          signal ZV_Bedienstelle_auf_XIX_CentralLocking_01_XIX_E3V_K2CANFD: start 24, 4 bit, little-endian, data-type-policy=OVERRIDE, i-signal-type=PRIMITIVE, init-value=0, base-type=BT_ZV_Bedienstelle_auf, compu {0=Cx0_keine_ZV_Bedienstelle_in_Richtung_auf_betaetigt (CM_ZV_Bedienstelle_auf_Cx0_keine_ZV_Bedienstelle_in_Richtung_auf_betaetigt) (keine ZV Bedienstelle in Richtung auf betaetigt), 1=Cx1_Bedienstelle_FT_betaetigt (CM_ZV_Bedienstelle_auf_Cx1_Bedienstelle_FT_betaetigt) (Bedienstelle FT betaetigt), 2=Cx2_Bedienstelle_Kessy_erkannt (CM_ZV_Bedienstelle_auf_Cx2_Bedienstelle_Kessy_erkannt) (Bedienstelle Kessy erkannt), 3=Cx3_Bedienstelle_Funk_betaetigt (CM_ZV_Bedienstelle_auf_Cx3_Bedienstelle_Funk_betaetigt) (Bedienstelle Funk betaetigt), 4=Cx4_Bedienstelle_NFC_erkannt (CM_ZV_Bedienstelle_auf_Cx4_Bedienstelle_NFC_erkannt) (Bedienstelle NFC erkannt), 5=Cx5_Bedienstelle_Mobile_Device_Key_erkannt (CM_ZV_Bedienstelle_auf_Cx5_Bedienstelle_Mobile_Device_Key_erkannt) (Bedienstelle Mobile Device Key erkannt), 6=Cx6_Bedienstelle_Notentriegelung_Transponder_erkannt (CM_ZV_Bedienstelle_auf_Cx6_Bedienstelle_Notentriegelung_Transponder_erkannt) (Bedienstelle Notentriegelung Transponder erkannt), 7=Cx7_Bedienstelle_Remote_Unlock_erkannt (CM_ZV_Bedienstelle_auf_Cx7_Bedienstelle_Remote_Unlock_erkannt) (Bedienstelle Remote Unlock erkannt), 8=Cx8_Bedienstelle_Emergency_Assist_erkannt (CM_ZV_Bedienstelle_auf_Cx8_Bedienstelle_Emergency_Assist_erkannt) (Bedienstelle Emergency Assist erkannt), 9=Cx9_Bedienstelle_VIP_erkannt (CM_ZV_Bedienstelle_auf_Cx9_Bedienstelle_VIP_erkannt) (Bedienstelle VIP erkannt)}, range raw 0..9, transfer-property=PENDING, to SAM(timeout 2 s)  # ZV Schliessstellen in Richtung auf
          signal ZV_Bedienstelle_zu_XIX_CentralLocking_01_XIX_E3V_K2CANFD: start 28, 4 bit, little-endian, data-type-policy=OVERRIDE, i-signal-type=PRIMITIVE, init-value=0, base-type=BT_ZV_Bedienstelle_zu, compu {0=Cx0_keine_ZV_Bedienstelle_in_Richtung_zu_betaetigt (CM_ZV_Bedienstelle_zu_Cx0_keine_ZV_Bedienstelle_in_Richtung_zu_betaetigt) (keine ZV Bedienstelle in Richtung zu betaetigt), 1=Cx1_Bedienstelle_FT_betaetigt (CM_ZV_Bedienstelle_zu_Cx1_Bedienstelle_FT_betaetigt) (Bedienstelle FT betaetigt), 2=Cx2_Bedienstelle_Kessy_erkannt (CM_ZV_Bedienstelle_zu_Cx2_Bedienstelle_Kessy_erkannt) (Bedienstelle Kessy erkannt), 3=Cx3_Bedienstelle_Funk_betaetigt (CM_ZV_Bedienstelle_zu_Cx3_Bedienstelle_Funk_betaetigt) (Bedienstelle Funk betaetigt), 4=Cx4_Bedienstelle_NFC_erkannt (CM_ZV_Bedienstelle_zu_Cx4_Bedienstelle_NFC_erkannt) (Bedienstelle NFC erkannt), 5=Cx5_Bedienstelle_Mobile_Device_Key_erkannt (CM_ZV_Bedienstelle_zu_Cx5_Bedienstelle_Mobile_Device_Key_erkannt) (Bedienstelle Mobile Device Key erkannt), 6=Cx6_Bedienstelle_Notverriegelung_Transponder_erkannt (CM_ZV_Bedienstelle_zu_Cx6_Bedienstelle_Notverriegelung_Transponder_erkannt) (Bedienstelle Notverriegelung Transponder erkannt), 7=Cx7_Bedienstelle_Remote_Lock_erkannt (CM_ZV_Bedienstelle_zu_Cx7_Bedienstelle_Remote_Lock_erkannt) (Bedienstelle Remote Lock erkannt), 8=Cx8_Bedienstelle_Precrash_erkannt (CM_ZV_Bedienstelle_zu_Cx8_Bedienstelle_Precrash_erkannt) (Bedienstelle Precrash erkannt), 9=Cx9_Bedienstelle_VIP_erkannt (CM_ZV_Bedienstelle_zu_Cx9_Bedienstelle_VIP_erkannt) (Bedienstelle VIP erkannt), 10=Cxa_Bedienstelle_ECL_erkannt (CM_ZV_Bedienstelle_zu_Cxa_Bedienstelle_ECL_erkannt) (Bedienstelle ECL erkannt), 11=Cxb_Bedienstelle_PiloPa_erkannt (CM_ZV_Bedienstelle_zu_Cxb_Bedienstelle_PiloPa_erkannt) (Bedienstelle PiloPa erkannt)}, range raw 0..11, transfer-property=PENDING  # ZV Schliessstellen in Richtung zu
          signal ZV_BT_entriegeln_XIX_CentralLocking_01_XIX_E3V_K2CANFD: start 32, 1 bit, little-endian, data-type-policy=OVERRIDE, i-signal-type=PRIMITIVE, init-value=0, base-type=BT_ZV_BT_entriegeln, compu {0=Cx0_BT_nicht_entriegeln (CM_ZV_BT_entriegeln_Cx0_BT_nicht_entriegeln), 1=Cx1_BT_ist_zu_entriegeln (CM_ZV_BT_entriegeln_Cx1_BT_ist_zu_entriegeln)}, range raw 0..1, transfer-property=PENDING  # Beifahrertür entriegeln (Anforderung ZV)
          signal ZV_BT_offen_XIX_CentralLocking_01_XIX_E3V_K2CANFD: start 33, 1 bit, little-endian, data-type-policy=OVERRIDE, i-signal-type=PRIMITIVE, init-value=0, base-type=BT_ZV_BT_offen, compu {0=Cx0_BT_geschlossen (CM_ZV_BT_offen_Cx0_BT_geschlossen), 1=Cx1_BT_geoeffnet (CM_ZV_BT_offen_Cx1_BT_geoeffnet)}, range raw 0..1, transfer-property=PENDING  # gespiegeltes Bit BT_Tuer_geoeffnet TSG_BT_1 Botschaft
          signal ZV_BT_verriegeln_XIX_CentralLocking_01_XIX_E3V_K2CANFD: start 34, 1 bit, little-endian, data-type-policy=OVERRIDE, i-signal-type=PRIMITIVE, init-value=0, base-type=BT_ZV_BT_verriegeln, compu {0=Cx0_BT_nicht_verriegeln (CM_ZV_BT_verriegeln_Cx0_BT_nicht_verriegeln), 1=Cx1_BT_verriegeln (CM_ZV_BT_verriegeln_Cx1_BT_verriegeln)}, range raw 0..1, transfer-property=PENDING  # Verriegelungsanforderung ZV für BT
          signal ZV_Txt_Handbremse_Hinweis_XIX_CentralLocking_01_XIX_E3V_K2CANFD: start 36, 1 bit, little-endian, data-type-policy=OVERRIDE, i-signal-type=PRIMITIVE, init-value=0, base-type=BT_ZV_Txt_Handbremse_Hinweis, compu {0=Cx0_inaktiv (CM_ZV_Txt_Handbremse_Hinweis_Cx0_inaktiv), 1=Cx1_aktiv (CM_ZV_Txt_Handbremse_Hinweis_Cx1_aktiv)}, range raw 0..1, transfer-property=PENDING  # Infotext NAR für die Vorbedingung "Handbremse" für Öffnen des Frontdeckesl oder des Heckdeckels / der Heckklappe über die Fahrerrauminnentaster.
          signal ZV_Frontdeckel_offen_XIX_CentralLocking_01_XIX_E3V_K2CANFD: start 37, 1 bit, little-endian, data-type-policy=OVERRIDE, i-signal-type=PRIMITIVE, init-value=0, base-type=BT_ZV_Frontdeckel_offen, compu {0=Cx0_Frontdeckel_zu (CM_ZV_Frontdeckel_offen_Cx0_Frontdeckel_zu), 1=Cx1_Frontdeckel_auf (CM_ZV_Frontdeckel_offen_Cx1_Frontdeckel_auf)}, range raw 0..1, transfer-property=PENDING  # Status Frontdeckel
          signal ZV_Frontschloss_Hauptraste_XIX_CentralLocking_01_XIX_E3V_K2CANFD: start 38, 2 bit, little-endian, data-type-policy=OVERRIDE, i-signal-type=PRIMITIVE, init-value=0, base-type=BT_ZV_Frontschloss_Hauptraste, invalid-value=Invalid_ZV_Frontschloss_Hauptraste_XIX_CentralLocking_01_XIX_E3V_K2CANFD:3, compu {0=Cx0_geschlossen (CM_ZV_Frontschloss_Hauptraste_Cx0_geschlossen), 1=Cx1_offen (CM_ZV_Frontschloss_Hauptraste_Cx1_offen), 2=Cx2_Init_oder_nicht_verbaut (CM_ZV_Frontschloss_Hauptraste_Cx2_Init_oder_nicht_verbaut), 3=Cx3_Fehler (CM_ZV_Frontschloss_Hauptraste_Cx3_Fehler)}, range raw 0..3, transfer-property=PENDING  # Drehfalle oder Hauptraste Frontchloss Das Signal muss über eine E2E-Absicherung verfügen.
          signal ZV_Frontschloss_Sperrklinke_XIX_CentralLocking_01_XIX_E3V_K2CANFD: start 40, 2 bit, little-endian, data-type-policy=OVERRIDE, i-signal-type=PRIMITIVE, init-value=0, base-type=BT_ZV_Frontschloss_Sperrklinke, invalid-value=Invalid_ZV_Frontschloss_Sperrklinke_XIX_CentralLocking_01_XIX_E3V_K2CANFD:3, compu {0=Cx0_Init_oder_nicht_verbaut (CM_ZV_Frontschloss_Sperrklinke_Cx0_Init_oder_nicht_verbaut), 1=Cx1_Sperrklinke_gekoppelt (CM_ZV_Frontschloss_Sperrklinke_Cx1_Sperrklinke_gekoppelt), 2=Cx2_Sperrklinke_entkoppelt (CM_ZV_Frontschloss_Sperrklinke_Cx2_Sperrklinke_entkoppelt), 3=Cx3_Fehler (CM_ZV_Frontschloss_Sperrklinke_Cx3_Fehler)}, range raw 0..3, transfer-property=PENDING  # Status Sperrklinke Frontchloss Das Signal muss über eine E2E-Absicherung verfügen.
          signal ZV_Frontschloss_Taste_XIX_CentralLocking_01_XIX_E3V_K2CANFD: start 42, 1 bit, little-endian, data-type-policy=OVERRIDE, i-signal-type=PRIMITIVE, init-value=0, base-type=BT_ZV_Frontschloss_Taste, compu {0=Cx0_Taste_nicht_betaetigt (CM_ZV_Frontschloss_Taste_Cx0_Taste_nicht_betaetigt), 1=Cx1_Taste_entprellt_betaetigt (CM_ZV_Frontschloss_Taste_Cx1_Taste_entprellt_betaetigt)}, range raw 0..1, transfer-property=PENDING  # Betätigung Taster für Frontdeckel im Innenraum (Schweller)
          signal ZV_Frontschlossstatus_XIX_CentralLocking_01_XIX_E3V_K2CANFD: start 43, 2 bit, little-endian, data-type-policy=OVERRIDE, i-signal-type=PRIMITIVE, init-value=2, base-type=BT_ZV_Frontschlossstatus, invalid-value=Invalid_ZV_Frontschlossstatus_XIX_CentralLocking_01_XIX_E3V_K2CANFD:3, compu {0=Cx0_geschlossen (CM_ZV_Frontschlossstatus_Cx0_geschlossen), 1=Cx1_offen (CM_ZV_Frontschlossstatus_Cx1_offen), 2=Cx2_Init_oder_nicht_verbaut (CM_ZV_Frontschlossstatus_Cx2_Init_oder_nicht_verbaut), 3=Cx3_Fehler (CM_ZV_Frontschlossstatus_Cx3_Fehler)}, range raw 0..3, transfer-property=PENDING  # Rückmeldung Status Frontschloss
          signal ZV_FT_entriegeln_XIX_CentralLocking_01_XIX_E3V_K2CANFD: start 45, 1 bit, little-endian, data-type-policy=OVERRIDE, i-signal-type=PRIMITIVE, init-value=0, base-type=BT_ZV_FT_entriegeln, compu {0=Cx0_FT_nicht_entriegeln (CM_ZV_FT_entriegeln_Cx0_FT_nicht_entriegeln), 1=Cx1_FT_entriegeln (CM_ZV_FT_entriegeln_Cx1_FT_entriegeln)}, range raw 0..1, transfer-property=PENDING  # Entriegelungsanforderung ZV für FT
          signal ZV_FT_offen_XIX_CentralLocking_01_XIX_E3V_K2CANFD: start 46, 1 bit, little-endian, data-type-policy=OVERRIDE, i-signal-type=PRIMITIVE, init-value=0, base-type=BT_ZV_FT_offen, compu {0=Cx0_FT_geschlossen (CM_ZV_FT_offen_Cx0_FT_geschlossen), 1=Cx1_FT_geoeffnet (CM_ZV_FT_offen_Cx1_FT_geoeffnet)}, range raw 0..1, transfer-property=PENDING  # gespiegeltes Bit FT_Tuer_geoeffnet TSG_FT_1 Botschaft
          signal ZV_FT_verriegeln_XIX_CentralLocking_01_XIX_E3V_K2CANFD: start 47, 1 bit, little-endian, data-type-policy=OVERRIDE, i-signal-type=PRIMITIVE, init-value=0, base-type=BT_ZV_FT_verriegeln, compu {0=Cx0_FT_nicht_verriegeln (CM_ZV_FT_verriegeln_Cx0_FT_nicht_verriegeln), 1=Cx1_FT_verriegeln (CM_ZV_FT_verriegeln_Cx1_FT_verriegeln)}, range raw 0..1, transfer-property=PENDING  # Verriegelungsanforderung ZV für FT
          signal ZV_HBFS_entriegeln_XIX_CentralLocking_01_XIX_E3V_K2CANFD: start 48, 1 bit, little-endian, data-type-policy=OVERRIDE, i-signal-type=PRIMITIVE, init-value=0, base-type=BT_ZV_HBFS_entriegeln, compu {0=Cx0_inaktiv (CM_ZV_HBFS_entriegeln_Cx0_inaktiv), 1=Cx1_aktiv (CM_ZV_HBFS_entriegeln_Cx1_aktiv)}, range raw 0..1, transfer-property=PENDING  # Entriegelungsanforderung ZV für HBFS
          signal ZV_HBFS_offen_XIX_CentralLocking_01_XIX_E3V_K2CANFD: start 49, 1 bit, little-endian, data-type-policy=OVERRIDE, i-signal-type=PRIMITIVE, init-value=0, base-type=BT_ZV_HBFS_offen, compu {0=Cx0_geschlossen (CM_ZV_HBFS_offen_Cx0_geschlossen), 1=Cx1_offen (CM_ZV_HBFS_offen_Cx1_offen)}, range raw 0..1, transfer-property=PENDING  # gespiegeltes Bit HBFS_Tuer_geoeffnet TSG_HBFS_1 Botschaft
          signal ZV_HBFS_verriegeln_XIX_CentralLocking_01_XIX_E3V_K2CANFD: start 50, 1 bit, little-endian, data-type-policy=OVERRIDE, i-signal-type=PRIMITIVE, init-value=0, base-type=BT_ZV_HBFS_verriegeln, compu {0=Cx0_inaktiv (CM_ZV_HBFS_verriegeln_Cx0_inaktiv), 1=Cx1_aktiv (CM_ZV_HBFS_verriegeln_Cx1_aktiv)}, range raw 0..1, transfer-property=PENDING  # Verriegelungsanforderung ZV für HBFS
          signal ZV_HFS_entriegeln_XIX_CentralLocking_01_XIX_E3V_K2CANFD: start 51, 1 bit, little-endian, data-type-policy=OVERRIDE, i-signal-type=PRIMITIVE, init-value=0, base-type=BT_ZV_HFS_entriegeln, compu {0=Cx0_inaktiv (CM_ZV_HFS_entriegeln_Cx0_inaktiv), 1=Cx1_aktiv (CM_ZV_HFS_entriegeln_Cx1_aktiv)}, range raw 0..1, transfer-property=PENDING  # Entriegelungsanforderung ZV für HFS
          signal ZV_HFS_offen_XIX_CentralLocking_01_XIX_E3V_K2CANFD: start 52, 1 bit, little-endian, data-type-policy=OVERRIDE, i-signal-type=PRIMITIVE, init-value=0, base-type=BT_ZV_HFS_offen, compu {0=Cx0_geschlossen (CM_ZV_HFS_offen_Cx0_geschlossen), 1=Cx1_offen (CM_ZV_HFS_offen_Cx1_offen)}, range raw 0..1, transfer-property=PENDING  # gespiegeltes Bit HFS_Tuer_geoeffnet TSG_HFS_1 Botschaft
          signal ZV_HFS_verriegeln_XIX_CentralLocking_01_XIX_E3V_K2CANFD: start 53, 1 bit, little-endian, data-type-policy=OVERRIDE, i-signal-type=PRIMITIVE, init-value=0, base-type=BT_ZV_HFS_verriegeln, compu {0=Cx0_inaktiv (CM_ZV_HFS_verriegeln_Cx0_inaktiv), 1=Cx1_aktiv (CM_ZV_HFS_verriegeln_Cx1_aktiv)}, range raw 0..1, transfer-property=PENDING  # Verriegelungsanforderung ZV für HFS
          signal ZV_HD_Taste_zu_XIX_CentralLocking_01_XIX_E3V_K2CANFD: start 54, 1 bit, little-endian, data-type-policy=OVERRIDE, i-signal-type=PRIMITIVE, init-value=0, base-type=BT_ZV_HD_Taste_zu, compu {0=Cx0_Taste_HD_zu_nicht_gedrueckt (CM_ZV_HD_Taste_zu_Cx0_Taste_HD_zu_nicht_gedrueckt), 1=Cx1_Taste_HD_zu_gedrueckt (CM_ZV_HD_Taste_zu_Cx1_Taste_HD_zu_gedrueckt)}, range raw 0..1, transfer-property=PENDING  # Taster zum Schliessen der Heckklappe über BAP
          signal ZV_Heckentriegelunsanforderung_XIX_CentralLocking_01_XIX_E3V_K2CANFD: start 55, 1 bit, little-endian, data-type-policy=OVERRIDE, i-signal-type=PRIMITIVE, init-value=0, base-type=BT_ZV_Heckentriegelunsanforderung, compu {0=Cx0_Taste_Heckschloss_auf_nicht_gedrueckt (CM_ZV_Heckentriegelunsanforderung_Cx0_Taste_Heckschloss_auf_nicht_gedrueckt), 1=Cx1_Taste_Heckschloss_auf_gedrueckt (CM_ZV_Heckentriegelunsanforderung_Cx1_Taste_Heckschloss_auf_gedrueckt)}, range raw 0..1, transfer-property=PENDING  # Taster zum Öffnen der Heckklappe über BAP oder einem diskret angeschlossen Schalter
          signal ZV_Heckoeffnungsfreigabe_XIX_CentralLocking_01_XIX_E3V_K2CANFD: start 56, 1 bit, little-endian, data-type-policy=OVERRIDE, i-signal-type=PRIMITIVE, init-value=0, base-type=BT_ZV_Heckoeffnungsfreigabe, compu {0=Cx0_keine_Freigabe (CM_ZV_Heckoeffnungsfreigabe_Cx0_keine_Freigabe) (keine Freigabe), 1=Cx1_Heckoeffnungsfreigabe (CM_ZV_Heckoeffnungsfreigabe_Cx1_Heckoeffnungsfreigabe) (Hecköffnungsfreigabe)}, range raw 0..1, transfer-property=PENDING  # Heckeinzelentriegelung oder Heckschlosseinzelentriegelung
          signal ZV_HSK_Freigabe_XIX_CentralLocking_01_XIX_E3V_K2CANFD: start 57, 1 bit, little-endian, data-type-policy=OVERRIDE, i-signal-type=PRIMITIVE, init-value=0, base-type=BT_ZV_HSK_Freigabe, compu {0=Cx0_erlauben (CM_ZV_HSK_Freigabe_Cx0_erlauben), 1=Cx1_sperren (CM_ZV_HSK_Freigabe_Cx1_sperren)}, range raw 0..1, transfer-property=PENDING  # Handschuhkastenfreigabe
          signal ZV_LED_Steuerung_XIX_CentralLocking_01_XIX_E3V_K2CANFD: start 58, 1 bit, little-endian, data-type-policy=OVERRIDE, i-signal-type=PRIMITIVE, init-value=0, base-type=BT_ZV_LED_Steuerung, compu {0=Cx0_LED_aus (CM_ZV_LED_Steuerung_Cx0_LED_aus), 1=Cx1_LED_ein (CM_ZV_LED_Steuerung_Cx1_LED_ein)}, range raw 0..1, transfer-property=PENDING  # Ansteuerung der LED's in den Tueren; BAF gilt nicht für dieses Bit
          signal ZV_LED_Uebernahme_XIX_CentralLocking_01_XIX_E3V_K2CANFD: start 59, 1 bit, little-endian, data-type-policy=OVERRIDE, i-signal-type=PRIMITIVE, init-value=0, base-type=BT_ZV_LED_Uebernahme, compu {0=Cx0_Init (CM_ZV_LED_Uebernahme_Cx0_Init), 1=Cx1_TSG_uebernimmt_LED_Steuerung (CM_ZV_LED_Uebernahme_Cx1_TSG_uebernimmt_LED_Steuerung)}, range raw 0..1, transfer-property=PENDING  # Uebernahme der LED Steuerung durch das TSG FT
          signal ZV_gesafet_extern_ist_02_XIX_CentralLocking_01_XIX_E3V_K2CANFD: start 60, 2 bit, little-endian, data-type-policy=OVERRIDE, i-signal-type=PRIMITIVE, init-value=0, base-type=BT_ZV_gesafet_extern_ist_02, invalid-value=Invalid_ZV_gesafet_extern_ist_02_XIX_CentralLocking_01_XIX_E3V_K2CANFD:3, compu {0=Cx0_Fahrzeug_nicht_gesafet (CM_ZV_gesafet_extern_ist_02_Cx0_Fahrzeug_nicht_gesafet), 1=Cx1_Fahrzeug_gesafet_Istzustand (CM_ZV_gesafet_extern_ist_02_Cx1_Fahrzeug_gesafet_Istzustand), 2=Cx2_Init (CM_ZV_gesafet_extern_ist_02_Cx2_Init), 3=Cx3_Fehler (CM_ZV_gesafet_extern_ist_02_Cx3_Fehler)}, range raw 0..3, transfer-property=PENDING  # Istzustand: Fahrzeug aussen gesafet
          signal ZV_SafeFunktion_aktiv_XIX_CentralLocking_01_XIX_E3V_K2CANFD: start 62, 1 bit, little-endian, data-type-policy=OVERRIDE, i-signal-type=PRIMITIVE, init-value=0, base-type=BT_ZV_SafeFunktion_aktiv, compu {0=Cx0_inaktiv (CM_ZV_SafeFunktion_aktiv_Cx0_inaktiv), 1=Cx1_aktiv (CM_ZV_SafeFunktion_aktiv_Cx1_aktiv)}, range raw 0..1, transfer-property=PENDING  # Statusübermittlung ob die Safe Funktion im Fzg. aktiv ist. Das Kombi benötigt das Signal, um den Text Safelock aktiv anzuzeigen.
          signal ZV_Schluessel_Zugang_XIX_CentralLocking_01_XIX_E3V_K2CANFD: start 63, 4 bit, little-endian, data-type-policy=OVERRIDE, i-signal-type=PRIMITIVE, init-value=0, base-type=BT_ZV_Schluessel_Zugang, compu {0=Cx0_kein_auth_Schluessel_erkannt (CM_ZV_Schluessel_Zugang_Cx0_kein_auth_Schluessel_erkannt), 1=Cx1_aktive_Funkschluessel_Nr_01 (CM_ZV_Schluessel_Zugang_Cx1_aktive_Funkschluessel_Nr_01), 2=Cx2_aktive_Funkschluessel_Nr_02 (CM_ZV_Schluessel_Zugang_Cx2_aktive_Funkschluessel_Nr_02), 3=Cx3_aktive_Funkschluessel_Nr_03 (CM_ZV_Schluessel_Zugang_Cx3_aktive_Funkschluessel_Nr_03), 4=Cx4_aktive_Funkschluessel_Nr_04 (CM_ZV_Schluessel_Zugang_Cx4_aktive_Funkschluessel_Nr_04), 5=Cx5_aktive_Funkschluessel_Nr_05 (CM_ZV_Schluessel_Zugang_Cx5_aktive_Funkschluessel_Nr_05), 6=Cx6_aktive_Funkschluessel_Nr_06 (CM_ZV_Schluessel_Zugang_Cx6_aktive_Funkschluessel_Nr_06), 7=Cx7_aktive_Funkschluessel_Nr_07 (CM_ZV_Schluessel_Zugang_Cx7_aktive_Funkschluessel_Nr_07), 8=Cx8_aktive_Funkschluessel_Nr_08 (CM_ZV_Schluessel_Zugang_Cx8_aktive_Funkschluessel_Nr_08), 9=Cx9_aktive_SmartDevice_Nr_09 (CM_ZV_Schluessel_Zugang_Cx9_aktive_SmartDevice_Nr_09), 10=Cxa_ungueltig_10 (CM_ZV_Schluessel_Zugang_Cxa_ungueltig_10), 11=Cxb_ungueltig_11 (CM_ZV_Schluessel_Zugang_Cxb_ungueltig_11), 12=Cxc_ungueltig_12 (CM_ZV_Schluessel_Zugang_Cxc_ungueltig_12), 13=Cxd_ungueltig_13 (CM_ZV_Schluessel_Zugang_Cxd_ungueltig_13), 14=Cxe_ungueltig_14 (CM_ZV_Schluessel_Zugang_Cxe_ungueltig_14), 15=Cxf_ungueltig_15 (CM_ZV_Schluessel_Zugang_Cxf_ungueltig_15)}, range raw 0..15, transfer-property=PENDING  # aktuelle Funkschlüsselnummer
          signal ZV_Signatur_XIX_CentralLocking_01_XIX_E3V_K2CANFD: start 67, 11 bit, little-endian, data-type-policy=OVERRIDE, i-signal-type=PRIMITIVE, init-value=0, base-type=BT_ZV_Signatur, compu {phys=raw for raw 0..2047}, range phys 0..2047, raw 0..2047, transfer-property=PENDING  # Signatur der ZV
          signal ZV_Spg_Anklappen_XIX_CentralLocking_01_XIX_E3V_K2CANFD: start 78, 1 bit, little-endian, data-type-policy=OVERRIDE, i-signal-type=PRIMITIVE, init-value=0, base-type=BT_ZV_Spg_Anklappen, compu {0=Cx0_inaktiv (CM_ZV_Spg_Anklappen_Cx0_inaktiv), 1=Cx1_aktiv (CM_ZV_Spg_Anklappen_Cx1_aktiv)}, range raw 0..1, transfer-property=PENDING  # Anforderung über ZV: Spiegel sind anzuklappen
          signal APP_Kundenwarnung_Panik_XIX_CentralLocking_01_XIX_E3V_K2CANFD: start 79, 1 bit, little-endian, data-type-policy=OVERRIDE, i-signal-type=PRIMITIVE, init-value=1, base-type=BT_APP_Kundenwarnung_Panik, compu {0=Cx0_Nicht_aktiv (CM_APP_Kundenwarnung_Panik_Cx0_Nicht_aktiv), 1=Cx1_Aktiv (CM_APP_Kundenwarnung_Panik_Cx1_Aktiv)}, range raw 0..1, transfer-property=PENDING  # Kundenwarnung Panik signal
          signal ZV_APP_Kundenwarnung_Notein_XIX_CentralLocking_01_XIX_E3V_K2CANFD: start 80, 1 bit, little-endian, data-type-policy=OVERRIDE, i-signal-type=PRIMITIVE, init-value=0, base-type=BT_ZV_APP_Kundenwarnung_Notein, compu {0=Cx0_Nicht_aktiv (CM_ZV_APP_Kundenwarnung_Notein_Cx0_Nicht_aktiv) (Nicht aktiv), 1=Cx1_Aktiv (CM_ZV_APP_Kundenwarnung_Notein_Cx1_Aktiv)}, range raw 0..1, transfer-property=PENDING  # Information an den Kunden dass eine Noteinspeisung erkannt wurde, um in der APP die Handlungsanweisung anzuzeigen.
          signal ZV_ValetTaster_Fkts_LED_XIX_CentralLocking_01_XIX_E3V_K2CANFD: start 82, 1 bit, little-endian, data-type-policy=OVERRIDE, i-signal-type=PRIMITIVE, init-value=0, base-type=BT_ZV_ValetTaster_Fkts_LED, compu {0=Cx0_LED_aus (CM_ZV_ValetTaster_Fkts_LED_Cx0_LED_aus), 1=Cx1_LED_ein (CM_ZV_ValetTaster_Fkts_LED_Cx1_LED_ein)}, range raw 0..1, transfer-property=PENDING  # Im MQB beschreibt das Signal nur den Zustand der Funktion Valet Parking (aktiv/ inaktiv) Im MLBevo wird über das Signal zusätzlich die ValetTaster_Fkts_LED (an/ aus) gesteuert
          signal ZV_verriegelt_extern_soll_03_XIX_CentralLocking_01_XIX_E3V_K2CANFD: start 83, 2 bit, little-endian, data-type-policy=OVERRIDE, i-signal-type=PRIMITIVE, init-value=0, base-type=BT_ZV_verriegelt_extern_soll_03, invalid-value=Invalid_ZV_verriegelt_extern_soll_03_XIX_CentralLocking_01_XIX_E3V_K2CANFD:3, compu {0=Cx0_Fahrzeug_nicht_extern_verriegelt (CM_ZV_verriegelt_extern_soll_03_Cx0_Fahrzeug_nicht_extern_verriegelt), 1=Cx1_Fahrzeug_extern_verriegelt_Sollz (CM_ZV_verriegelt_extern_soll_03_Cx1_Fahrzeug_extern_verriegelt_Sollz), 2=Cx2_Init (CM_ZV_verriegelt_extern_soll_03_Cx2_Init), 3=Cx3_Fehler (CM_ZV_verriegelt_extern_soll_03_Cx3_Fehler)}, range raw 0..3, transfer-property=PENDING  # Sollzustand: Verriegelung Fahrzeug aussen
          signal ZV_Anf_Auffindbel_TE_hinten_XIX_CentralLocking_01_XIX_E3V_K2CANFD: start 85, 1 bit, little-endian, data-type-policy=OVERRIDE, i-signal-type=PRIMITIVE, init-value=0, base-type=BT_ZV_Anf_Auffindbel_TE_hinten, compu {0=Cx0_nicht_angefordert (CM_ZV_Anf_Auffindbel_TE_hinten_Cx0_nicht_angefordert), 1=Cx1_angefordert (CM_ZV_Anf_Auffindbel_TE_hinten_Cx1_angefordert)}, range raw 0..1, transfer-property=PENDING  # Anforderung der Trunk Entrapment Auffindbeleuchtung im Bedientaster TE hinten Das Signal muss über eine E2E-Absicherung verfügen.
          signal ZV_zentral_entsafen_XIX_CentralLocking_01_XIX_E3V_K2CANFD: start 86, 1 bit, little-endian, data-type-policy=OVERRIDE, i-signal-type=PRIMITIVE, init-value=0, base-type=BT_ZV_zentral_entsafen, compu {0=Cx0_Init (CM_ZV_zentral_entsafen_Cx0_Init), 1=Cx1_Befehl_zentral_entsafen (CM_ZV_zentral_entsafen_Cx1_Befehl_zentral_entsafen)}, range raw 0..1, transfer-property=PENDING  # Zentral entsafen
          signal ZV_zentral_safen_XIX_CentralLocking_01_XIX_E3V_K2CANFD: start 87, 1 bit, little-endian, data-type-policy=OVERRIDE, i-signal-type=PRIMITIVE, init-value=0, base-type=BT_ZV_zentral_safen, compu {0=Cx0_nicht_safen (CM_ZV_zentral_safen_Cx0_nicht_safen), 1=Cx1_Befehl_zentral_safen (CM_ZV_zentral_safen_Cx1_Befehl_zentral_safen)}, range raw 0..1, transfer-property=PENDING  # Zentral safen
          signal ZV_Anf_Auffindbel_TE_vorne_XIX_CentralLocking_01_XIX_E3V_K2CANFD: start 89, 1 bit, little-endian, data-type-policy=OVERRIDE, i-signal-type=PRIMITIVE, init-value=0, base-type=BT_ZV_Anf_Auffindbel_TE_vorne, compu {0=Cx0_nicht_angefordert (CM_ZV_Anf_Auffindbel_TE_vorne_Cx0_nicht_angefordert), 1=Cx1_angefordert (CM_ZV_Anf_Auffindbel_TE_vorne_Cx1_angefordert)}, range raw 0..1, transfer-property=PENDING  # Anforderung der Trunk Entrapment Auffindbeleuchtung im Bedientaster TE vorne Das Signal muss über eine E2E-Absicherung verfügen.
          signal ZV_zu_Zeitl_Nachverr_XIX_CentralLocking_01_XIX_E3V_K2CANFD: start 90, 1 bit, little-endian, data-type-policy=OVERRIDE, i-signal-type=PRIMITIVE, init-value=0, base-type=BT_ZV_zu_Zeitl_Nachverr, compu {0=Cx0_Init (CM_ZV_zu_Zeitl_Nachverr_Cx0_Init), 1=Cx1_Nachverriegeln (CM_ZV_zu_Zeitl_Nachverr_Cx1_Nachverriegeln)}, range raw 0..1, transfer-property=PENDING  # ZV Schliessstelle
          signal ZV_TAG_BT_verfahren_XIX_CentralLocking_01_XIX_E3V_K2CANFD: start 91, 2 bit, little-endian, data-type-policy=OVERRIDE, i-signal-type=PRIMITIVE, init-value=0, base-type=BT_ZV_TAG_BT_verfahren, compu {0=Cx0_Init (CM_ZV_TAG_BT_verfahren_Cx0_Init), 1=Cx1_TAG_ausfahren (CM_ZV_TAG_BT_verfahren_Cx1_TAG_ausfahren), 2=Cx2_TAG_einfahren (CM_ZV_TAG_BT_verfahren_Cx2_TAG_einfahren)}, range raw 0..2, transfer-property=PENDING  # Türaussengriff BT Trigger zum Aus- und Einfahren
          signal ZV_TAG_HBFS_verfahren_XIX_CentralLocking_01_XIX_E3V_K2CANFD: start 93, 2 bit, little-endian, data-type-policy=OVERRIDE, i-signal-type=PRIMITIVE, init-value=0, base-type=BT_ZV_TAG_HBFS_verfahren, compu {0=Cx0_Init (CM_ZV_TAG_HBFS_verfahren_Cx0_Init), 1=Cx1_TAG_ausfahren (CM_ZV_TAG_HBFS_verfahren_Cx1_TAG_ausfahren), 2=Cx2_TAG_einfahren (CM_ZV_TAG_HBFS_verfahren_Cx2_TAG_einfahren)}, range raw 0..2, transfer-property=PENDING  # Türaussengriff HBFS Trigger zum Aus- und Einfahren
          signal ZV_TAG_FT_verfahren_XIX_CentralLocking_01_XIX_E3V_K2CANFD: start 95, 2 bit, little-endian, data-type-policy=OVERRIDE, i-signal-type=PRIMITIVE, init-value=0, base-type=BT_ZV_TAG_FT_verfahren, invalid-value=Invalid_ZV_TAG_FT_verfahren_XIX_CentralLocking_01_XIX_E3V_K2CANFD:3, compu {0=Cx0_Init (CM_ZV_TAG_FT_verfahren_Cx0_Init), 1=Cx1_TAG_ausfahren (CM_ZV_TAG_FT_verfahren_Cx1_TAG_ausfahren), 2=Cx2_TAG_einfahren (CM_ZV_TAG_FT_verfahren_Cx2_TAG_einfahren), 3=Cx3_Fehler (CM_ZV_TAG_FT_verfahren_Cx3_Fehler)}, range raw 0..3, transfer-property=PENDING  # Türaussengriff FT Trigger zum Aus- und Einfahren
          signal ZV_TAG_HFS_verfahren_XIX_CentralLocking_01_XIX_E3V_K2CANFD: start 97, 2 bit, little-endian, data-type-policy=OVERRIDE, i-signal-type=PRIMITIVE, init-value=0, base-type=BT_ZV_TAG_HFS_verfahren, compu {0=Cx0_Init (CM_ZV_TAG_HFS_verfahren_Cx0_Init), 1=Cx1_TAG_ausfahren (CM_ZV_TAG_HFS_verfahren_Cx1_TAG_ausfahren), 2=Cx2_TAG_einfahren (CM_ZV_TAG_HFS_verfahren_Cx2_TAG_einfahren)}, range raw 0..2, transfer-property=PENDING  # Türaussengriff HFS Trigger zum Aus- und Einfahren
          signal IRUE_Taster_Fkts_LED_XIX_CentralLocking_01_XIX_E3V_K2CANFD: start 99, 1 bit, little-endian, data-type-policy=OVERRIDE, i-signal-type=PRIMITIVE, init-value=0, base-type=BT_IRUE_Taster_Fkts_LED, compu {0=Cx0_LED_aus (CM_IRUE_Taster_Fkts_LED_Cx0_LED_aus), 1=Cx1_LED_ein (CM_IRUE_Taster_Fkts_LED_Cx1_LED_ein)}, range raw 0..1, transfer-property=PENDING  # Anforderung Funktions-LED IRUE-Taster (LED wird vom TSG angesteuert) MQB: Bei Verbau eines einzelnen Taster zur Deaktivierung von IRUE und NGS wird dieses Signal zur Ansteuerung der Funktions-LED gesendet.
          signal SSA_Heckschloss_ansteuern_XIX_CentralLocking_01_XIX_E3V_K2CANFD: start 100, 2 bit, little-endian, data-type-policy=OVERRIDE, i-signal-type=PRIMITIVE, init-value=0, base-type=BT_SSA_Heckschloss_ansteuern, compu {0=Cx0_nicht_angefordert (CM_SSA_Heckschloss_ansteuern_Cx0_nicht_angefordert) (nicht angefordert), 1=Cx1_Entriegeln (CM_SSA_Heckschloss_ansteuern_Cx1_Entriegeln), 2=Cx2_Verriegeln (CM_SSA_Heckschloss_ansteuern_Cx2_Verriegeln)}, range raw 0..2, transfer-property=PENDING  # SmartSensorActor: Anforderung zum Ent-/Verriegeln des Heckschlosses
          signal SSA_Tankklappe_ansteuern_XIX_CentralLocking_01_XIX_E3V_K2CANFD: start 102, 2 bit, little-endian, data-type-policy=OVERRIDE, i-signal-type=PRIMITIVE, init-value=0, base-type=BT_SSA_Tankklappe_ansteuern, compu {0=Cx0_nicht_angefordert (CM_SSA_Tankklappe_ansteuern_Cx0_nicht_angefordert) (nicht angefordert), 1=Cx1_Entriegeln (CM_SSA_Tankklappe_ansteuern_Cx1_Entriegeln), 2=Cx2_Verriegeln (CM_SSA_Tankklappe_ansteuern_Cx2_Verriegeln)}, range raw 0..2, transfer-property=PENDING  # SmartSensorActor: Anforderung zum Ent-/Verriegeln der Tankklappe
          signal ZV_auf_Funk_XIX_CentralLocking_01_XIX_E3V_K2CANFD: start 104, 1 bit, little-endian, data-type-policy=OVERRIDE, i-signal-type=PRIMITIVE, init-value=0, base-type=BT_ZV_auf_Funk, compu {0=Cx0_nicht_betaetigt (CM_ZV_auf_Funk_Cx0_nicht_betaetigt), 1=Cx1_betaetigt (CM_ZV_auf_Funk_Cx1_betaetigt)}, range raw 0..1, transfer-property=PENDING  # ZV Schliessstelle
          signal DWA_aktiv_XIX_CentralLocking_01_XIX_E3V_K2CANFD: start 105, 1 bit, little-endian, data-type-policy=OVERRIDE, i-signal-type=PRIMITIVE, init-value=0, base-type=BT_DWA_aktiv, compu {0=Cx0_unscharf (CM_DWA_aktiv_Cx0_unscharf), 1=Cx1_scharf (CM_DWA_aktiv_Cx1_scharf)}, range raw 0..1, transfer-property=PENDING  # Status DWA aktiv
          signal DWA_Alarmquelle_02_XIX_CentralLocking_01_XIX_E3V_K2CANFD: start 106, 5 bit, little-endian, data-type-policy=OVERRIDE, i-signal-type=PRIMITIVE, init-value=30, base-type=BT_DWA_Alarmquelle_02, invalid-value=Invalid_DWA_Alarmquelle_02_XIX_CentralLocking_01_XIX_E3V_K2CANFD:31, compu {0=Cx0_kein_Ausloesegrund (CM_DWA_Alarmquelle_02_Cx0_kein_Ausloesegrund), 1=Cx1_Tuerkontakt_FT (CM_DWA_Alarmquelle_02_Cx1_Tuerkontakt_FT), 2=Cx2_Tuerkontakt_BT (CM_DWA_Alarmquelle_02_Cx2_Tuerkontakt_BT), 3=Cx3_Tuerkontakt_HFS (CM_DWA_Alarmquelle_02_Cx3_Tuerkontakt_HFS), 4=Cx4_Tuerkontakt_HBFS (CM_DWA_Alarmquelle_02_Cx4_Tuerkontakt_HBFS), 5=Cx5_Frontdeckelkontakt (CM_DWA_Alarmquelle_02_Cx5_Frontdeckelkontakt), 6=Cx6_Heckdeckel_klappenkontakt (CM_DWA_Alarmquelle_02_Cx6_Heckdeckel_klappenkontakt) (Heckdeckel-/klappenkontakt), 7=Cx7_Heckscheibenbruch (CM_DWA_Alarmquelle_02_Cx7_Heckscheibenbruch), 8=Cx8_Innenraumueberwachung (CM_DWA_Alarmquelle_02_Cx8_Innenraumueberwachung), 9=Cx9_Alarm_durch_Noteinstieg (CM_DWA_Alarmquelle_02_Cx9_Alarm_durch_Noteinstieg), 10=Cxa_Backuphorn (CM_DWA_Alarmquelle_02_Cxa_Backuphorn), 11=Cxb_Neigungssensor (CM_DWA_Alarmquelle_02_Cxb_Neigungssensor), 12=Cxc_FT_keine_Kommunikation (CM_DWA_Alarmquelle_02_Cxc_FT_keine_Kommunikation), 13=Cxd_BT_keine_Kommunikation (CM_DWA_Alarmquelle_02_Cxd_BT_keine_Kommunikation), 14=Cxe_HFS_keine_Kommunikation (CM_DWA_Alarmquelle_02_Cxe_HFS_keine_Kommunikation), 15=Cxf_HBFS_keine_Kommunikation (CM_DWA_Alarmquelle_02_Cxf_HBFS_keine_Kommunikation), 16=Cx10_Klemme_15 (CM_DWA_Alarmquelle_02_Cx10_Klemme_15), 17=Cx11_Klemme_15sig (CM_DWA_Alarmquelle_02_Cx11_Klemme_15sig), 18=Cx12_frei (CM_DWA_Alarmquelle_02_Cx12_frei), 19=Cx13_Anhaengerueberwachung (CM_DWA_Alarmquelle_02_Cx13_Anhaengerueberwachung), 20=Cx14_Scheinwerferueberwachung_links (CM_DWA_Alarmquelle_02_Cx14_Scheinwerferueberwachung_links), 21=Cx15_Scheinwerferueberwachung_rechts (CM_DWA_Alarmquelle_02_Cx15_Scheinwerferueberwachung_rechts), 22=Cx16_Handschuhkasten (CM_DWA_Alarmquelle_02_Cx16_Handschuhkasten), 23=Cx17_Verdeckueberwachung (CM_DWA_Alarmquelle_02_Cx17_Verdeckueberwachung), 24=Cx18_OBD_Alarm (CM_DWA_Alarmquelle_02_Cx18_OBD_Alarm), 25=Cx19_Power_on_Reset (CM_DWA_Alarmquelle_02_Cx19_Power_on_Reset), 26=Cx1a_Heckkontakt_keine_Kommunikation (CM_DWA_Alarmquelle_02_Cx1a_Heckkontakt_keine_Kommunikation), 30=Cx1e_Init (CM_DWA_Alarmquelle_02_Cx1e_Init), 31=Cx1f_Fehler (CM_DWA_Alarmquelle_02_Cx1f_Fehler)}, range raw 0..31, transfer-property=PENDING  # Signalisiert den Auslösegrund der DWA
          signal ZV_APP_Kundenwarnung_Funk_XIX_CentralLocking_01_XIX_E3V_K2CANFD: start 111, 1 bit, little-endian, data-type-policy=OVERRIDE, i-signal-type=PRIMITIVE, init-value=0, base-type=BT_ZV_APP_Kundenwarnung_Funk, compu {0=Cx0_Funkstorer_nicht_aktiv (CM_ZV_APP_Kundenwarnung_Funk_Cx0_Funkstorer_nicht_aktiv), 1=Cx1_Funkstorer_aktiv (CM_ZV_APP_Kundenwarnung_Funk_Cx1_Funkstorer_aktiv)}, range raw 0..1, transfer-property=PENDING  # Information an den Kunden dass ein Funkstoerer erkannt wurde, um in der APP die Handlungsanweisung anzuzeigen.
          signal ZV_verriegelt_intern_soll_02_XIX_CentralLocking_01_XIX_E3V_K2CANFD: start 112, 2 bit, little-endian, data-type-policy=OVERRIDE, i-signal-type=PRIMITIVE, init-value=0, base-type=BT_ZV_verriegelt_intern_soll_02, invalid-value=Invalid_ZV_verriegelt_intern_soll_02_XIX_CentralLocking_01_XIX_E3V_K2CANFD:3, compu {0=Cx0_Fahrzeug_nicht_innen_verriegelt (CM_ZV_verriegelt_intern_soll_02_Cx0_Fahrzeug_nicht_innen_verriegelt), 1=Cx1_Fahrzeug_innen_verriegelt_Sollzu (CM_ZV_verriegelt_intern_soll_02_Cx1_Fahrzeug_innen_verriegelt_Sollzu), 2=Cx2_Init (CM_ZV_verriegelt_intern_soll_02_Cx2_Init), 3=Cx3_Fehler (CM_ZV_verriegelt_intern_soll_02_Cx3_Fehler)}, range raw 0..3, transfer-property=PENDING  # Sollzustand: Verriegelung Fahrzeug innen
          signal ZV_Status_eTAG_ist_XIX_CentralLocking_01_XIX_E3V_K2CANFD: start 114, 2 bit, little-endian, data-type-policy=OVERRIDE, i-signal-type=PRIMITIVE, init-value=0, base-type=BT_ZV_Status_eTAG_ist, compu {0=Cx0_Init (CM_ZV_Status_eTAG_ist_Cx0_Init), 1=Cx1_Tueraussengriff_eingefahren_Istzustand (CM_ZV_Status_eTAG_ist_Cx1_Tueraussengriff_eingefahren_Istzustand) (Türaussengriff._eingefahren (Istzustand)), 2=Cx2_Tueraussengriff_ausgefahren_Istzustand (CM_ZV_Status_eTAG_ist_Cx2_Tueraussengriff_ausgefahren_Istzustand) (Türaussengriff._ausgefahren ( (Istzustand))}, range raw 0..2, transfer-property=PENDING  # Istzustand: Türaussengriff eingefahren oder ausgefahren (Zielzustand)
          signal ZV_Status_eTAG_soll_XIX_CentralLocking_01_XIX_E3V_K2CANFD: start 116, 2 bit, little-endian, data-type-policy=OVERRIDE, i-signal-type=PRIMITIVE, init-value=0, base-type=BT_ZV_Status_eTAG_soll, compu {0=Cx0_Init (CM_ZV_Status_eTAG_soll_Cx0_Init), 1=Cx1_Tueraussengriff_eingefahren_Sollzustand (CM_ZV_Status_eTAG_soll_Cx1_Tueraussengriff_eingefahren_Sollzustand) (Türaussengriff._eingefahren (Sollzustand)), 2=Cx2_Tueraussengriff_ausgefahren_Sollzustand (CM_ZV_Status_eTAG_soll_Cx2_Tueraussengriff_ausgefahren_Sollzustand) (Türaussengriff._ausgefahren (Sollzustand))}, range raw 0..2, transfer-property=PENDING  # Sollzustand: Türaussengriff eingefahren oder ausgefahren (Zielzustand)
          signal ZV_gesafet_extern_soll_02_XIX_CentralLocking_01_XIX_E3V_K2CANFD: start 123, 2 bit, little-endian, data-type-policy=OVERRIDE, i-signal-type=PRIMITIVE, init-value=0, base-type=BT_ZV_gesafet_extern_soll_02, invalid-value=Invalid_ZV_gesafet_extern_soll_02_XIX_CentralLocking_01_XIX_E3V_K2CANFD:3, compu {0=Cx0_Fahrzeug_nicht_gesafet (CM_ZV_gesafet_extern_soll_02_Cx0_Fahrzeug_nicht_gesafet), 1=Cx1_Fahrzeug_gesafet_Sollzustand (CM_ZV_gesafet_extern_soll_02_Cx1_Fahrzeug_gesafet_Sollzustand), 2=Cx2_Init (CM_ZV_gesafet_extern_soll_02_Cx2_Init), 3=Cx3_Fehler (CM_ZV_gesafet_extern_soll_02_Cx3_Fehler)}, range raw 0..3, transfer-property=PENDING  # Sollzustand: Fahrzeug gesafet extern
          signal ZV_verriegelt_intern_ist_02_XIX_CentralLocking_01_XIX_E3V_K2CANFD: start 125, 2 bit, little-endian, data-type-policy=OVERRIDE, i-signal-type=PRIMITIVE, init-value=0, base-type=BT_ZV_verriegelt_intern_ist_02, invalid-value=Invalid_ZV_verriegelt_intern_ist_02_XIX_CentralLocking_01_XIX_E3V_K2CANFD:3, compu {0=Cx0_Fahrzeug_nicht_innen_verriegelt (CM_ZV_verriegelt_intern_ist_02_Cx0_Fahrzeug_nicht_innen_verriegelt), 1=Cx1_Fahrzeug_innen_verriegelt_Istzus (CM_ZV_verriegelt_intern_ist_02_Cx1_Fahrzeug_innen_verriegelt_Istzus), 2=Cx2_Init (CM_ZV_verriegelt_intern_ist_02_Cx2_Init), 3=Cx3_Fehler (CM_ZV_verriegelt_intern_ist_02_Cx3_Fehler)}, range raw 0..3, transfer-property=PENDING  # Istzustand: Verriegelung Fahrzeug innen
          signal ZV_TxT_TE_Warnung_vorne_XIX_CentralLocking_01_XIX_E3V_K2CANFD: start 127, 4 bit, little-endian, data-type-policy=OVERRIDE, i-signal-type=PRIMITIVE, init-value=0, base-type=BT_ZV_TxT_TE_Warnung_vorne, invalid-value=Invalid_ZV_TxT_TE_Warnung_vorne_XIX_CentralLocking_01_XIX_E3V_K2CANFD:15, compu {0=Cx0_Warnung_TE_vorne_Aus (CM_ZV_TxT_TE_Warnung_vorne_Cx0_Warnung_TE_vorne_Aus), 1=Cx1_Warn_TE_vorne_Bet_im_Stand_erk (CM_ZV_TxT_TE_Warnung_vorne_Cx1_Warn_TE_vorne_Bet_im_Stand_erk), 2=Cx2_Warn_TE_vorne_Bet_im_Fahrt_erk (CM_ZV_TxT_TE_Warnung_vorne_Cx2_Warn_TE_vorne_Bet_im_Fahrt_erk), 3=Cx3_Warn_TE_vorne_Systemfehler (CM_ZV_TxT_TE_Warnung_vorne_Cx3_Warn_TE_vorne_Systemfehler), 13=Cxd_Init (CM_ZV_TxT_TE_Warnung_vorne_Cxd_Init), 14=Cxe_Warn_nicht_vorhanden_verbaut (CM_ZV_TxT_TE_Warnung_vorne_Cxe_Warn_nicht_vorhanden_verbaut), 15=Cxf_Fehler (CM_ZV_TxT_TE_Warnung_vorne_Cxf_Fehler)}, range raw 0..15, transfer-property=PENDING  # Das Signal triggert eine Warnmeldung im Kombi zur Anzeige von diagnostizierten schleichenden Fehlern an den Aktoren oder Sensoren von TrunkEntrapment Frontdeckel Das Signal muss über eine E2E-Absicherung verfügen.
          signal ZV_Frontdeckelzustand_XIX_CentralLocking_01_XIX_E3V_K2CANFD: start 131, 3 bit, little-endian, data-type-policy=OVERRIDE, i-signal-type=PRIMITIVE, init-value=0, base-type=BT_ZV_Frontdeckelzustand, invalid-value=Invalid_ZV_Frontdeckelzustand_XIX_CentralLocking_01_XIX_E3V_K2CANFD:5, compu {0=Cx0_Init_oder_nicht_verbaut (CM_ZV_Frontdeckelzustand_Cx0_Init_oder_nicht_verbaut), 1=Cx1_Frontdeckel_vollverriegelt_gesichert (CM_ZV_Frontdeckelzustand_Cx1_Frontdeckel_vollverriegelt_gesichert), 2=Cx2_Frontde_ausgeworfen_gesichert (CM_ZV_Frontdeckelzustand_Cx2_Frontde_ausgeworfen_gesichert), 3=Cx3_Frontde_ausgeworden_ungesichert (CM_ZV_Frontdeckelzustand_Cx3_Frontde_ausgeworden_ungesichert), 4=Cx4_Frontdeckel_vollgeoeffnet (CM_ZV_Frontdeckelzustand_Cx4_Frontdeckel_vollgeoeffnet), 5=Cx5_Fehler (CM_ZV_Frontdeckelzustand_Cx5_Fehler)}, range raw 0..5, transfer-property=PENDING  # Der Frontdeckelsystemstatus wird mittels der Endlagenkontakte (Hauptraste, Auflagenerkennung und Fanghaken) ermittelt und in ASIL Guete ausgegeben.
          signal ZV_Heckschlossstatus_XIX_CentralLocking_01_XIX_E3V_K2CANFD: start 134, 2 bit, little-endian, data-type-policy=OVERRIDE, i-signal-type=PRIMITIVE, init-value=2, base-type=BT_ZV_Heckschlossstatus, invalid-value=Invalid_ZV_Heckschlossstatus_XIX_CentralLocking_01_XIX_E3V_K2CANFD:3, compu {0=Cx0_geschlossen (CM_ZV_Heckschlossstatus_Cx0_geschlossen), 1=Cx1_offen (CM_ZV_Heckschlossstatus_Cx1_offen), 2=Cx2_Init_oder_nicht_verbaut (CM_ZV_Heckschlossstatus_Cx2_Init_oder_nicht_verbaut), 3=Cx3_Fehler (CM_ZV_Heckschlossstatus_Cx3_Fehler)}, range raw 0..3, transfer-property=PENDING  # Rückmeldung Status Heckschloss
          signal ZV_TxT_Frontschloss_Warnung_XIX_CentralLocking_01_XIX_E3V_K2CANFD: start 136, 4 bit, little-endian, data-type-policy=OVERRIDE, i-signal-type=PRIMITIVE, init-value=13, base-type=BT_ZV_TxT_Frontschloss_Warnung, invalid-value=Invalid_ZV_TxT_Frontschloss_Warnung_XIX_CentralLocking_01_XIX_E3V_K2CANFD:15, compu {0=Cx0_Anzeige_Frontschloss_Warnung_Aus (CM_ZV_TxT_Frontschloss_Warnung_Cx0_Anzeige_Frontschloss_Warnung_Aus), 1=Cx1_Warn_Frontschloss_offen_im_Stand (CM_ZV_TxT_Frontschloss_Warnung_Cx1_Warn_Frontschloss_offen_im_Stand), 2=Cx2_Warn_Frontschloss_offen_bei_Fahrt (CM_ZV_TxT_Frontschloss_Warnung_Cx2_Warn_Frontschloss_offen_bei_Fahrt), 3=Cx3_Warn_Frontschloss_unplausibel (CM_ZV_TxT_Frontschloss_Warnung_Cx3_Warn_Frontschloss_unplausibel), 13=Cxd_Init (CM_ZV_TxT_Frontschloss_Warnung_Cxd_Init), 14=Cxe_Warnung_nicht_vorhanden_verbaut (CM_ZV_TxT_Frontschloss_Warnung_Cxe_Warnung_nicht_vorhanden_verbaut), 15=Cxf_Fehler (CM_ZV_TxT_Frontschloss_Warnung_Cxf_Fehler)}, range raw 0..15, transfer-property=PENDING  # Abhaengig vom Betriebszustand des Fahrzeuges fuehren die Frotdeckelsystemzustaende zu eine Bewarnung an den Kunden, um Gefahrsituationen zu vermeiden.
          signal ZV_TxT_Heckschloss_Warnung_XIX_CentralLocking_01_XIX_E3V_K2CANFD: start 140, 4 bit, little-endian, data-type-policy=OVERRIDE, i-signal-type=PRIMITIVE, init-value=13, base-type=BT_ZV_TxT_Heckschloss_Warnung, invalid-value=Invalid_ZV_TxT_Heckschloss_Warnung_XIX_CentralLocking_01_XIX_E3V_K2CANFD:15, compu {0=Cx0_Anzeige_Heckschloss_Warnung_Aus (CM_ZV_TxT_Heckschloss_Warnung_Cx0_Anzeige_Heckschloss_Warnung_Aus), 1=Cx1_Warn_Heck_offen_im_Stand (CM_ZV_TxT_Heckschloss_Warnung_Cx1_Warn_Heck_offen_im_Stand), 2=Cx2_Warn_Heckschloss_offen_bei_Fahrt (CM_ZV_TxT_Heckschloss_Warnung_Cx2_Warn_Heckschloss_offen_bei_Fahrt), 3=Cx3_Warn_Heckschloss_unplausibel (CM_ZV_TxT_Heckschloss_Warnung_Cx3_Warn_Heckschloss_unplausibel), 13=Cxd_Init (CM_ZV_TxT_Heckschloss_Warnung_Cxd_Init), 14=Cxe_Warnung_nicht_vorhanden_verbaut (CM_ZV_TxT_Heckschloss_Warnung_Cxe_Warnung_nicht_vorhanden_verbaut), 15=Cxf_Fehler (CM_ZV_TxT_Heckschloss_Warnung_Cxf_Fehler)}, range raw 0..15, transfer-property=PENDING  # Abhaengig vom Betriebszustand des Fahrzeuges fuehren die Heckschlosszustaende zu eine Bewarnung an den Kunden, um Gefahrsituationen zu vermeiden.
          signal ZV_Txt_Waehlhebel_P_Hinweis_XIX_CentralLocking_01_XIX_E3V_K2CANFD: start 144, 1 bit, little-endian, data-type-policy=OVERRIDE, i-signal-type=PRIMITIVE, init-value=0, base-type=BT_ZV_Txt_Waehlhebel_P_Hinweis, compu {0=Cx0_inaktiv (CM_ZV_Txt_Waehlhebel_P_Hinweis_Cx0_inaktiv), 1=Cx1_aktiv (CM_ZV_Txt_Waehlhebel_P_Hinweis_Cx1_aktiv)}, range raw 0..1, transfer-property=PENDING  # Infotext NAR für die Vorbedingung "Waehlhebel in P" für Öffnen des Frontdeckesl oder des Heckdeckels / der Heckklappe über die Fahrerrauminnentaster.
          signal ZV_Tasten_HMI_Anf_XIX_CentralLocking_01_XIX_E3V_K2CANFD: start 145, 1 bit, little-endian, data-type-policy=OVERRIDE, i-signal-type=PRIMITIVE, init-value=0, base-type=BT_ZV_Tasten_HMI_Anf, compu {0=Cx0_ZV_Tasten_im_HMI_nicht_anzeigen (CM_ZV_Tasten_HMI_Anf_Cx0_ZV_Tasten_im_HMI_nicht_anzeigen), 1=Cx1_ZV_Tasten_im_HMI_anzeigen (CM_ZV_Tasten_HMI_Anf_Cx1_ZV_Tasten_im_HMI_anzeigen)}, range raw 0..1, transfer-property=PENDING  # Trigger zum Einschalten des Touchbediendisplays und Anzeigen der ZV Tasten
          signal ZV_Frontschloss_Vorraste_XIX_CentralLocking_01_XIX_E3V_K2CANFD: start 146, 2 bit, little-endian, data-type-policy=OVERRIDE, i-signal-type=PRIMITIVE, init-value=2, base-type=BT_ZV_Frontschloss_Vorraste, invalid-value=Invalid_ZV_Frontschloss_Vorraste_XIX_CentralLocking_01_XIX_E3V_K2CANFD:3, compu {0=Cx0_geschlossen (CM_ZV_Frontschloss_Vorraste_Cx0_geschlossen), 1=Cx1_offen (CM_ZV_Frontschloss_Vorraste_Cx1_offen), 2=Cx2_Init_oder_nicht_verbaut (CM_ZV_Frontschloss_Vorraste_Cx2_Init_oder_nicht_verbaut), 3=Cx3_Fehler (CM_ZV_Frontschloss_Vorraste_Cx3_Fehler)}, range raw 0..3, transfer-property=PENDING  # Sperrklinke oder Vorraste Frontchloss Das Signal muss über eine E2E-Absicherung verfügen.
          signal ZV_Heckschlosszustand_XIX_CentralLocking_01_XIX_E3V_K2CANFD: start 152, 3 bit, little-endian, data-type-policy=OVERRIDE, i-signal-type=PRIMITIVE, init-value=0, base-type=BT_ZV_Heckschlosszustand, invalid-value=Invalid_ZV_Heckschlosszustand_XIX_CentralLocking_01_XIX_E3V_K2CANFD:5, compu {0=Cx0_Init_oder_nicht_verbaut (CM_ZV_Heckschlosszustand_Cx0_Init_oder_nicht_verbaut), 1=Cx1_Schloss_vollverriegelt_gesichert (CM_ZV_Heckschlosszustand_Cx1_Schloss_vollverriegelt_gesichert), 2=Cx2_Schloss_ausgeworfen_gesichert (CM_ZV_Heckschlosszustand_Cx2_Schloss_ausgeworfen_gesichert), 3=Cx3_Schloss_ausgeworfen_ungesichert (CM_ZV_Heckschlosszustand_Cx3_Schloss_ausgeworfen_ungesichert), 4=Cx4_Schloss_vollgeoeffnet (CM_ZV_Heckschlosszustand_Cx4_Schloss_vollgeoeffnet), 5=Cx5_Fehler (CM_ZV_Heckschlosszustand_Cx5_Fehler)}, range raw 0..5, transfer-property=PENDING  # Der Heckschlosssystemstatus wird mittels der Endlagenkontakte (Hauptraste und Vorraste) ermittelt und in ASIL Guete ausgegeben.
          signal ZV_TxT_TE_Warnung_hinten_XIX_CentralLocking_01_XIX_E3V_K2CANFD: start 156, 4 bit, little-endian, data-type-policy=OVERRIDE, i-signal-type=PRIMITIVE, init-value=0, base-type=BT_ZV_TxT_TE_Warnung_hinten, invalid-value=Invalid_ZV_TxT_TE_Warnung_hinten_XIX_CentralLocking_01_XIX_E3V_K2CANFD:15, compu {0=Cx0_Warn_TE_hinten_Aus (CM_ZV_TxT_TE_Warnung_hinten_Cx0_Warn_TE_hinten_Aus), 1=Cx1_Warn_TE_hinten_Bet_im_Stand_erk (CM_ZV_TxT_TE_Warnung_hinten_Cx1_Warn_TE_hinten_Bet_im_Stand_erk), 2=Cx2_Warn_TE_hinten_Bet_im_Fahrt_erk (CM_ZV_TxT_TE_Warnung_hinten_Cx2_Warn_TE_hinten_Bet_im_Fahrt_erk), 3=Cx3_Warn_TE_hinten_Systemfehler (CM_ZV_TxT_TE_Warnung_hinten_Cx3_Warn_TE_hinten_Systemfehler), 13=Cxd_Init (CM_ZV_TxT_TE_Warnung_hinten_Cxd_Init), 14=Cxe_Warnung_nicht_vorhanden_verbaut (CM_ZV_TxT_TE_Warnung_hinten_Cxe_Warnung_nicht_vorhanden_verbaut), 15=Cxf_Fehler (CM_ZV_TxT_TE_Warnung_hinten_Cxf_Fehler)}, range raw 0..15, transfer-property=PENDING  # Das Signal triggert eine Warnmeldung im Kombi zur Anzeige von diagnostizierten schleichenden Fehlern an den Aktoren oder Sensoren von TrunkEntrapment Heckdeckel/-klappe
      frame Charisma_03_XIX_E3V_K2CANFD: id 0x386, to SAM, frame-length=8, can-addressing-mode=STANDARD, can-frame-rx-behavior=CAN-FD, can-frame-tx-behavior=CAN-FD
        pdu Charisma_03_XIX_E3V_K2CANFD: length=8, minimum-delay=0.05, transmission-mode-true-timing={cyclic-timing={time-offset=0.0, time-period=1.0}, event-controlled-timing={number-of-repetitions=0, repetition-period=0.0}}, unused-bit-pattern=0  # ab MQB 7.2.1
          signal CHA_Charisma_Taste2_LED_XIX_Charisma_03_XIX_E3V_K2CANFD: start 0, 2 bit, little-endian, data-type-policy=OVERRIDE, i-signal-type=PRIMITIVE, init-value=0, base-type=BT_CHA_Charisma_Taste2_LED, invalid-value=Invalid_CHA_Charisma_Taste2_LED_XIX_Charisma_03_XIX_E3V_K2CANFD:3, compu {0=Cx0_LED_aus (CM_CHA_Charisma_Taste2_LED_Cx0_LED_aus), 1=Cx1_LED_ein (CM_CHA_Charisma_Taste2_LED_Cx1_LED_ein), 2=Cx2_LED_blinken (CM_CHA_Charisma_Taste2_LED_Cx2_LED_blinken), 3=Cx3_Fehler (CM_CHA_Charisma_Taste2_LED_Cx3_Fehler)}, range raw 0..3, transfer-property=TRIGGERED-ON-CHANGE-WITHOUT-REPETITION  # Ansteuerung der 2. Charisma-Taste-LED
          signal CHA_ReqPrgDispSetup_XIX_Charisma_03_XIX_E3V_K2CANFD: start 2, 4 bit, little-endian, data-type-policy=OVERRIDE, i-signal-type=PRIMITIVE, init-value=0, base-type=BT_CHA_ReqPrgDispSetup, compu {0=Cx0_init (CM_CHA_ReqPrgDispSetup_Cx0_init), 1=Cx1_layout_comfort (CM_CHA_ReqPrgDispSetup_Cx1_layout_comfort), 2=Cx2_layout_eco (CM_CHA_ReqPrgDispSetup_Cx2_layout_eco), 3=Cx3_layout_sport (CM_CHA_ReqPrgDispSetup_Cx3_layout_sport), 4=Cx4_layout_offroad (CM_CHA_ReqPrgDispSetup_Cx4_layout_offroad), 5=Cx5_layout_sportplus (CM_CHA_ReqPrgDispSetup_Cx5_layout_sportplus), 6=Cx6_program_6 (CM_CHA_ReqPrgDispSetup_Cx6_program_6), 7=Cx7_program_7 (CM_CHA_ReqPrgDispSetup_Cx7_program_7), 8=Cx8_program_8 (CM_CHA_ReqPrgDispSetup_Cx8_program_8), 9=Cx9_program_9 (CM_CHA_ReqPrgDispSetup_Cx9_program_9), 10=Cxa_program_10 (CM_CHA_ReqPrgDispSetup_Cxa_program_10), 11=Cxb_program_11 (CM_CHA_ReqPrgDispSetup_Cxb_program_11), 12=Cxc_program_12 (CM_CHA_ReqPrgDispSetup_Cxc_program_12), 13=Cxd_program_13 (CM_CHA_ReqPrgDispSetup_Cxd_program_13), 14=Cxe_program_14 (CM_CHA_ReqPrgDispSetup_Cxe_program_14), 15=Cxf_program_15 (CM_CHA_ReqPrgDispSetup_Cxf_program_15)}, range raw 0..15, transfer-property=TRIGGERED-ON-CHANGE-WITHOUT-REPETITION  # Requested Charisma-programm to Kombi to change display setup.
          signal CHA_Current_Mode_FPA_XIX_Charisma_03_XIX_E3V_K2CANFD: start 6, 6 bit, little-endian, data-type-policy=OVERRIDE, i-signal-type=PRIMITIVE, init-value=0, base-type=BT_CHA_Current_Mode_FPA, compu {0=Cx0_keine_Funktion (CM_CHA_Current_Mode_FPA_Cx0_keine_Funktion), 1=Cx1_Programm_1 (CM_CHA_Current_Mode_FPA_Cx1_Programm_1), 2=Cx2_Programm_2 (CM_CHA_Current_Mode_FPA_Cx2_Programm_2), 3=Cx3_Programm_3 (CM_CHA_Current_Mode_FPA_Cx3_Programm_3), 4=Cx4_Programm_4 (CM_CHA_Current_Mode_FPA_Cx4_Programm_4), 5=Cx5_Programm_5 (CM_CHA_Current_Mode_FPA_Cx5_Programm_5), 6=Cx6_Programm_6 (CM_CHA_Current_Mode_FPA_Cx6_Programm_6), 7=Cx7_Programm_7 (CM_CHA_Current_Mode_FPA_Cx7_Programm_7), 8=Cx8_Programm_8 (CM_CHA_Current_Mode_FPA_Cx8_Programm_8), 9=Cx9_Programm_9 (CM_CHA_Current_Mode_FPA_Cx9_Programm_9), 10=Cxa_Programm_10 (CM_CHA_Current_Mode_FPA_Cxa_Programm_10), 11=Cxb_Programm_11 (CM_CHA_Current_Mode_FPA_Cxb_Programm_11), 12=Cxc_Programm_12 (CM_CHA_Current_Mode_FPA_Cxc_Programm_12), 13=Cxd_Programm_13 (CM_CHA_Current_Mode_FPA_Cxd_Programm_13), 14=Cxe_Programm_14 (CM_CHA_Current_Mode_FPA_Cxe_Programm_14), 15=Cxf_Programm_15 (CM_CHA_Current_Mode_FPA_Cxf_Programm_15), 16=Cx10_Programm_16 (CM_CHA_Current_Mode_FPA_Cx10_Programm_16), 17=Cx11_Programm_17 (CM_CHA_Current_Mode_FPA_Cx11_Programm_17), 18=Cx12_Programm_18 (CM_CHA_Current_Mode_FPA_Cx12_Programm_18), 19=Cx13_Programm_19 (CM_CHA_Current_Mode_FPA_Cx13_Programm_19), 20=Cx14_Programm_20 (CM_CHA_Current_Mode_FPA_Cx14_Programm_20), 21=Cx15_Programm_21 (CM_CHA_Current_Mode_FPA_Cx15_Programm_21), 22=Cx16_Programm_22 (CM_CHA_Current_Mode_FPA_Cx16_Programm_22), 23=Cx17_Programm_23 (CM_CHA_Current_Mode_FPA_Cx17_Programm_23), 24=Cx18_Programm_24 (CM_CHA_Current_Mode_FPA_Cx18_Programm_24), 25=Cx19_Programm_25 (CM_CHA_Current_Mode_FPA_Cx19_Programm_25), 26=Cx1a_Programm_26 (CM_CHA_Current_Mode_FPA_Cx1a_Programm_26), 27=Cx1b_Programm_27 (CM_CHA_Current_Mode_FPA_Cx1b_Programm_27), 28=Cx1c_Programm_28 (CM_CHA_Current_Mode_FPA_Cx1c_Programm_28), 29=Cx1d_Programm_29 (CM_CHA_Current_Mode_FPA_Cx1d_Programm_29), 30=Cx1e_Programm_30 (CM_CHA_Current_Mode_FPA_Cx1e_Programm_30), 31=Cx1f_Programm_31 (CM_CHA_Current_Mode_FPA_Cx1f_Programm_31), 32=Cx20_Programm_32 (CM_CHA_Current_Mode_FPA_Cx20_Programm_32)}, range raw 0..32, transfer-property=TRIGGERED-ON-CHANGE-WITHOUT-REPETITION  # Aktuell eingestelltes Charisma Fahrprogramm
          signal CHA_Eco_Charisma_LED_XIX_Charisma_03_XIX_E3V_K2CANFD: start 12, 2 bit, little-endian, data-type-policy=OVERRIDE, i-signal-type=PRIMITIVE, init-value=0, base-type=BT_CHA_Eco_Charisma_LED, compu {0=Cx0_LED_aus_und_Blinken_aus (CM_CHA_Eco_Charisma_LED_Cx0_LED_aus_und_Blinken_aus), 1=Cx1_LED_ein_und_Blinken_aus (CM_CHA_Eco_Charisma_LED_Cx1_LED_ein_und_Blinken_aus), 2=Cx2_LED_ein_und_Blinken_ein_50_percent (CM_CHA_Eco_Charisma_LED_Cx2_LED_ein_und_Blinken_ein_50_percent), 3=Cx3_reserviert (CM_CHA_Eco_Charisma_LED_Cx3_reserviert)}, range raw 0..3, transfer-property=TRIGGERED-ON-CHANGE-WITHOUT-REPETITION  # Ansteuerung der Funktions-LED der ECO alias Bluekey Taste bzw. Charisma-Taste. Der Master der Fahrmodus-Funktion soll die Funktionsleuchte ansteuern, in der MQB Architektur ist der Master im Gateway untergebracht.
          signal CHA_Fahrer_Umschaltung_XIX_Charisma_03_XIX_E3V_K2CANFD: start 14, 1 bit, little-endian, data-type-policy=OVERRIDE, i-signal-type=PRIMITIVE, init-value=0, base-type=BT_CHA_Fahrer_Umschaltung, compu {0=Cx0_keine_oder_automatische_Umschaltung (CM_CHA_Fahrer_Umschaltung_Cx0_keine_oder_automatische_Umschaltung), 1=Cx1_manuelle_Umschaltung (CM_CHA_Fahrer_Umschaltung_Cx1_manuelle_Umschaltung)}, range raw 0..1, transfer-property=TRIGGERED-ON-CHANGE-WITHOUT-REPETITION, to SAM(timeout 5 s)  # Die manuelle Umschaltung durch den Fahrer soll signalisiert werden, um zu automatischen Umschaltungen (z.B. Retries) differenzieren zu können.
          signal CHA_EV_LED_XIX_Charisma_03_XIX_E3V_K2CANFD: start 15, 1 bit, little-endian, data-type-policy=OVERRIDE, i-signal-type=PRIMITIVE, init-value=0, base-type=BT_CHA_EV_LED, compu {0=Cx0_LED_aus (CM_CHA_EV_LED_Cx0_LED_aus), 1=Cx1_LED_an (CM_CHA_EV_LED_Cx1_LED_an)}, range raw 0..1, transfer-property=TRIGGERED-ON-CHANGE-WITHOUT-REPETITION  # Ansteuerung der LED am EV-Taster durch Charisma im PHEV
          signal CHA_Ziel_FahrPr_AMB_XIX_Charisma_03_XIX_E3V_K2CANFD: start 16, 4 bit, little-endian, data-type-policy=OVERRIDE, i-signal-type=PRIMITIVE, init-value=0, base-type=BT_CHA_Ziel_FahrPr_AMB, compu {0=Cx0_keine_Funktion (CM_CHA_Ziel_FahrPr_AMB_Cx0_keine_Funktion), 1=Cx1_Programm_1 (CM_CHA_Ziel_FahrPr_AMB_Cx1_Programm_1), 2=Cx2_Programm_2 (CM_CHA_Ziel_FahrPr_AMB_Cx2_Programm_2), 3=Cx3_Programm_3 (CM_CHA_Ziel_FahrPr_AMB_Cx3_Programm_3), 4=Cx4_Programm_4 (CM_CHA_Ziel_FahrPr_AMB_Cx4_Programm_4), 5=Cx5_Programm_5 (CM_CHA_Ziel_FahrPr_AMB_Cx5_Programm_5), 6=Cx6_Programm_6 (CM_CHA_Ziel_FahrPr_AMB_Cx6_Programm_6), 7=Cx7_Programm_7 (CM_CHA_Ziel_FahrPr_AMB_Cx7_Programm_7), 8=Cx8_Programm_8 (CM_CHA_Ziel_FahrPr_AMB_Cx8_Programm_8), 9=Cx9_Programm_9 (CM_CHA_Ziel_FahrPr_AMB_Cx9_Programm_9), 10=Cxa_Programm_10 (CM_CHA_Ziel_FahrPr_AMB_Cxa_Programm_10), 11=Cxb_Programm_11 (CM_CHA_Ziel_FahrPr_AMB_Cxb_Programm_11), 12=Cxc_Programm_12 (CM_CHA_Ziel_FahrPr_AMB_Cxc_Programm_12), 13=Cxd_Programm_13 (CM_CHA_Ziel_FahrPr_AMB_Cxd_Programm_13), 14=Cxe_Programm_14 (CM_CHA_Ziel_FahrPr_AMB_Cxe_Programm_14), 15=Cxf_Programm_15 (CM_CHA_Ziel_FahrPr_AMB_Cxf_Programm_15)}, range raw 0..15, transfer-property=TRIGGERED-ON-CHANGE-WITHOUT-REPETITION, to SAM(timeout 5 s)  # Anforderung Ziel-Fahrprogramm Ambientelichtmodul
          signal CHA_Ziel_FahrPr_IVB_XIX_Charisma_03_XIX_E3V_K2CANFD: start 20, 4 bit, little-endian, data-type-policy=OVERRIDE, i-signal-type=PRIMITIVE, init-value=0, base-type=BT_CHA_Ziel_FahrPr_IVB, compu {0=Cx0_keine_Funktion (CM_CHA_Ziel_FahrPr_IVB_Cx0_keine_Funktion), 1=Cx1_Programm_1 (CM_CHA_Ziel_FahrPr_IVB_Cx1_Programm_1), 2=Cx2_Programm_2 (CM_CHA_Ziel_FahrPr_IVB_Cx2_Programm_2), 3=Cx3_Programm_3 (CM_CHA_Ziel_FahrPr_IVB_Cx3_Programm_3), 4=Cx4_Programm_4 (CM_CHA_Ziel_FahrPr_IVB_Cx4_Programm_4), 5=Cx5_Programm_5 (CM_CHA_Ziel_FahrPr_IVB_Cx5_Programm_5), 6=Cx6_Programm_6 (CM_CHA_Ziel_FahrPr_IVB_Cx6_Programm_6), 7=Cx7_Programm_7 (CM_CHA_Ziel_FahrPr_IVB_Cx7_Programm_7), 8=Cx8_Programm_8 (CM_CHA_Ziel_FahrPr_IVB_Cx8_Programm_8), 9=Cx9_Programm_9 (CM_CHA_Ziel_FahrPr_IVB_Cx9_Programm_9), 10=Cxa_Programm_10 (CM_CHA_Ziel_FahrPr_IVB_Cxa_Programm_10), 11=Cxb_Programm_11 (CM_CHA_Ziel_FahrPr_IVB_Cxb_Programm_11), 12=Cxc_Programm_12 (CM_CHA_Ziel_FahrPr_IVB_Cxc_Programm_12), 13=Cxd_Programm_13 (CM_CHA_Ziel_FahrPr_IVB_Cxd_Programm_13), 14=Cxe_Programm_14 (CM_CHA_Ziel_FahrPr_IVB_Cxe_Programm_14), 15=Cxf_Programm_15 (CM_CHA_Ziel_FahrPr_IVB_Cxf_Programm_15)}, range raw 0..15, transfer-property=TRIGGERED-ON-CHANGE-WITHOUT-REPETITION  # Anforderung Ziel-Fahrprogramm IVB
          signal CHA_Kombi_Texte_XIX_Charisma_03_XIX_E3V_K2CANFD: start 24, 4 bit, little-endian, data-type-policy=OVERRIDE, i-signal-type=PRIMITIVE, init-value=0, base-type=BT_CHA_Kombi_Texte, compu {0=Cx0_keine_Anzeige (CM_CHA_Kombi_Texte_Cx0_keine_Anzeige), 1=Cx1_Text_1 (CM_CHA_Kombi_Texte_Cx1_Text_1), 2=Cx2_Text_2 (CM_CHA_Kombi_Texte_Cx2_Text_2), 3=Cx3_Text_3 (CM_CHA_Kombi_Texte_Cx3_Text_3), 4=Cx4_Text_4 (CM_CHA_Kombi_Texte_Cx4_Text_4), 5=Cx5_Text_5 (CM_CHA_Kombi_Texte_Cx5_Text_5), 6=Cx6_Text_6 (CM_CHA_Kombi_Texte_Cx6_Text_6), 7=Cx7_Text_7 (CM_CHA_Kombi_Texte_Cx7_Text_7), 8=Cx8_Text_8 (CM_CHA_Kombi_Texte_Cx8_Text_8), 9=Cx9_Text_9 (CM_CHA_Kombi_Texte_Cx9_Text_9), 10=Cxa_Text_10 (CM_CHA_Kombi_Texte_Cxa_Text_10), 11=Cxb_Text_11 (CM_CHA_Kombi_Texte_Cxb_Text_11), 12=Cxc_Text_12 (CM_CHA_Kombi_Texte_Cxc_Text_12), 13=Cxd_Text_13 (CM_CHA_Kombi_Texte_Cxd_Text_13), 14=Cxe_Text_14 (CM_CHA_Kombi_Texte_Cxe_Text_14), 15=Cxf_Text_15 (CM_CHA_Kombi_Texte_Cxf_Text_15)}, range raw 0..15, transfer-property=TRIGGERED-ON-CHANGE-WITHOUT-REPETITION  # Anzeige des aktuellen Charisma-Fahrprofiles im Kombi. Die Texte werden HUT-Spezifisch in einem Schnittstellen-LAH definiert.
          signal CHA_Ziel_FahrPr_KL_XIX_Charisma_03_XIX_E3V_K2CANFD: start 28, 4 bit, little-endian, data-type-policy=OVERRIDE, i-signal-type=PRIMITIVE, init-value=0, base-type=BT_CHA_Ziel_FahrPr_KL, compu {0=Cx0_keine_Funktion (CM_CHA_Ziel_FahrPr_KL_Cx0_keine_Funktion), 1=Cx1_Programm_1 (CM_CHA_Ziel_FahrPr_KL_Cx1_Programm_1), 2=Cx2_Programm_2 (CM_CHA_Ziel_FahrPr_KL_Cx2_Programm_2), 3=Cx3_Programm_3 (CM_CHA_Ziel_FahrPr_KL_Cx3_Programm_3), 4=Cx4_Programm_4 (CM_CHA_Ziel_FahrPr_KL_Cx4_Programm_4), 5=Cx5_Programm_5 (CM_CHA_Ziel_FahrPr_KL_Cx5_Programm_5), 6=Cx6_Programm_6 (CM_CHA_Ziel_FahrPr_KL_Cx6_Programm_6), 7=Cx7_Programm_7 (CM_CHA_Ziel_FahrPr_KL_Cx7_Programm_7), 8=Cx8_Programm_8 (CM_CHA_Ziel_FahrPr_KL_Cx8_Programm_8), 9=Cx9_Programm_9 (CM_CHA_Ziel_FahrPr_KL_Cx9_Programm_9), 10=Cxa_Programm_10 (CM_CHA_Ziel_FahrPr_KL_Cxa_Programm_10), 11=Cxb_Programm_11 (CM_CHA_Ziel_FahrPr_KL_Cxb_Programm_11), 12=Cxc_Programm_12 (CM_CHA_Ziel_FahrPr_KL_Cxc_Programm_12), 13=Cxd_Programm_13 (CM_CHA_Ziel_FahrPr_KL_Cxd_Programm_13), 14=Cxe_Programm_14 (CM_CHA_Ziel_FahrPr_KL_Cxe_Programm_14), 15=Cxf_Programm_15 (CM_CHA_Ziel_FahrPr_KL_Cxf_Programm_15)}, range raw 0..15, transfer-property=TRIGGERED-ON-CHANGE-WITHOUT-REPETITION  # Anforderung Ziel-Fahrprogramm Klima
          signal CHA_Ziel_FahrPr_HSP_XIX_Charisma_03_XIX_E3V_K2CANFD: start 32, 4 bit, little-endian, data-type-policy=OVERRIDE, i-signal-type=PRIMITIVE, init-value=0, base-type=BT_CHA_Ziel_FahrPr_HSP, compu {0=Cx0_keine_Funktion (CM_CHA_Ziel_FahrPr_HSP_Cx0_keine_Funktion), 1=Cx1_Programm_1 (CM_CHA_Ziel_FahrPr_HSP_Cx1_Programm_1), 2=Cx2_Programm_2 (CM_CHA_Ziel_FahrPr_HSP_Cx2_Programm_2), 3=Cx3_Programm_3 (CM_CHA_Ziel_FahrPr_HSP_Cx3_Programm_3), 4=Cx4_Programm_4 (CM_CHA_Ziel_FahrPr_HSP_Cx4_Programm_4), 5=Cx5_Programm_5 (CM_CHA_Ziel_FahrPr_HSP_Cx5_Programm_5), 6=Cx6_Programm_6 (CM_CHA_Ziel_FahrPr_HSP_Cx6_Programm_6), 7=Cx7_Programm_7 (CM_CHA_Ziel_FahrPr_HSP_Cx7_Programm_7), 8=Cx8_Programm_8 (CM_CHA_Ziel_FahrPr_HSP_Cx8_Programm_8), 9=Cx9_Programm_9 (CM_CHA_Ziel_FahrPr_HSP_Cx9_Programm_9), 10=Cxa_Programm_10 (CM_CHA_Ziel_FahrPr_HSP_Cxa_Programm_10), 11=Cxb_Programm_11 (CM_CHA_Ziel_FahrPr_HSP_Cxb_Programm_11), 12=Cxc_Programm_12 (CM_CHA_Ziel_FahrPr_HSP_Cxc_Programm_12), 13=Cxd_Programm_13 (CM_CHA_Ziel_FahrPr_HSP_Cxd_Programm_13), 14=Cxe_Programm_14 (CM_CHA_Ziel_FahrPr_HSP_Cxe_Programm_14), 15=Cxf_Programm_15 (CM_CHA_Ziel_FahrPr_HSP_Cxf_Programm_15)}, range raw 0..15, transfer-property=TRIGGERED-ON-CHANGE-WITHOUT-REPETITION  # Anforderung Ziel-Fahrprogramm Heckspoiler
          signal CHA_StCurProfDft_XIX_Charisma_03_XIX_E3V_K2CANFD: start 36, 2 bit, little-endian, data-type-policy=OVERRIDE, i-signal-type=PRIMITIVE, init-value=0, base-type=BT_CHA_StCurProfDft, compu {0=Cx0_Init (CM_CHA_StCurProfDft_Cx0_Init), 1=Cx1_profile_is_not_configurable (CM_CHA_StCurProfDft_Cx1_profile_is_not_configurable), 2=Cx2_profile_is_default (CM_CHA_StCurProfDft_Cx2_profile_is_default), 3=Cx3_profile_is_not_default (CM_CHA_StCurProfDft_Cx3_profile_is_not_default)}, range raw 0..3, transfer-property=TRIGGERED-ON-CHANGE-WITHOUT-REPETITION  # Signal indicates if the current Charisma-profile
          signal CHA_Ziel_FahrPr_RWB_XIX_Charisma_03_XIX_E3V_K2CANFD: start 40, 4 bit, little-endian, data-type-policy=OVERRIDE, i-signal-type=PRIMITIVE, init-value=0, base-type=BT_CHA_Ziel_FahrPr_RWB, compu {0=Cx0_keine_Funktion (CM_CHA_Ziel_FahrPr_RWB_Cx0_keine_Funktion), 1=Cx1_Programm_1 (CM_CHA_Ziel_FahrPr_RWB_Cx1_Programm_1), 2=Cx2_Programm_2 (CM_CHA_Ziel_FahrPr_RWB_Cx2_Programm_2), 3=Cx3_Programm_3 (CM_CHA_Ziel_FahrPr_RWB_Cx3_Programm_3), 4=Cx4_Programm_4 (CM_CHA_Ziel_FahrPr_RWB_Cx4_Programm_4), 5=Cx5_Programm_5 (CM_CHA_Ziel_FahrPr_RWB_Cx5_Programm_5), 6=Cx6_Programm_6 (CM_CHA_Ziel_FahrPr_RWB_Cx6_Programm_6), 7=Cx7_Programm_7 (CM_CHA_Ziel_FahrPr_RWB_Cx7_Programm_7), 8=Cx8_Programm_8 (CM_CHA_Ziel_FahrPr_RWB_Cx8_Programm_8), 9=Cx9_Programm_9 (CM_CHA_Ziel_FahrPr_RWB_Cx9_Programm_9), 10=Cxa_Programm_10 (CM_CHA_Ziel_FahrPr_RWB_Cxa_Programm_10), 11=Cxb_Programm_11 (CM_CHA_Ziel_FahrPr_RWB_Cxb_Programm_11), 12=Cxc_Programm_12 (CM_CHA_Ziel_FahrPr_RWB_Cxc_Programm_12), 13=Cxd_Programm_13 (CM_CHA_Ziel_FahrPr_RWB_Cxd_Programm_13), 14=Cxe_Programm_14 (CM_CHA_Ziel_FahrPr_RWB_Cxe_Programm_14), 15=Cxf_Programm_15 (CM_CHA_Ziel_FahrPr_RWB_Cxf_Programm_15)}, range raw 0..15, transfer-property=TRIGGERED-ON-CHANGE-WITHOUT-REPETITION  # Anforderung Zielfahrprogramm Reichweitenberechnung (RWB)
          signal CHA_Ziel_FahrPr_03_01_XIX_Charisma_03_XIX_E3V_K2CANFD: start 44, 4 bit, little-endian, data-type-policy=OVERRIDE, i-signal-type=PRIMITIVE, init-value=0, base-type=BT_CHA_Ziel_FahrPr_03_01, compu {0=Cx0_keine_Funktion (CM_CHA_Ziel_FahrPr_03_01_Cx0_keine_Funktion), 1=Cx1_Programm_1 (CM_CHA_Ziel_FahrPr_03_01_Cx1_Programm_1), 2=Cx2_Programm_2 (CM_CHA_Ziel_FahrPr_03_01_Cx2_Programm_2), 3=Cx3_Programm_3 (CM_CHA_Ziel_FahrPr_03_01_Cx3_Programm_3), 4=Cx4_Programm_4 (CM_CHA_Ziel_FahrPr_03_01_Cx4_Programm_4), 5=Cx5_Programm_5 (CM_CHA_Ziel_FahrPr_03_01_Cx5_Programm_5), 6=Cx6_Programm_6 (CM_CHA_Ziel_FahrPr_03_01_Cx6_Programm_6), 7=Cx7_Programm_7 (CM_CHA_Ziel_FahrPr_03_01_Cx7_Programm_7), 8=Cx8_Programm_8 (CM_CHA_Ziel_FahrPr_03_01_Cx8_Programm_8), 9=Cx9_Programm_9 (CM_CHA_Ziel_FahrPr_03_01_Cx9_Programm_9), 10=Cxa_Programm_10 (CM_CHA_Ziel_FahrPr_03_01_Cxa_Programm_10), 11=Cxb_Programm_11 (CM_CHA_Ziel_FahrPr_03_01_Cxb_Programm_11), 12=Cxc_Programm_12 (CM_CHA_Ziel_FahrPr_03_01_Cxc_Programm_12), 13=Cxd_Programm_13 (CM_CHA_Ziel_FahrPr_03_01_Cxd_Programm_13), 14=Cxe_Programm_14 (CM_CHA_Ziel_FahrPr_03_01_Cxe_Programm_14), 15=Cxf_Programm_15 (CM_CHA_Ziel_FahrPr_03_01_Cxf_Programm_15)}, range raw 0..15, transfer-property=TRIGGERED-ON-CHANGE-WITHOUT-REPETITION  # reserviert für Anforderung Ziel-Fahrprogramm
          signal CHA_Ziel_FahrPr_03_02_XIX_Charisma_03_XIX_E3V_K2CANFD: start 48, 4 bit, little-endian, data-type-policy=OVERRIDE, i-signal-type=PRIMITIVE, init-value=0, base-type=BT_CHA_Ziel_FahrPr_03_02, compu {0=Cx0_keine_Funktion (CM_CHA_Ziel_FahrPr_03_02_Cx0_keine_Funktion), 1=Cx1_Programm_1 (CM_CHA_Ziel_FahrPr_03_02_Cx1_Programm_1), 2=Cx2_Programm_2 (CM_CHA_Ziel_FahrPr_03_02_Cx2_Programm_2), 3=Cx3_Programm_3 (CM_CHA_Ziel_FahrPr_03_02_Cx3_Programm_3), 4=Cx4_Programm_4 (CM_CHA_Ziel_FahrPr_03_02_Cx4_Programm_4), 5=Cx5_Programm_5 (CM_CHA_Ziel_FahrPr_03_02_Cx5_Programm_5), 6=Cx6_Programm_6 (CM_CHA_Ziel_FahrPr_03_02_Cx6_Programm_6), 7=Cx7_Programm_7 (CM_CHA_Ziel_FahrPr_03_02_Cx7_Programm_7), 8=Cx8_Programm_8 (CM_CHA_Ziel_FahrPr_03_02_Cx8_Programm_8), 9=Cx9_Programm_9 (CM_CHA_Ziel_FahrPr_03_02_Cx9_Programm_9), 10=Cxa_Programm_10 (CM_CHA_Ziel_FahrPr_03_02_Cxa_Programm_10), 11=Cxb_Programm_11 (CM_CHA_Ziel_FahrPr_03_02_Cxb_Programm_11), 12=Cxc_Programm_12 (CM_CHA_Ziel_FahrPr_03_02_Cxc_Programm_12), 13=Cxd_Programm_13 (CM_CHA_Ziel_FahrPr_03_02_Cxd_Programm_13), 14=Cxe_Programm_14 (CM_CHA_Ziel_FahrPr_03_02_Cxe_Programm_14), 15=Cxf_Programm_15 (CM_CHA_Ziel_FahrPr_03_02_Cxf_Programm_15)}, range raw 0..15, transfer-property=TRIGGERED-ON-CHANGE-WITHOUT-REPETITION  # reserviert für Anforderung Ziel-Fahrprogramm
          signal CHA_Current_Mode_XIX_Charisma_03_XIX_E3V_K2CANFD: start 52, 4 bit, little-endian, data-type-policy=OVERRIDE, i-signal-type=PRIMITIVE, init-value=0, base-type=BT_CHA_Current_Mode, compu {0=Cx0_keine_Funktion (CM_CHA_Current_Mode_Cx0_keine_Funktion), 1=Cx1_Programm_1 (CM_CHA_Current_Mode_Cx1_Programm_1), 2=Cx2_Programm_2 (CM_CHA_Current_Mode_Cx2_Programm_2), 3=Cx3_Programm_3 (CM_CHA_Current_Mode_Cx3_Programm_3), 4=Cx4_Programm_4 (CM_CHA_Current_Mode_Cx4_Programm_4), 5=Cx5_Programm_5 (CM_CHA_Current_Mode_Cx5_Programm_5), 6=Cx6_Programm_6 (CM_CHA_Current_Mode_Cx6_Programm_6), 7=Cx7_Programm_7 (CM_CHA_Current_Mode_Cx7_Programm_7), 8=Cx8_Programm_8 (CM_CHA_Current_Mode_Cx8_Programm_8), 9=Cx9_Programm_9 (CM_CHA_Current_Mode_Cx9_Programm_9), 10=Cxa_Programm_10 (CM_CHA_Current_Mode_Cxa_Programm_10), 11=Cxb_Programm_11 (CM_CHA_Current_Mode_Cxb_Programm_11), 12=Cxc_Programm_12 (CM_CHA_Current_Mode_Cxc_Programm_12), 13=Cxd_Programm_13 (CM_CHA_Current_Mode_Cxd_Programm_13), 14=Cxe_Programm_14 (CM_CHA_Current_Mode_Cxe_Programm_14), 15=Cxf_Programm_15 (CM_CHA_Current_Mode_Cxf_Programm_15)}, range raw 0..15, transfer-property=TRIGGERED-ON-CHANGE-WITHOUT-REPETITION  # Aktuell eingestelltes Charisma Fahrprogramm
          signal CHA_Ziel_FahrPr_HVBatt_XIX_Charisma_03_XIX_E3V_K2CANFD: start 56, 4 bit, little-endian, data-type-policy=OVERRIDE, i-signal-type=PRIMITIVE, init-value=0, base-type=BT_CHA_Ziel_FahrPr_HVBatt, compu {0=Cx0_keine_Funktion (CM_CHA_Ziel_FahrPr_HVBatt_Cx0_keine_Funktion), 1=Cx1_Programm_1 (CM_CHA_Ziel_FahrPr_HVBatt_Cx1_Programm_1), 2=Cx2_Programm_2 (CM_CHA_Ziel_FahrPr_HVBatt_Cx2_Programm_2), 3=Cx3_Programm_3 (CM_CHA_Ziel_FahrPr_HVBatt_Cx3_Programm_3), 4=Cx4_Programm_4 (CM_CHA_Ziel_FahrPr_HVBatt_Cx4_Programm_4), 5=Cx5_Programm_5 (CM_CHA_Ziel_FahrPr_HVBatt_Cx5_Programm_5), 6=Cx6_Programm_6 (CM_CHA_Ziel_FahrPr_HVBatt_Cx6_Programm_6), 7=Cx7_Programm_7 (CM_CHA_Ziel_FahrPr_HVBatt_Cx7_Programm_7), 8=Cx8_Programm_8 (CM_CHA_Ziel_FahrPr_HVBatt_Cx8_Programm_8), 9=Cx9_Programm_9 (CM_CHA_Ziel_FahrPr_HVBatt_Cx9_Programm_9), 10=Cxa_Programm_10 (CM_CHA_Ziel_FahrPr_HVBatt_Cxa_Programm_10), 11=Cxb_Programm_11 (CM_CHA_Ziel_FahrPr_HVBatt_Cxb_Programm_11), 12=Cxc_Programm_12 (CM_CHA_Ziel_FahrPr_HVBatt_Cxc_Programm_12), 13=Cxd_Programm_13 (CM_CHA_Ziel_FahrPr_HVBatt_Cxd_Programm_13), 14=Cxe_Programm_14 (CM_CHA_Ziel_FahrPr_HVBatt_Cxe_Programm_14), 15=Cxf_Programm_15 (CM_CHA_Ziel_FahrPr_HVBatt_Cxf_Programm_15)}, range raw 0..15, transfer-property=TRIGGERED-ON-CHANGE-WITHOUT-REPETITION  # Signal zur Ansteuerung des Teilnehmers Hochvolt Batterie durch den Charisma-Koordinator
          signal CHA_Kombi_Texte_02_XIX_Charisma_03_XIX_E3V_K2CANFD: start 60, 4 bit, little-endian, data-type-policy=OVERRIDE, i-signal-type=PRIMITIVE, init-value=0, base-type=BT_CHA_Kombi_Texte_02, compu {0=Cx0_Init (CM_CHA_Kombi_Texte_02_Cx0_Init), 1=Cx1_Text_1 (CM_CHA_Kombi_Texte_02_Cx1_Text_1), 2=Cx2_Text_2 (CM_CHA_Kombi_Texte_02_Cx2_Text_2), 3=Cx3_Text_3 (CM_CHA_Kombi_Texte_02_Cx3_Text_3), 4=Cx4_Text_4 (CM_CHA_Kombi_Texte_02_Cx4_Text_4), 5=Cx5_Text_5 (CM_CHA_Kombi_Texte_02_Cx5_Text_5), 6=Cx6_Text_6 (CM_CHA_Kombi_Texte_02_Cx6_Text_6), 7=Cx7_Text_7 (CM_CHA_Kombi_Texte_02_Cx7_Text_7), 8=Cx8_Text_8 (CM_CHA_Kombi_Texte_02_Cx8_Text_8), 9=Cx9_Text_9 (CM_CHA_Kombi_Texte_02_Cx9_Text_9), 10=Cxa_Text_10 (CM_CHA_Kombi_Texte_02_Cxa_Text_10), 11=Cxb_Text_11 (CM_CHA_Kombi_Texte_02_Cxb_Text_11), 12=Cxc_Text_12 (CM_CHA_Kombi_Texte_02_Cxc_Text_12), 13=Cxd_Text_13 (CM_CHA_Kombi_Texte_02_Cxd_Text_13), 14=Cxe_Text_14 (CM_CHA_Kombi_Texte_02_Cxe_Text_14), 15=Cxf_Text_15 (CM_CHA_Kombi_Texte_02_Cxf_Text_15)}, range raw 0..15, transfer-property=TRIGGERED-ON-CHANGE-WITHOUT-REPETITION  # Anzeige von Hinweistexten bzgl. Charismaumschaltungen im Kombi. Die Texte werden HUT-Spezifisch in einem Schnittstellen-LAH definiert.
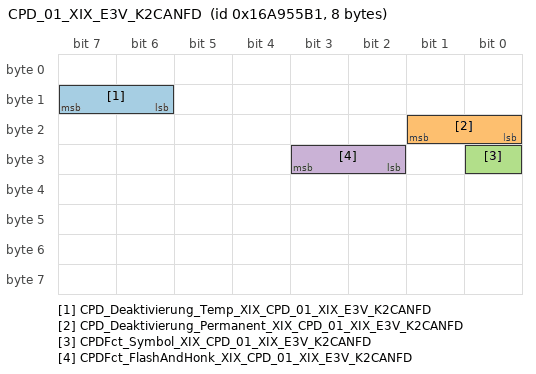
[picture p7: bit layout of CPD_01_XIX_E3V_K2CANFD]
      frame CPD_01_XIX_E3V_K2CANFD: id 0x16A955B1, to SAM, frame-length=8, can-addressing-mode=EXTENDED, can-frame-rx-behavior=CAN-FD, can-frame-tx-behavior=CAN-FD
        pdu CPD_01_XIX_E3V_K2CANFD: length=8, minimum-delay=0.01, transmission-mode-true-timing={cyclic-timing={time-offset=0, time-period=0.2}, event-controlled-timing={number-of-repetitions=0, repetition-period=0.0}}, unused-bit-pattern=0
          signal CPD_Deaktivierung_Temp_XIX_CPD_01_XIX_E3V_K2CANFD: start 14, 2 bit, little-endian, data-type-policy=OVERRIDE, i-signal-type=PRIMITIVE, init-value=0, base-type=BT_CPD_Deaktivierung_Temp, compu {0=Cx0_InitWert (CM_CPD_Deaktivierung_Temp_Cx0_InitWert), 1=Cx1_keine_Deaktivierung_Temp (CM_CPD_Deaktivierung_Temp_Cx1_keine_Deaktivierung_Temp), 2=Cx2_CPD_Deaktivierung_Temp (CM_CPD_Deaktivierung_Temp_Cx2_CPD_Deaktivierung_Temp)}, range raw 0..2, transfer-property=TRIGGERED-ON-CHANGE-WITHOUT-REPETITION  # Status der temporären Deaktivierung der CPD-Funktin zur Anzeige in der App
          signal CPD_Deaktivierung_Permanent_XIX_CPD_01_XIX_E3V_K2CANFD: start 16, 2 bit, little-endian, data-type-policy=OVERRIDE, i-signal-type=PRIMITIVE, init-value=0, base-type=BT_CPD_Deaktivierung_Permanent, compu {0=Cx0_InitWert (CM_CPD_Deaktivierung_Permanent_Cx0_InitWert), 1=Cx1_keine_Deaktivierung_Permanent (CM_CPD_Deaktivierung_Permanent_Cx1_keine_Deaktivierung_Permanent), 2=Cx2_CPD_Deaktivierung_Permanent (CM_CPD_Deaktivierung_Permanent_Cx2_CPD_Deaktivierung_Permanent)}, range raw 0..2, transfer-property=TRIGGERED-ON-CHANGE-WITHOUT-REPETITION  # Status der permanenten Deaktivierung der CPD-Warnung zur Anzeige (z.B. in der App)
          signal CPDFct_Symbol_XIX_CPD_01_XIX_E3V_K2CANFD: start 24, 1 bit, little-endian, data-type-policy=OVERRIDE, i-signal-type=PRIMITIVE, init-value=0, base-type=BT_CPDFct_Symbol, compu {0=Cx0_Keine_Anzeige (CM_CPDFct_Symbol_Cx0_Keine_Anzeige), 1=Cx1_aktiv (CM_CPDFct_Symbol_Cx1_aktiv)}, range raw 0..1, transfer-property=PENDING  # Status der CPD Kontrollleuchte Fkt CPD 2.1
          signal CPDFct_FlashAndHonk_XIX_CPD_01_XIX_E3V_K2CANFD: start 26, 2 bit, little-endian, data-type-policy=OVERRIDE, i-signal-type=PRIMITIVE, init-value=0, base-type=BT_CPDFct_FlashAndHonk, compu {0=Cx0_Keine_Warnung (CM_CPDFct_FlashAndHonk_Cx0_Keine_Warnung), 1=Cx1_CPD_Blinken (CM_CPDFct_FlashAndHonk_Cx1_CPD_Blinken), 2=Cx2_CPD_Blinken_Hupen (CM_CPDFct_FlashAndHonk_Cx2_CPD_Blinken_Hupen)}, range raw 0..2, transfer-property=PENDING, to SAM(timeout 2 s)  # Signal um das Horn als Warnsignal für CPD zu benutzen
      frame DEV_BCM_DebugInfo_Tx_09_XIX_E3V_K2CANFD: id 0x1BFC7209, from SAM, frame-length=8, can-addressing-mode=EXTENDED, can-frame-rx-behavior=CAN-FD, can-frame-tx-behavior=CAN-FD
        user defined pdu CDD_DEV_BCM_DebugInfo_Tx_09_XIX_E3V_K2CANFD: length=8, cdd-type=EID
      frame DEV_BCM_DebugInfo_Tx_0A_XIX_E3V_K2CANFD: id 0x1BFC720A, from SAM, frame-length=8, can-addressing-mode=EXTENDED, can-frame-rx-behavior=CAN-FD, can-frame-tx-behavior=CAN-FD
        user defined pdu CDD_DEV_BCM_DebugInfo_Tx_0A_XIX_E3V_K2CANFD: length=8, cdd-type=EID
      frame DEV_BCM_Req_01_XIX_E3V_K2CANFD: id 0x1BFC7200, to SAM, frame-length=8, can-addressing-mode=EXTENDED, can-frame-rx-behavior=CAN-FD, can-frame-tx-behavior=CAN-FD
        user defined pdu CDD_DEV_BCM_Req_01_XIX_E3V_K2CANFD: length=8, cdd-type=EID
      frame DEV_BCM_Resp_01_XIX_E3V_K2CANFD: id 0x1BFC7201, from SAM, frame-length=8, can-addressing-mode=EXTENDED, can-frame-rx-behavior=CAN-FD, can-frame-tx-behavior=CAN-FD
        user defined pdu CDD_DEV_BCM_Resp_01_XIX_E3V_K2CANFD: length=8, cdd-type=EID
      frame DEV_BCM_Resp_02_XIX_E3V_K2CANFD: id 0x1BFC7202, from SAM, frame-length=8, can-addressing-mode=EXTENDED, can-frame-rx-behavior=CAN-FD, can-frame-tx-behavior=CAN-FD
        user defined pdu CDD_DEV_BCM_Resp_02_XIX_E3V_K2CANFD: length=8, cdd-type=EID
      frame DEV_BCM_Resp_03_XIX_E3V_K2CANFD: id 0x1BFC7203, from SAM, frame-length=8, can-addressing-mode=EXTENDED, can-frame-rx-behavior=CAN-FD, can-frame-tx-behavior=CAN-FD
        user defined pdu CDD_DEV_BCM_Resp_03_XIX_E3V_K2CANFD: length=8, cdd-type=EID
      frame DEV_BCM_Resp_04_XIX_E3V_K2CANFD: id 0x1BFC7204, from SAM, frame-length=8, can-addressing-mode=EXTENDED, can-frame-rx-behavior=CAN-FD, can-frame-tx-behavior=CAN-FD
        user defined pdu CDD_DEV_BCM_Resp_04_XIX_E3V_K2CANFD: length=8, cdd-type=EID
      frame DEV_BCM_Resp_05_XIX_E3V_K2CANFD: id 0x1BFC7205, from SAM, frame-length=8, can-addressing-mode=EXTENDED, can-frame-rx-behavior=CAN-FD, can-frame-tx-behavior=CAN-FD
        user defined pdu CDD_DEV_BCM_Resp_05_XIX_E3V_K2CANFD: length=8, cdd-type=EID
      frame DEV_BCM_Resp_06_XIX_E3V_K2CANFD: id 0x1BFC7206, from SAM, frame-length=8, can-addressing-mode=EXTENDED, can-frame-rx-behavior=CAN-FD, can-frame-tx-behavior=CAN-FD
        user defined pdu CDD_DEV_BCM_Resp_06_XIX_E3V_K2CANFD: length=8, cdd-type=EID
      frame DEV_BCM_Resp_07_XIX_E3V_K2CANFD: id 0x1BFC7207, from SAM, frame-length=8, can-addressing-mode=EXTENDED, can-frame-rx-behavior=CAN-FD, can-frame-tx-behavior=CAN-FD
        user defined pdu CDD_DEV_BCM_Resp_07_XIX_E3V_K2CANFD: length=8, cdd-type=EID
      frame DEV_BCM_Resp_08_XIX_E3V_K2CANFD: id 0x1BFC7208, from SAM, frame-length=8, can-addressing-mode=EXTENDED, can-frame-rx-behavior=CAN-FD, can-frame-tx-behavior=CAN-FD
        user defined pdu CDD_DEV_BCM_Resp_08_XIX_E3V_K2CANFD: length=8, cdd-type=EID
      frame DEV_BCM_Resp_11_XIX_E3V_K2CANFD: id 0x1BFC720B, from SAM, frame-length=8, can-addressing-mode=EXTENDED, can-frame-rx-behavior=CAN-FD, can-frame-tx-behavior=CAN-FD
        user defined pdu CDD_DEV_BCM_Resp_11_XIX_E3V_K2CANFD: length=8, cdd-type=EID
      frame DEV_BCM_Resp_12_XIX_E3V_K2CANFD: id 0x1BFC720C, from SAM, frame-length=8, can-addressing-mode=EXTENDED, can-frame-rx-behavior=CAN-FD, can-frame-tx-behavior=CAN-FD
        user defined pdu CDD_DEV_BCM_Resp_12_XIX_E3V_K2CANFD: length=8, cdd-type=EID
      frame DEV_BCM_Resp_13_XIX_E3V_K2CANFD: id 0x1BFC720D, from SAM, frame-length=8, can-addressing-mode=EXTENDED, can-frame-rx-behavior=CAN-FD, can-frame-tx-behavior=CAN-FD
        user defined pdu CDD_DEV_BCM_Resp_13_XIX_E3V_K2CANFD: length=8, cdd-type=EID
      frame DEV_BCM_Resp_14_XIX_E3V_K2CANFD: id 0x1BFC720E, from SAM, frame-length=8, can-addressing-mode=EXTENDED, can-frame-rx-behavior=CAN-FD, can-frame-tx-behavior=CAN-FD
        user defined pdu CDD_DEV_BCM_Resp_14_XIX_E3V_K2CANFD: length=8, cdd-type=EID
      frame DEV_BCM_Resp_15_XIX_E3V_K2CANFD: id 0x1BFC720F, from SAM, frame-length=8, can-addressing-mode=EXTENDED, can-frame-rx-behavior=CAN-FD, can-frame-tx-behavior=CAN-FD
        user defined pdu CDD_DEV_BCM_Resp_15_XIX_E3V_K2CANFD: length=8, cdd-type=EID
      frame DEV_BCM_Resp_16_XIX_E3V_K2CANFD: id 0x1BFC7210, from SAM, frame-length=64, can-addressing-mode=EXTENDED, can-frame-rx-behavior=CAN-FD, can-frame-tx-behavior=CAN-FD
        user defined pdu CDD_DEV_BCM_Resp_16_XIX_E3V_K2CANFD: length=64, cdd-type=EID
      frame DEV_BCM_Resp_17_XIX_E3V_K2CANFD: id 0x1BFC7211, from SAM, frame-length=64, can-addressing-mode=EXTENDED, can-frame-rx-behavior=CAN-FD, can-frame-tx-behavior=CAN-FD
        user defined pdu CDD_DEV_BCM_Resp_17_XIX_E3V_K2CANFD: length=64, cdd-type=EID
      frame DIA_WWS2_Req_XIX_E3V_K2CANFD: id 0x17FC176E, to SAM, frame-length=8, can-addressing-mode=EXTENDED, can-frame-rx-behavior=CAN-FD, can-frame-tx-behavior=CAN-FD
        n pdu DIA_WWS2_Req_XIX_E3V_K2CANFD: length=8
      frame DIA_WWS2_Resp_XIX_E3V_K2CANFD: id 0x17FE176E, from SAM, frame-length=8, can-addressing-mode=EXTENDED, can-frame-rx-behavior=CAN-FD, can-frame-tx-behavior=CAN-FD
        n pdu DIA_WWS2_Resp_XIX_E3V_K2CANFD: length=8
      frame DIA_WWS_Req_XIX_E3V_K2CANFD: id 0x17FC1601, to SAM, frame-length=8, can-addressing-mode=EXTENDED, can-frame-rx-behavior=CAN-FD, can-frame-tx-behavior=CAN-FD
        n pdu DIA_WWS_Req_XIX_E3V_K2CANFD: length=8
      frame DIA_WWS_Resp_XIX_E3V_K2CANFD: id 0x17FE1601, from SAM, frame-length=8, can-addressing-mode=EXTENDED, can-frame-rx-behavior=CAN-FD, can-frame-tx-behavior=CAN-FD
        n pdu DIA_WWS_Resp_XIX_E3V_K2CANFD: length=8
